VERSION "HNNBNNNYNNNNNNNNNNNNNNNNNNNNNNNNNNNNNNNNNN/4/%%%/4/'%**4NNN///"

NS_ :

BS_:

BU_: BAP_Tester BMS_NV_12V Gateway_Max Klima

BO_ 2463978703 HVLM_GBT_01: 64 Gateway_Max
 SG_ HVLM_GBT_01_BZ : 8|4@1+ (1,0) [0|15] ""  Vector__XXX
 SG_ HVLM_GBT_01_Sendestatus : 12|1@1+ (1.0,0.0) [0.0|1] ""  Vector__XXX
 SG_ HVLM_GBT_Status_Control : 13|1@1+ (1.0,0.0) [0.0|1] ""  Vector__XXX
 SG_ HVLM_GBT_SendeAnf_BCL : 14|1@1+ (1.0,0.0) [0.0|1] ""  Vector__XXX
 SG_ HVLM_GBT_SendeAnf_BCP : 15|1@1+ (1.0,0.0) [0.0|1] ""  Vector__XXX
 SG_ HVLM_GBT_SendeAnf_BCS : 16|1@1+ (1.0,0.0) [0.0|1] ""  Vector__XXX
 SG_ HVLM_GBT_SendeAnf_BEM : 17|1@1+ (1.0,0.0) [0.0|1] ""  Vector__XXX
 SG_ HVLM_GBT_SendeAnf_BHM : 18|1@1+ (1.0,0.0) [0.0|1] ""  Vector__XXX
 SG_ HVLM_GBT_SendeAnf_BRM : 19|1@1+ (1.0,0.0) [0.0|1] ""  Vector__XXX
 SG_ HVLM_GBT_SendeAnf_BRO : 20|1@1+ (1.0,0.0) [0.0|1] ""  Vector__XXX
 SG_ HVLM_GBT_SendeAnf_BSD : 21|1@1+ (1.0,0.0) [0.0|1] ""  Vector__XXX
 SG_ HVLM_GBT_SendeAnf_BSM : 22|1@1+ (1.0,0.0) [0.0|1] ""  Vector__XXX
 SG_ HVLM_GBT_SendeAnf_BST : 23|1@1+ (1.0,0.0) [0.0|1] ""  Vector__XXX
 SG_ HVLM_GBT_HvBatt_MaxLadespannung : 24|14@1+ (0.1,0) [0.0|1500.0] "Unit_Volt"  Vector__XXX
 SG_ HVLM_GBT_BEM_Timeout_CCS : 50|2@1+ (1.0,0.0) [0.0|3] ""  Vector__XXX
 SG_ HVLM_GBT_BEM_Timeout_CML : 52|2@1+ (1.0,0.0) [0.0|3] ""  Vector__XXX
 SG_ HVLM_GBT_BEM_Timeout_CRMnReady : 54|2@1+ (1.0,0.0) [0.0|3] ""  Vector__XXX
 SG_ HVLM_GBT_BEM_Timeout_CRMReady : 56|2@1+ (1.0,0.0) [0.0|3] ""  Vector__XXX
 SG_ HVLM_GBT_BEM_Timeout_CRO : 58|2@1+ (1.0,0.0) [0.0|3] ""  Vector__XXX
 SG_ HVLM_GBT_BEM_Timeout_CSD : 60|2@1+ (1.0,0.0) [0.0|3] ""  Vector__XXX
 SG_ HVLM_GBT_BEM_Timeout_CST : 62|2@1+ (1.0,0.0) [0.0|3] ""  Vector__XXX
 SG_ HVLM_GBT_BCL_Sollspannung : 64|14@1+ (0.1,0) [0.0|1500.0] "Unit_Volt"  Vector__XXX
 SG_ HVLM_GBT_BCL_Ladeverfahren : 78|2@1+ (1.0,0.0) [0.0|3] ""  Vector__XXX
 SG_ HVLM_GBT_BCL_Sollstrom : 80|14@1+ (0.1,-400) [-400.0|1000.0] "Unit_Amper"  Vector__XXX
 SG_ HVLM_GBT_BCP_StartSOC : 94|10@1+ (0.1,0) [0.0|100.0] "Unit_PerCent"  Vector__XXX
 SG_ HVLM_GBT_BCP_Ist_Spannung_HvBatt : 104|14@1+ (0.1,0) [0.0|1500.0] "Unit_Volt"  Vector__XXX
 SG_ HVLM_GBT_BCP_MaxLadestrom_Fzg : 118|14@1+ (0.1,-400) [-400.0|1000.0] "Unit_Amper"  Vector__XXX
 SG_ HVLM_GBT_BCP_MaxZellladespannung : 132|12@1+ (0.01,0) [0.00|24.00] "Unit_Volt"  Vector__XXX
 SG_ HVLM_GBT_BCP_MaxTemperatur : 144|8@1+ (1,-50) [-50|200] "Unit_DegreCelsi"  Vector__XXX
 SG_ HVLM_GBT_BCP_Nennenergiegehalt : 152|14@1+ (0.1,0) [0.0|1000.0] "Unit_KiloWattHour"  Vector__XXX
 SG_ HVLM_GBT_BCS_Ist_Restladezeit : 166|10@1+ (1,0) [0|600] "Unit_Minut"  Vector__XXX
 SG_ HVLM_GBT_BCS_Ist_Ladespannung : 176|14@1+ (0.1,0) [0.0|1500.0] "Unit_Volt"  Vector__XXX
 SG_ HVLM_GBT_BCS_Ist_Ladestrom : 190|14@1+ (0.1,-400) [-400.0|1000.0] "Unit_Amper"  Vector__XXX
 SG_ HVLM_GBT_BCS_IstSOC : 204|7@1+ (1,0) [0|100] "Unit_PerCent"  Vector__XXX
 SG_ HVLM_GBT_BCS_GruppenNr_Uzellmax : 211|5@1+ (1,0) [0|16] "Unit_None"  Vector__XXX
 SG_ HVLM_GBT_BCS_Ist_MaxZellspannung : 216|12@1+ (0.01,0) [0.00|24.00] "Unit_Volt"  Vector__XXX
 SG_ HVLM_GBT_BRM_Nennkapazitaet : 228|12@1+ (0.1,0) [0.0|250.0] "Unit_AmperHour"  Vector__XXX
 SG_ HVLM_GBT_BRM_Batterietyp : 240|8@1+ (1.0,0.0) [0.0|255] ""  Vector__XXX
 SG_ HVLM_GBT_BRM_ProtokollVersion : 248|24@1+ (1,0) [0|16777215] "Unit_None"  Vector__XXX
 SG_ HVLM_GBT_BRM_Nennspannung_HvBatt : 272|14@1+ (0.1,0) [0.0|1500.0] "Unit_Volt"  Vector__XXX
 SG_ HVLM_GBT_BRO_FzgBereitschaft : 288|8@1+ (1.0,0.0) [0.0|255] ""  Vector__XXX
 SG_ HVLM_GBT_BSD_EndSOC : 296|7@1+ (1,0) [0|100] "Unit_PerCent"  Vector__XXX
 SG_ HVLM_GBT_BSM_FzgLadeerlaubnis : 303|1@1+ (1.0,0.0) [0.0|1] ""  Vector__XXX
 SG_ HVLM_GBT_BSD_MaxTemperatur : 304|8@1+ (1,-50) [-50|200] "Unit_DegreCelsi"  Vector__XXX
 SG_ HVLM_GBT_BSD_MinTemperatur : 312|8@1+ (1,-50) [-50|200] "Unit_DegreCelsi"  Vector__XXX
 SG_ HVLM_GBT_BSD_MaxZellspannung : 320|12@1+ (0.01,0) [0.00|24.00] "Unit_Volt"  Vector__XXX
 SG_ HVLM_GBT_BSD_MinZellspannung : 332|12@1+ (0.01,0) [0.00|24.00] "Unit_Volt"  Vector__XXX
 SG_ HVLM_GBT_BSM_Ist_MaxTemperatur : 344|8@1+ (1,-50) [-50|200] "Unit_DegreCelsi"  Vector__XXX
 SG_ HVLM_GBT_BSM_Ist_MinTemperatur : 352|8@1+ (1,-50) [-50|200] "Unit_DegreCelsi"  Vector__XXX
 SG_ HVLM_GBT_BSM_Messpunkt_MaxT : 360|7@1+ (1,1) [1|128] "Unit_None"  Vector__XXX
 SG_ HVLM_GBT_BSM_Messpunkt_MinT : 367|7@1+ (1,1) [1|128] "Unit_None"  Vector__XXX
 SG_ HVLM_GBT_BSM_Status_Iso : 374|2@1+ (1.0,0.0) [0.0|3] ""  Vector__XXX
 SG_ HVLM_GBT_BSM_Nr_MaxZellspannung : 376|8@1+ (1,1) [1|256] "Unit_None"  Vector__XXX
 SG_ HVLM_GBT_BSM_Status_SOC : 384|2@1+ (1.0,0.0) [0.0|3] ""  Vector__XXX
 SG_ HVLM_GBT_BSM_Status_Stecker : 386|2@1+ (1.0,0.0) [0.0|3] ""  Vector__XXX
 SG_ HVLM_GBT_BSM_Status_Strom : 388|2@1+ (1.0,0.0) [0.0|3] ""  Vector__XXX
 SG_ HVLM_GBT_BSM_Status_Temperatur : 390|2@1+ (1.0,0.0) [0.0|3] ""  Vector__XXX
 SG_ HVLM_GBT_BSM_Status_Zellspannung : 392|2@1+ (1.0,0.0) [0.0|3] ""  Vector__XXX
 SG_ HVLM_GBT_BCS_GroupNr_Uzellmax_v2 : 480|4@1+ (1,0) [0|15] "Unit_None"  Vector__XXX
 SG_ HVLM_GBT_BST_Ladeende_Fehler_I : 484|2@1+ (1.0,0.0) [0.0|3] ""  Vector__XXX
 SG_ HVLM_GBT_BST_Ladeende_Fehler_U : 486|2@1+ (1.0,0.0) [0.0|3] ""  Vector__XXX
 SG_ HVLM_GBT_BST_Ladeende_Fehler1 : 488|2@1+ (1.0,0.0) [0.0|3] ""  Vector__XXX
 SG_ HVLM_GBT_BST_Ladeende_Fehler2 : 490|2@1+ (1.0,0.0) [0.0|3] ""  Vector__XXX
 SG_ HVLM_GBT_BST_Ladeende_Fehler3 : 492|2@1+ (1.0,0.0) [0.0|3] ""  Vector__XXX
 SG_ HVLM_GBT_BST_Ladeende_Fehler4 : 494|2@1+ (1.0,0.0) [0.0|3] ""  Vector__XXX
 SG_ HVLM_GBT_BST_Ladeende_Fehler5 : 496|2@1+ (1.0,0.0) [0.0|3] ""  Vector__XXX
 SG_ HVLM_GBT_BST_Ladeende_Fehler6 : 498|2@1+ (1.0,0.0) [0.0|3] ""  Vector__XXX
 SG_ HVLM_GBT_BST_Ladeende_Fehler7 : 500|2@1+ (1.0,0.0) [0.0|3] ""  Vector__XXX
 SG_ HVLM_GBT_BST_Ladeende_Fehler8 : 502|2@1+ (1.0,0.0) [0.0|3] ""  Vector__XXX
 SG_ HVLM_GBT_BST_Ladeende1_Fahrzeug : 504|2@1+ (1.0,0.0) [0.0|3] ""  Vector__XXX
 SG_ HVLM_GBT_BST_Ladeende2_Fahrzeug : 506|2@1+ (1.0,0.0) [0.0|3] ""  Vector__XXX
 SG_ HVLM_GBT_BST_Ladeende3_Fahrzeug : 508|2@1+ (1.0,0.0) [0.0|3] ""  Vector__XXX
 SG_ HVLM_GBT_BST_Ladeende4_Fahrzeug : 510|2@1+ (1.0,0.0) [0.0|3] ""  Vector__XXX

BO_ 2463978877 HVLM_GBT_01_SOK_Signatur_02: 8 Gateway_Max
 SG_ SOK_HVLM_GBT_01_Signatur_02 : 0|64@1+ (1,0) [1|18446744073709551615] "Unit_None"  Vector__XXX

BO_ 2463978707 HVLM_PLC_01: 24 Gateway_Max
 SG_ HVLM_PLC_01_BZ : 8|4@1+ (1,0) [0|15] ""  Vector__XXX
 SG_ HVLM_PlcModemAktivieren : 12|2@1+ (1.0,0.0) [0.0|3] ""  Vector__XXX
 SG_ HVLM_ZahlungsmethodeFzgPlc : 14|2@1+ (1.0,0.0) [0.0|3] ""  Vector__XXX
 SG_ HVLM_maxLadestromFzgPlc : 16|13@1+ (0.1,-400) [-400.0|400.0] "Unit_Amper"  Vector__XXX
 SG_ HVLM_TLS_PnC_Authenfizierung : 29|3@1+ (1.0,0.0) [0.0|7] ""  Vector__XXX
 SG_ HVLM_SollstromFzgPlc_2 : 32|14@1+ (0.1,-400) [-400.0|1000.0] "Unit_Amper"  Vector__XXX
 SG_ HVLM_PlcKommLadedose : 46|2@1+ (1.0,0.0) [0.0|3] ""  Vector__XXX
 SG_ HVLM_ZielladespannungFzgPlc : 48|14@1+ (0.1,0) [0.0|1500.0] "Unit_Volt"  Vector__XXX
 SG_ HVLM_PlcAnforderung : 62|2@1+ (1.0,0.0) [0.0|3] ""  Vector__XXX
 SG_ HVLM_RestladezeitFzgPlc : 64|12@1+ (1,0) [0|2880] "Unit_Minut"  Vector__XXX
 SG_ HVLM_RestladezeitTeilladungPlc : 76|12@1+ (1,0) [0|2880] "Unit_Minut"  Vector__XXX
 SG_ HVLM_LadezustandHvBatFzgPlc : 88|7@1+ (1,0) [0|100] "Unit_PerCent"  Vector__XXX
 SG_ HVLM_LadebereitFzgPlc : 95|1@1+ (1.0,0.0) [0.0|1] ""  Vector__XXX
 SG_ HVLM_maxLadespannungFzgPlc : 96|14@1+ (0.1,0) [0.0|1500.0] "Unit_Volt"  Vector__XXX
 SG_ HVLM_LadeartAnfFzgPlc : 110|3@1+ (1.0,0.0) [0.0|7] ""  Vector__XXX
 SG_ HVLM_MsgTriggerFzgPlc : 113|7@1+ (1.0,0.0) [0.0|127] ""  Vector__XXX
 SG_ HVLM_FehlerFzgPlc : 120|4@1+ (1.0,0.0) [0.0|15] ""  Vector__XXX
 SG_ HVLM_ReadyToChargeState : 124|2@1+ (1.0,0.0) [0.0|3] ""  Vector__XXX
 SG_ HVLM_LadenAbgeschlPlc : 126|2@1+ (1.0,0.0) [0.0|3] ""  Vector__XXX
 SG_ HVLM_LadeSessionPlc : 128|2@1+ (1.0,0.0) [0.0|3] ""  Vector__XXX
 SG_ HVLM_minLadestromFzgPlc : 130|10@1+ (0.1,0) [0.0|63.0] "Unit_Amper"  Vector__XXX
 SG_ HVLM_NormFzgPlc : 140|3@1+ (1.0,0.0) [0.0|7] ""  Vector__XXX
 SG_ HVLM_AnforderungPLTabellen : 143|1@1+ (1.0,0.0) [0.0|1] ""  Vector__XXX
 SG_ HVLM_maxLadestromFzgPlc_2 : 144|14@1+ (0.1,-400) [-400.0|1000.0] "Unit_Amper"  Vector__XXX

BO_ 2463978798 HVLM_PLC_01_SOK_Signatur: 4 Gateway_Max
 SG_ SOK_HVLM_PLC_01_Signatur : 0|32@1+ (1,0) [1|4294967295] "Unit_None"  Vector__XXX

BO_ 2589283690 IPB_03: 16 Vector__XXX
 SG_ LAD_OBD_Lampe_Anf : 23|1@1+ (1.0,0.0) [0.0|1] ""  Gateway_Max
 SG_ IPB_ThermAuslastungsgrad : 24|8@1+ (1,0) [0|100] "Unit_PerCent"  Gateway_Max
 SG_ TNV_Temperatur : 32|8@1+ (1,-40) [-40|213] "Unit_PerCent"  Gateway_Max
 SG_ IPB_Wasser_TEMP_EIN : 40|8@1+ (1,-40) [-40|213] "Unit_DegreCelsi"  Gateway_Max
 SG_ IPB_Wasser_TEMP_AUS : 48|8@1+ (1,-40) [-40|213] "Unit_DegreCelsi"  Gateway_Max
 SG_ HVLE_Temperatur : 56|8@1+ (1,-40) [-40|213] "Unit_DegreCelsi"  Gateway_Max
 SG_ HVLE_ThermAuslastungsgrad : 64|8@1+ (1,0) [0|100] "Unit_PerCent"  Gateway_Max
 SG_ HVLE_eTM_max_Vorlauftemperatur : 72|8@1+ (1,-40) [-40|213] "Unit_DegreCelsi"  Gateway_Max
 SG_ OBDProtocol_Ladegeraet : 88|8@1+ (1.0,0.0) [0.0|255] ""  Gateway_Max

BO_ 2589283695 IPB_03_SOK_Signatur: 8 Vector__XXX
 SG_ SOK_IPB_03_Signatur : 0|64@1+ (1,0) [1|18446744073709551615] "Unit_None"  Gateway_Max

BO_ 1857 ISO_DCDC_Req: 8 Gateway_Max
 SG_ ISO_DCDC_Req_Data : 0|64@1+ (1.0,0.0) [0.0|18446744073709551615] ""  Vector__XXX

BO_ 1963 ISO_DCDC_Resp: 8 Vector__XXX
 SG_ ISO_DCDC_Resp_Data : 0|64@1+ (1.0,0.0) [0.0|18446744073709551615] ""  Gateway_Max

BO_ 1792 ISO_Funktionaler_Req_All: 8 Gateway_Max
 SG_ ISO_ALL_01_Req_Data : 0|64@1+ (1.0,0.0) [0.0|18446744073709551615] ""  BMS_NV_12V,Klima

BO_ 1862 ISO_Klima_Req: 8 Gateway_Max
 SG_ ISO_Klima_Req_Data : 0|64@1+ (1.0,0.0) [0.0|18446744073709551615] ""  Klima

BO_ 1968 ISO_Klima_Resp: 8 Klima
 SG_ ISO_Klima_Resp_Data : 0|64@1+ (1.0,0.0) [0.0|18446744073709551615] ""  Gateway_Max

BO_ 1860 ISO_Ladegeraet_Req: 8 Gateway_Max
 SG_ ISO_Ladegeraet_Req_Data : 0|64@1+ (1.0,0.0) [0.0|18446744073709551615] ""  Vector__XXX

BO_ 1966 ISO_Ladegeraet_Resp: 8 Vector__XXX
 SG_ ISO_Ladegeraet_Resp_Data : 0|64@1+ (1.0,0.0) [0.0|18446744073709551615] ""  Gateway_Max

BO_ 2463978775 ISOND_01: 64 Vector__XXX
 SG_ HVLX_Isond_maxAcEigenstromL1 : 12|10@1+ (0.1,0) [0.0|100.0] "Unit_Amper"  Gateway_Max
 SG_ HVLX_Isond_maxAcEigenstromL2 : 22|10@1+ (0.1,0) [0.0|100.0] "Unit_Amper"  Gateway_Max
 SG_ HVLX_Isond_maxAcEigenstromL3 : 32|10@1+ (0.1,0) [0.0|100.0] "Unit_Amper"  Gateway_Max
 SG_ HVLX_Isond_maxAcAbgabestromL1 : 42|10@1+ (0.1,0) [0.0|100.0] "Unit_Amper"  Gateway_Max
 SG_ HVLX_Isond_maxAcAbgabestromL2 : 52|10@1+ (0.1,0) [0.0|100.0] "Unit_Amper"  Gateway_Max
 SG_ HVLX_Isond_maxAcAbgabestromL3 : 62|10@1+ (0.1,0) [0.0|100.0] "Unit_Amper"  Gateway_Max
 SG_ HVLX_Isond_MaxStromACLsPlc : 72|10@1+ (0.1,0) [0.0|100.0] "Unit_Amper"  Gateway_Max
 SG_ HVLX_Isond_maxStromLadesaeule : 82|14@1+ (0.1,-400) [-400.0|1000.0] "Unit_Amper"  Gateway_Max
 SG_ HVLX_Isond_minStromLadesaeule : 96|14@1+ (0.1,-400) [-400.0|1000.0] "Unit_Amper"  Gateway_Max
 SG_ HVLX_Isond_maxSpannungLadesaeule : 110|14@1+ (0.1,0) [0.0|1500.0] "Unit_Volt"  Gateway_Max
 SG_ HVLX_Isond_minSpannungLadesaeule : 124|14@1+ (0.1,0) [0.0|1500.0] "Unit_Volt"  Gateway_Max
 SG_ HVLX_Isond_IstSpannungLadesaeule : 138|14@1+ (0.1,0) [0.0|1500.0] "Unit_Volt"  Gateway_Max
 SG_ HVLX_Isond_IstStromLadesaeule : 152|14@1+ (0.1,-400) [-400.0|1000.0] "Unit_Amper"  Gateway_Max
 SG_ HVLX_Isond_StromrippelPeakLs : 166|12@1+ (0.1,0) [0.0|300.0] "Unit_Amper"  Gateway_Max
 SG_ HVLX_Isond_IstSpannungACLsPlc : 178|9@1+ (1,0) [0|500] "Unit_Volt"  Gateway_Max
 SG_ HVLX_Isond_maxLeistungLadesaeule : 187|17@1+ (10,-327670) [-327670|972330] "Unit_Watt"  Gateway_Max
 SG_ HVLX_Isond_maxStromErreicht : 204|2@1+ (1.0,0.0) [0.0|3] ""  Gateway_Max
 SG_ HVLX_Isond_maxSpannungErreicht : 206|2@1+ (1.0,0.0) [0.0|3] ""  Gateway_Max
 SG_ HVLX_Isond_maxLeistungErreicht : 208|2@1+ (1.0,0.0) [0.0|3] ""  Gateway_Max
 SG_ HVLX_Isond_NormLsPlc : 210|3@1+ (1.0,0.0) [0.0|7] ""  Gateway_Max
 SG_ HVLX_Isond_TLS_PnC_Status : 213|3@1+ (1.0,0.0) [0.0|7] ""  Gateway_Max
 SG_ HVLX_Isond_ResponseCodeLsPlc : 216|6@1+ (1.0,0.0) [0.0|63] ""  Gateway_Max
 SG_ HVLX_Isond_IsoStatusLadesaeule : 222|2@1+ (1.0,0.0) [0.0|3] ""  Gateway_Max
 SG_ HVLX_Isond_PlcKommFehler : 224|3@1+ (1.0,0.0) [0.0|7] ""  Gateway_Max
 SG_ HVLX_ISOND_LOPStatus : 227|1@1+ (1.0,0.0) [0.0|1] ""  Vector__XXX
 SG_ HVLX_ISOND_FODStatus : 228|1@1+ (1.0,0.0) [0.0|1] ""  Vector__XXX
 SG_ HVLX_Isond_LadeartAC1PCorePlc : 229|1@1+ (1.0,0.0) [0.0|1] ""  Gateway_Max
 SG_ HVLX_Isond_LadeartAC3PCorePlc : 230|1@1+ (1.0,0.0) [0.0|1] ""  Gateway_Max
 SG_ HVLX_Isond_LadeartDCComboCorePlc : 231|1@1+ (1.0,0.0) [0.0|1] ""  Gateway_Max
 SG_ HVLX_Isond_LadeartDCCorePlc : 232|1@1+ (1.0,0.0) [0.0|1] ""  Gateway_Max
 SG_ HVLX_Isond_LadeartDCExtendedPlc : 233|1@1+ (1.0,0.0) [0.0|1] ""  Gateway_Max
 SG_ HVLX_Isond_LadeartDCUniquePlc : 234|1@1+ (1.0,0.0) [0.0|1] ""  Gateway_Max
 SG_ HVLX_Isond_ZahlungsmethodeLs : 235|2@1+ (1.0,0.0) [0.0|3] ""  Gateway_Max
 SG_ HVLX_Isond_StatusRcdACLsPlc : 237|2@1+ (1.0,0.0) [0.0|3] ""  Gateway_Max
 SG_ HVLX_Isond_ZahlererfassungAnfHlc : 239|1@1+ (1.0,0.0) [0.0|1] ""  Gateway_Max
 SG_ HVLX_Isond_PLC_Message_Status : 240|8@1+ (1.0,0.0) [0.0|255] ""  Gateway_Max
 SG_ HVLX_Isond_IstEnergiemengeLsPlc : 248|13@1+ (0.1,-400) [-400.0|400.0] "Unit_KiloWattHour"  Vector__XXX
 SG_ HVLX_Isond_PnCZertifkatErhaltHlc : 262|2@1+ (1.0,0.0) [0.0|3] ""  Gateway_Max
 SG_ HVLX_Isond_LadeplanErhaltenHlc : 264|2@1+ (1.0,0.0) [0.0|3] ""  Gateway_Max
 SG_ HVLX_Isond_SASTupelErhaltenHlc : 266|2@1+ (1.0,0.0) [0.0|3] ""  Gateway_Max
 SG_ HVLX_Isond_StatusLadesaeule : 268|4@1+ (1.0,0.0) [0.0|15] ""  Gateway_Max
 SG_ HVLX_Isond_EigenstromLadenStatus : 272|2@1+ (1.0,0.0) [0.0|3] ""  Gateway_Max
 SG_ HVLX_Isond_EVSEProcessing_Status : 274|3@1+ (1.0,0.0) [0.0|7] ""  Gateway_Max
 SG_ HVLX_Isond_VASBedAnzStatus_LsPlc : 277|1@1+ (1.0,0.0) [0.0|1] ""  Gateway_Max
 SG_ HVLX_Isond_VASErwLFStatus_LsPlc : 278|1@1+ (1.0,0.0) [0.0|1] ""  Gateway_Max
 SG_ HVLX_LSPLC_01_Sendestatus : 279|1@1+ (1.0,0.0) [0.0|1] ""  Gateway_Max
 SG_ HVLX_PlcFehlerstatus : 280|3@1+ (1.0,0.0) [0.0|7] ""  Gateway_Max
 SG_ HVLX_PlcGefundeneLadesaeule : 283|3@1+ (1,0) [0|7] "Unit_None"  Gateway_Max
 SG_ HVLX_PlcLinkStatus : 286|3@1+ (1.0,0.0) [0.0|7] ""  Gateway_Max
 SG_ HVLX_Isond_LsNotification_Plc : 289|3@1+ (1.0,0.0) [0.0|7] ""  Gateway_Max
 SG_ HVLX_ISOND_GALeistungNetz : 292|12@1+ (10,0) [0|40920] "Unit_Watt"  Vector__XXX
 SG_ HVLX_ISOND_GAFrequenz : 304|14@1+ (10,0) [0|163800] "Unit_Hertz"  Vector__XXX
 SG_ HVLX_ISOND_GADcLeistung : 318|12@1+ (10,0) [0|40920] "Unit_Watt"  Vector__XXX
 SG_ HVLX_ISOND_GASpulenstrom : 330|10@1+ (0.1,0) [0.0|102.0] "Unit_Amper"  Vector__XXX
 SG_ HVLX_ISOND_LeistungsanfEV : 340|12@1+ (10,0) [0|40920] "Unit_Watt"  Vector__XXX
 SG_ HVLX_ISOND_EVSEResponseMaxDelay : 352|16@1+ (1,0) [0|65531] "Unit_Secon"  Vector__XXX
 SG_ HVLX_Isond_WPT_VehiclePosStatus : 368|2@1+ (1.0,0.0) [0.0|3] ""  Vector__XXX
 SG_ HVLX_Isond_WPT_DevicePosStatus : 370|2@1+ (1.0,0.0) [0.0|3] ""  Vector__XXX
 SG_ HVLX_Isond_LadeartWpt : 372|1@1+ (1.0,0.0) [0.0|1] ""  Vector__XXX
 SG_ HVLX_ISOND_PncServiceDetailStat : 373|2@1+ (1.0,0.0) [0.0|3] ""  Vector__XXX
 SG_ HVLX_ISOND_PncServiceDiscovStat : 375|2@1+ (1.0,0.0) [0.0|3] ""  Vector__XXX
 SG_ HVLX_ISOND_PncZertifikateTrans : 377|2@1+ (1.0,0.0) [0.0|3] ""  Vector__XXX
 SG_ HVLX_maxEntladeLeistungLS : 379|17@1+ (10,0) [0|1300000] "Unit_Watt"  Vector__XXX
 SG_ HVLX_minEntladeStromLadesaeule : 396|14@1+ (0.1,0) [0.0|1600.0] "Unit_Amper"  Vector__XXX
 SG_ HVLX_maxEntladeStromLadesaeule : 410|14@1+ (0.1,0) [0.0|1600.0] "Unit_Amper"  Vector__XXX
 SG_ HVLX_GeneratorMode : 424|2@1+ (1.0,0.0) [0.0|3] ""  Vector__XXX
 SG_ HVLX_LadeartDCBptPlc : 426|2@1+ (1.0,0.0) [0.0|3] ""  Vector__XXX
 SG_ HVLX_Isond_TlsZertifkatErhaltHlc : 428|2@1+ (1.0,0.0) [0.0|3] ""  Gateway_Max
 SG_ HVLX_Isond_VasResponse : 430|5@1+ (1.0,0.0) [0.0|31] ""  Gateway_Max

BO_ 2549874844 ISOx_BMS_48V_Req: 8 Gateway_Max
 SG_ ISOx_BMS_48V_Req_Data : 0|64@1+ (1.0,0.0) [0.0|18446744073709551615] ""  Vector__XXX

BO_ 2621440156 ISOx_BMS_48V_Req_FD: 64 Gateway_Max
 SG_ ISOx_BMS_48V_Req_FD_Data : 0|512@1+ (1.0,0.0) [0.0|13407807929942597099574024998205846127479365820592393377723561443721764030073546976801874298166903427690031858186486050853753882811946569946433649006084095] ""  Vector__XXX

BO_ 2550005916 ISOx_BMS_48V_Resp: 8 Vector__XXX
 SG_ ISOx_BMS_48V_Resp_Data : 0|64@1+ (1.0,0.0) [0.0|18446744073709551615] ""  Gateway_Max

BO_ 2621571228 ISOx_BMS_48V_Resp_FD: 64 Vector__XXX
 SG_ ISOx_BMS_48V_Resp_FD_Data : 0|512@1+ (1.0,0.0) [0.0|13407807929942597099574024998205846127479365820592393377723561443721764030073546976801874298166903427690031858186486050853753882811946569946433649006084095] ""  Gateway_Max

BO_ 2550399045 ISOx_BMS_NV_Req: 8 Gateway_Max
 SG_ ISOx_BMS_NV_Req_Data : 0|64@1+ (1.0,0.0) [0.0|18446744073709551615] ""  BMS_NV_12V

BO_ 2621702213 ISOx_BMS_NV_Req_FD: 64 Gateway_Max
 SG_ ISOx_BMS_NV_Req_FD_Data : 0|512@1+ (1.0,0.0) [0.0|13407807929942597099574024998205846127479365820592393377723561443721764030073546976801874298166903427690031858186486050853753882811946569946433649006084095] ""  BMS_NV_12V

BO_ 2550530117 ISOx_BMS_NV_Resp: 8 BMS_NV_12V
 SG_ ISOx_BMS_NV_Resp_Data : 0|64@1+ (1.0,0.0) [0.0|18446744073709551615] ""  Gateway_Max

BO_ 2621833285 ISOx_BMS_NV_Resp_FD: 64 BMS_NV_12V
 SG_ ISOx_BMS_NV_Resp_FD_Data : 0|512@1+ (1.0,0.0) [0.0|13407807929942597099574024998205846127479365820592393377723561443721764030073546976801874298166903427690031858186486050853753882811946569946433649006084095] ""  Gateway_Max

BO_ 2549874873 ISOx_DCDC_NV_Req: 8 Gateway_Max
 SG_ ISOx_DCDC_NV_Req_Data : 0|64@1+ (1.0,0.0) [0.0|18446744073709551615] ""  Vector__XXX

BO_ 2621440185 ISOx_DCDC_NV_Req_FD: 64 Gateway_Max
 SG_ ISOx_DCDC_NV_Req_FD_Data : 0|512@1+ (1.0,0.0) [0.0|13407807929942597099574024998205846127479365820592393377723561443721764030073546976801874298166903427690031858186486050853753882811946569946433649006084095] ""  Vector__XXX

BO_ 2550005945 ISOx_DCDC_NV_Resp: 8 Vector__XXX
 SG_ ISOx_DCDC_NV_Resp_Data : 0|64@1+ (1.0,0.0) [0.0|18446744073709551615] ""  Gateway_Max

BO_ 2621571257 ISOx_DCDC_NV_Resp_FD: 64 Vector__XXX
 SG_ ISOx_DCDC_NV_Resp_FD_Data : 0|512@1+ (1.0,0.0) [0.0|13407807929942597099574024998205846127479365820592393377723561443721764030073546976801874298166903427690031858186486050853753882811946569946433649006084095] ""  Gateway_Max

BO_ 2621440065 ISOx_DCDC_Req_FD: 64 Gateway_Max
 SG_ ISOx_DCDC_Req_FD_Data : 0|512@1+ (1.0,0.0) [0.0|13407807929942597099574024998205846127479365820592393377723561443721764030073546976801874298166903427690031858186486050853753882811946569946433649006084095] ""  Vector__XXX

BO_ 2621571137 ISOx_DCDC_Resp_FD: 64 Vector__XXX
 SG_ ISOx_DCDC_Resp_FD_Data : 0|512@1+ (1.0,0.0) [0.0|13407807929942597099574024998205846127479365820592393377723561443721764030073546976801874298166903427690031858186486050853753882811946569946433649006084095] ""  Gateway_Max

BO_ 2621505536 ISOx_Funkt_Req_All_FD: 64 Gateway_Max
 SG_ ISOx_Funkt_Req_All_FD_Data : 0|512@1+ (1.0,0.0) [0.0|13407807929942597099574024998205846127479365820592393377723561443721764030073546976801874298166903427690031858186486050853753882811946569946433649006084095] ""  BMS_NV_12V,Klima

BO_ 2549874811 ISOx_Hybrid_01_Req: 8 Gateway_Max
 SG_ ISOx_Hybrid_01_Req_Data : 0|64@1+ (1.0,0.0) [0.0|18446744073709551615] ""  Vector__XXX

BO_ 2621440123 ISOx_Hybrid_01_Req_FD: 64 Gateway_Max
 SG_ ISOx_Hybrid_01_Req_FD_Data : 0|512@1+ (1.0,0.0) [0.0|13407807929942597099574024998205846127479365820592393377723561443721764030073546976801874298166903427690031858186486050853753882811946569946433649006084095] ""  Vector__XXX

BO_ 2550005883 ISOx_Hybrid_01_Resp: 8 Vector__XXX
 SG_ ISOx_Hybrid_01_Resp_Data : 0|64@1+ (1.0,0.0) [0.0|18446744073709551615] ""  Gateway_Max

BO_ 2621571195 ISOx_Hybrid_01_Resp_FD: 64 Vector__XXX
 SG_ ISOx_Hybrid_01_Resp_FD_Data : 0|512@1+ (1.0,0.0) [0.0|13407807929942597099574024998205846127479365820592393377723561443721764030073546976801874298166903427690031858186486050853753882811946569946433649006084095] ""  Gateway_Max

BO_ 2621440070 ISOx_Klima_Req_FD: 64 Gateway_Max
 SG_ ISOx_Klima_Req_FD_Data : 0|512@1+ (1.0,0.0) [0.0|13407807929942597099574024998205846127479365820592393377723561443721764030073546976801874298166903427690031858186486050853753882811946569946433649006084095] ""  Klima

BO_ 2621571142 ISOx_Klima_Resp_FD: 64 Klima
 SG_ ISOx_Klima_Resp_FD_Data : 0|512@1+ (1.0,0.0) [0.0|13407807929942597099574024998205846127479365820592393377723561443721764030073546976801874298166903427690031858186486050853753882811946569946433649006084095] ""  Gateway_Max

BO_ 2621440068 ISOx_Ladegeraet_Req_FD: 64 Gateway_Max
 SG_ ISOx_Ladegeraet_Req_FD_Data : 0|512@1+ (1.0,0.0) [0.0|13407807929942597099574024998205846127479365820592393377723561443721764030073546976801874298166903427690031858186486050853753882811946569946433649006084095] ""  Vector__XXX

BO_ 2621571140 ISOx_Ladegeraet_Resp_FD: 64 Vector__XXX
 SG_ ISOx_Ladegeraet_Resp_FD_Data : 0|512@1+ (1.0,0.0) [0.0|13407807929942597099574024998205846127479365820592393377723561443721764030073546976801874298166903427690031858186486050853753882811946569946433649006084095] ""  Gateway_Max

BO_ 2550399003 ISOx_SACID_1_Req: 8 Gateway_Max
 SG_ ISOx_SACID_1_Req_Data : 0|64@1+ (1.0,0.0) [0.0|18446744073709551615] ""  Vector__XXX

BO_ 2621702171 ISOx_SACID_1_Req_FD: 64 Gateway_Max
 SG_ ISOx_SACID_1_Req_FD_Data : 0|512@1+ (1.0,0.0) [0.0|13407807929942597099574024998205846127479365820592393377723561443721764030073546976801874298166903427690031858186486050853753882811946569946433649006084095] ""  Vector__XXX

BO_ 2550530075 ISOx_SACID_1_Resp: 8 Vector__XXX
 SG_ ISOx_SACID_1_Resp_Data : 0|64@1+ (1.0,0.0) [0.0|18446744073709551615] ""  Gateway_Max

BO_ 2621833243 ISOx_SACID_1_Resp_FD: 64 Vector__XXX
 SG_ ISOx_SACID_1_Resp_FD_Data : 0|512@1+ (1.0,0.0) [0.0|13407807929942597099574024998205846127479365820592393377723561443721764030073546976801874298166903427690031858186486050853753882811946569946433649006084095] ""  Gateway_Max

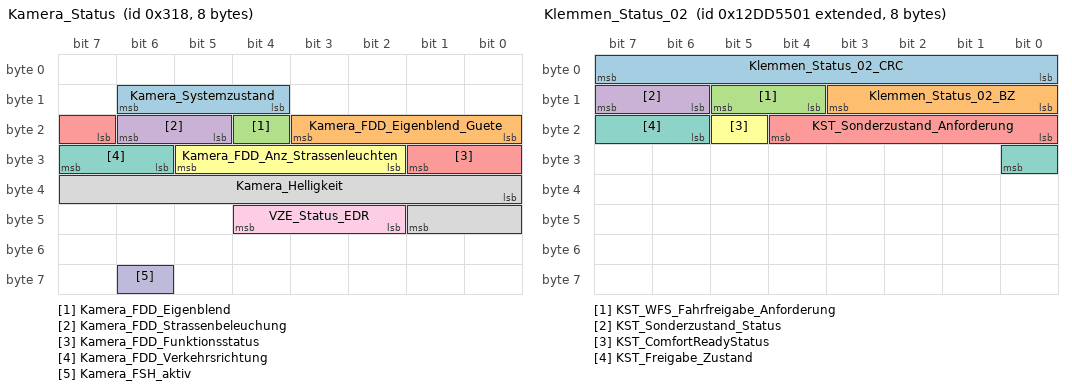
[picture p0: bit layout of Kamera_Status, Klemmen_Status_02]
BO_ 792 Kamera_Status: 8 Gateway_Max
 SG_ Kamera_Systemzustand : 12|3@1+ (1.0,0.0) [0.0|7] ""  Vector__XXX
 SG_ Kamera_FDD_Eigenblend_Guete : 16|4@1+ (10,0) [0|100] "Unit_PerCent"  Vector__XXX
 SG_ Kamera_FDD_Eigenblend : 20|1@1+ (1.0,0.0) [0.0|1] ""  Vector__XXX
 SG_ Kamera_FDD_Strassenbeleuchung : 21|2@1+ (1.0,0.0) [0.0|3] ""  Vector__XXX
 SG_ Kamera_FDD_Funktionsstatus : 23|3@1+ (1.0,0.0) [0.0|7] ""  Vector__XXX
 SG_ Kamera_FDD_Anz_Strassenleuchten : 26|4@1+ (1,0) [0|14] ""  Vector__XXX
 SG_ Kamera_FDD_Verkehrsrichtung : 30|2@1+ (1.0,0.0) [0.0|3] ""  Vector__XXX
 SG_ Kamera_Helligkeit : 32|10@1+ (10,0) [0|10000] "Unit_Lux"  Vector__XXX
 SG_ VZE_Status_EDR : 42|3@1+ (1.0,0.0) [0.0|7] ""  Vector__XXX
 SG_ Kamera_FSH_aktiv : 62|1@1+ (1.0,0.0) [0.0|1] ""  Klima

BO_ 960 Klemmen_Status_01: 4 Gateway_Max
 SG_ Klemmen_Status_01_CRC : 0|8@1+ (1,0) [0|255] ""  Vector__XXX
 SG_ Klemmen_Status_01_BZ : 8|4@1+ (1,0) [0|15] ""  Vector__XXX
 SG_ RSt_Fahrerhinweise : 12|4@1+ (1.0,0.0) [0.0|15] ""  Vector__XXX
 SG_ ZAS_Kl_S : 16|1@1+ (1.0,0.0) [0.0|1] ""  Klima
 SG_ ZAS_Kl_15 : 17|1@1+ (1.0,0.0) [0.0|1] ""  BMS_NV_12V,Klima
 SG_ ZAS_Kl_X : 18|1@1+ (1.0,0.0) [0.0|1] ""  Vector__XXX
 SG_ ZAS_Kl_50_Startanforderung : 19|1@1+ (1.0,0.0) [0.0|1] ""  Vector__XXX
 SG_ BCM_Remotestart_Betrieb : 20|1@1+ (1.0,0.0) [0.0|1] ""  Klima
 SG_ ZAS_Kl_Infotainment : 21|1@1+ (1.0,0.0) [0.0|1] ""  Vector__XXX
 SG_ BCM_Remotestart_KL15_Anf : 22|1@1+ (1.0,0.0) [0.0|1] ""  Vector__XXX
 SG_ BCM_Remotestart_MO_Start : 23|1@1+ (1.0,0.0) [0.0|1] ""  Vector__XXX
 SG_ KST_Warn_P1_ZST_def : 24|1@1+ (1.0,0.0) [0.0|1] ""  Vector__XXX
 SG_ KST_Warn_P2_ZST_def : 25|1@1+ (1.0,0.0) [0.0|1] ""  Vector__XXX
 SG_ KST_Fahrerhinweis_1 : 26|1@1+ (1.0,0.0) [0.0|1] ""  Klima
 SG_ KST_Fahrerhinweis_2 : 27|1@1+ (1.0,0.0) [0.0|1] ""  Klima
 SG_ BCM_Ausparken_Betrieb : 28|1@1+ (1.0,0.0) [0.0|1] ""  Vector__XXX
 SG_ KST_Fahrerhinweis_4 : 29|1@1+ (1.0,0.0) [0.0|1] ""  Vector__XXX
 SG_ KST_Fahrerhinweis_5 : 30|1@1+ (1.0,0.0) [0.0|1] ""  Klima
 SG_ KST_Fahrerhinweis_6 : 31|1@1+ (1.0,0.0) [0.0|1] ""  Klima

BO_ 2463978753 Klemmen_Status_02: 8 Gateway_Max
 SG_ Klemmen_Status_02_CRC : 0|8@1+ (1,0) [0|255] ""  Vector__XXX
 SG_ Klemmen_Status_02_BZ : 8|4@1+ (1,0) [0|15] ""  Vector__XXX
 SG_ KST_WFS_Fahrfreigabe_Anforderung : 12|2@1+ (1.0,0.0) [0.0|3] ""  Vector__XXX
 SG_ KST_Sonderzustand_Status : 14|2@1+ (1.0,0.0) [0.0|3] ""  Klima
 SG_ KST_Sonderzustand_Anforderung : 16|5@1+ (1.0,0.0) [0.0|31] ""  Klima
 SG_ KST_ComfortReadyStatus : 21|1@1+ (1.0,0.0) [0.0|1] ""  Vector__XXX
 SG_ KST_Freigabe_Zustand : 22|3@1+ (1.0,0.0) [0.0|7] ""  Vector__XXX

BO_ 1646 Klima_03: 8 Klima
 SG_ KL_STL_aktiv : 0|1@1+ (1.0,0.0) [0.0|1] ""  Gateway_Max
 SG_ KL_STH_aktiv : 1|1@1+ (1.0,0.0) [0.0|1] ""  Gateway_Max
 SG_ KL_Solarluefter_aktiv : 2|1@1+ (1.0,0.0) [0.0|1] ""  Gateway_Max
 SG_ KL_Umluft_Taste : 3|1@1+ (1.0,0.0) [0.0|1] ""  Gateway_Max
 SG_ KL_Geblaese_Fond_Status : 4|4@1+ (1.0,0.0) [0.0|15] ""  Gateway_Max
 SG_ KL_STH_Ansteuerung : 8|2@1+ (1.0,0.0) [0.0|3] ""  Gateway_Max
 SG_ KL_STH_Betriebsdauer : 10|6@1+ (1,0) [0|60] "Unit_Minut"  Gateway_Max
 SG_ KL_Magnetventil : 16|1@1+ (1.0,0.0) [0.0|1] ""  Gateway_Max
 SG_ KL_WaPu : 17|1@1+ (1.0,0.0) [0.0|1] ""  Gateway_Max
 SG_ KL_Geblaese_Status : 18|4@1+ (1.0,0.0) [0.0|15] ""  Gateway_Max
 SG_ KL_Restwaerme_aktiv : 22|1@1+ (1.0,0.0) [0.0|1] ""  Gateway_Max
 SG_ KL_Kompressorkupplung : 23|1@1+ (1.0,0.0) [0.0|1] ""  Gateway_Max
 SG_ KL_BCmE_Livetip_Freigabe : 24|1@1+ (1.0,0.0) [0.0|1] ""  Gateway_Max
 SG_ KL_SH_Soll_hl : 25|3@1+ (1.0,0.0) [0.0|7] ""  Gateway_Max
 SG_ KL_SH_Soll_hr : 28|3@1+ (1.0,0.0) [0.0|7] ""  Gateway_Max
 SG_ KL_ErwVK_Anf : 31|1@1+ (1.0,0.0) [0.0|1] ""  Gateway_Max
 SG_ KL_Innen_Temp : 32|8@1+ (0.5,-50) [-50.0|76.0] "Unit_DegreCelsi"  Gateway_Max
 SG_ KL_I_Geblaese_Fond : 40|8@1+ (0.25,0) [0.00|63.50] "Unit_Amper"  Gateway_Max
 SG_ KL_Anf_AussenspiegelHzg : 48|1@1+ (1.0,0.0) [0.0|1] ""  Gateway_Max
 SG_ KL_Heizkreisventilstellung : 49|2@1+ (1.0,0.0) [0.0|3] ""  Gateway_Max
 SG_ KL_FSH_Automatikbetrieb : 51|1@1+ (1.0,0.0) [0.0|1] ""  Gateway_Max
 SG_ KL_SIH_LEH_Verteilung_VL : 52|3@1+ (1.0,0.0) [0.0|7] ""  Gateway_Max
 SG_ KL_SIH_LEL_Verteilung_VL : 55|3@1+ (1.0,0.0) [0.0|7] ""  Gateway_Max
 SG_ KL_SIH_LEH_Verteilung_VR : 58|3@1+ (1.0,0.0) [0.0|7] ""  Gateway_Max
 SG_ KL_SIH_LEL_Verteilung_VR : 61|3@1+ (1.0,0.0) [0.0|7] ""  Gateway_Max

BO_ 1649 Klima_06: 8 Klima
 SG_ KL_ZZ_Minute : 0|6@1+ (1,0) [0|59] "Unit_Minut"  Gateway_Max
 SG_ KL_ZZ_Status_Timer : 6|2@1+ (1.0,0.0) [0.0|3] ""  Gateway_Max
 SG_ KL_ZZ_Monat : 8|4@1+ (1,0) [1|12] "Unit_Month"  Gateway_Max
 SG_ KL_ErwVK_Scheibenheizung : 12|1@1+ (1.0,0.0) [0.0|1] ""  Gateway_Max
 SG_ KL_ErwVK_Heckzone2_links : 13|1@1+ (1.0,0.0) [0.0|1] ""  Gateway_Max
 SG_ KL_ErwVK_Heckzone2_rechts : 14|1@1+ (1.0,0.0) [0.0|1] ""  Gateway_Max
 SG_ KL_ZZ_Stunde : 16|5@1+ (1,0) [0|23] "Unit_Hours"  Gateway_Max
 SG_ KL_ZZ_Betriebsmodus : 21|3@1+ (1.0,0.0) [0.0|7] ""  Gateway_Max
 SG_ KL_ZZ_Tag : 24|5@1+ (1,0) [1|31] "Unit_Day"  Gateway_Max
 SG_ KL_Betriebsmodus_FH : 29|3@1+ (1.0,0.0) [0.0|7] ""  Gateway_Max
 SG_ KL_Stopp_Wiederstart_Anz_01 : 32|1@1+ (1.0,0.0) [0.0|1] ""  Gateway_Max
 SG_ KL_Stopp_Wiederstart_Anz_02 : 33|1@1+ (1.0,0.0) [0.0|1] ""  Gateway_Max
 SG_ KL_Stopp_Wiederstart_Anz_03 : 34|1@1+ (1.0,0.0) [0.0|1] ""  Gateway_Max
 SG_ KL_Stopp_Wiederstart_Anz_04 : 35|1@1+ (1.0,0.0) [0.0|1] ""  Gateway_Max
 SG_ KL_Stopp_Wiederstart_Anz_05 : 36|1@1+ (1.0,0.0) [0.0|1] ""  Gateway_Max
 SG_ KL_Stopp_Wiederstart_Anz_06 : 37|1@1+ (1.0,0.0) [0.0|1] ""  Gateway_Max
 SG_ KL_Stopp_Wiederstart_Anz_07 : 38|1@1+ (1.0,0.0) [0.0|1] ""  Gateway_Max
 SG_ KL_Stopp_Wiederstart_Anz_08 : 39|1@1+ (1.0,0.0) [0.0|1] ""  Gateway_Max
 SG_ KL_Stopp_Wiederstart_Anz_09 : 40|1@1+ (1.0,0.0) [0.0|1] ""  Gateway_Max
 SG_ KL_Stopp_Wiederstart_Anz_Std1 : 41|1@1+ (1.0,0.0) [0.0|1] ""  Gateway_Max
 SG_ KL_Stopp_Wiederstart_Anz_Std2 : 42|1@1+ (1.0,0.0) [0.0|1] ""  Gateway_Max
 SG_ KL_STH_Betriebsdauer_lang : 43|7@1+ (1,0) [0|120] "Unit_Minut"  Gateway_Max
 SG_ KL_Meldung_Status : 50|4@1+ (1.0,0.0) [0.0|15] ""  Gateway_Max
 SG_ KL_ErwVK_Status : 54|4@1+ (1.0,0.0) [0.0|15] ""  Gateway_Max
 SG_ KL_Hinweis_Kuehlmodus : 58|2@1+ (1.0,0.0) [0.0|3] ""  Gateway_Max
 SG_ KL_ErwVK_Beifahrerzone : 60|1@1+ (1.0,0.0) [0.0|1] ""  Gateway_Max
 SG_ KL_ErwVK_Fahrerzone : 61|1@1+ (1.0,0.0) [0.0|1] ""  Gateway_Max
 SG_ KL_ErwVK_Heckzone_links : 62|1@1+ (1.0,0.0) [0.0|1] ""  Gateway_Max
 SG_ Kl_ErwVK_Heckzone_rechts : 63|1@1+ (1.0,0.0) [0.0|1] ""  Gateway_Max

BO_ 949 Klima_11: 8 Klima
 SG_ KL_Drehz_Anh : 0|1@1+ (1.0,0.0) [0.0|1] ""  Gateway_Max
 SG_ KL_Vorwarn_Komp_ein : 1|1@1+ (1.0,0.0) [0.0|1] ""  Gateway_Max
 SG_ KL_AC_Schalter : 2|1@1+ (1.0,0.0) [0.0|1] ""  Gateway_Max
 SG_ KL_Komp_Moment_alt : 3|1@1+ (1.0,0.0) [0.0|1] ""  Gateway_Max
 SG_ KL_Vorwarn_Zuheizer_ein : 6|1@1+ (1.0,0.0) [0.0|1] ""  Gateway_Max
 SG_ KL_Zustand : 7|1@1+ (1.0,0.0) [0.0|1] ""  Gateway_Max
 SG_ KL_Kompressorkupplung_linear : 8|8@1+ (20,0) [0|4000] "Unit_MilliAmper"  Gateway_Max
 SG_ KL_Charisma_FahrPr : 16|4@1+ (1.0,0.0) [0.0|15] ""  Gateway_Max
 SG_ KL_Charisma_Status : 20|2@1+ (1.0,0.0) [0.0|3] ""  Gateway_Max
 SG_ KL_nachtr_Stopp_Anf : 22|1@1+ (1.0,0.0) [0.0|1] ""  Gateway_Max
 SG_ KL_T_Charge : 23|1@1+ (1.0,0.0) [0.0|1] ""  Gateway_Max
 SG_ KL_Last_Kompr : 24|8@1+ (0.25,0) [0.00|63.50] "Unit_NewtoMeter"  Gateway_Max
 SG_ KL_Spannungs_Anf : 32|2@1+ (1.0,0.0) [0.0|3] ""  Gateway_Max
 SG_ KL_Thermomanagement : 34|2@1+ (1.0,0.0) [0.0|3] ""  Gateway_Max
 SG_ KL_StartStopp_Info : 36|2@1+ (1.0,0.0) [0.0|3] ""  Gateway_Max
 SG_ KL_Freilauf_Info : 38|2@1+ (1.0,0.0) [0.0|3] ""  Gateway_Max
 SG_ KL_Anf_KL : 40|8@1+ (0.4,0) [0.0|101.6] "Unit_PerCent"  Gateway_Max
 SG_ KL_el_Zuheizer_Stufe : 48|3@1+ (1.0,0.0) [0.0|7] ""  Gateway_Max
 SG_ KL_Ausstattung_Klima : 51|3@1+ (1.0,0.0) [0.0|7] ""  Gateway_Max
 SG_ KL_Variante_Standheizung : 54|2@1+ (1.0,0.0) [0.0|3] ""  Gateway_Max
 SG_ KL_AirCleaner_aktiv : 56|1@1+ (1.0,0.0) [0.0|1] ""  Gateway_Max
 SG_ KL_Anf_KV : 57|7@1+ (1,0) [0|100] "Unit_PerCent"  Gateway_Max

CM_ BO_ 2463978703 "Gesendet vom HVLM";
CM_ BO_ 2463978707 "Gesendet vom HVLM";
CM_ BO_ 2621505536 "VWAG Diagnose funktionaler Request auf CANFD";
CM_ BO_ 960 "MQB";
CM_ BO_ 1646 "ab MQB 7.3";
CM_ BO_ 949 "ab MQB 7.4";

CM_ SG_ 2463978703 HVLM_GBT_01_BZ "4bit Botschaftszähler, wird mit jeder Sendebotschaft inkrementiert";
CM_ SG_ 2463978703 HVLM_GBT_01_Sendestatus "Gibt den Sendestatus der Botschaft HVLM_GBT_01 an (notwendig für IL-Unterstützung)";
CM_ SG_ 2463978703 HVLM_GBT_BCL_Ladeverfahren "Ladeverfahren der HV-Batterie";
CM_ SG_ 2463978703 HVLM_GBT_BCL_Sollspannung "Spannungsbedarf der HV-Batterie";
CM_ SG_ 2463978703 HVLM_GBT_BCL_Sollstrom "Strombedarf der HV-Batterie";
CM_ SG_ 2463978703 HVLM_GBT_BCP_Ist_Spannung_HvBatt "aktuelle Spannung der HV-Batterie vor Laden";
CM_ SG_ 2463978703 HVLM_GBT_BCP_MaxLadestrom_Fzg "Maximaler Ladestrom des Fahrzeugs";
CM_ SG_ 2463978703 HVLM_GBT_BCP_MaxTemperatur "Maximale erlaubte Temperatur der HV-Batterie";
CM_ SG_ 2463978703 HVLM_GBT_BCP_MaxZellladespannung "Maximale Zellspannung der HV-Batterie";
CM_ SG_ 2463978703 HVLM_GBT_BCP_Nennenergiegehalt "Nennenergiegehalt der HV-Batterie";
CM_ SG_ 2463978703 HVLM_GBT_BCP_StartSOC "Der Ladezustand vor Laden";
CM_ SG_ 2463978703 HVLM_GBT_BCS_GroupNr_Uzellmax_v2 "Gruppennumer der Zelle mit maximaler Zellspannung";
CM_ SG_ 2463978703 HVLM_GBT_BCS_GruppenNr_Uzellmax "Gruppennumer der Zelle mit maximaler Zellspannung";
CM_ SG_ 2463978703 HVLM_GBT_BCS_Ist_Ladespannung "aktuelle Ladespannung der HV-Batterie während des Ladevorgangs";
CM_ SG_ 2463978703 HVLM_GBT_BCS_Ist_Ladestrom "aktueller Ladestrom der HV-Batterie während des Ladevorgangs";
CM_ SG_ 2463978703 HVLM_GBT_BCS_Ist_MaxZellspannung "aktuelle maximale Zellspannung während des Ladevorgangs";
CM_ SG_ 2463978703 HVLM_GBT_BCS_Ist_Restladezeit "aktuelle verbleibende Ladezeit";
CM_ SG_ 2463978703 HVLM_GBT_BCS_IstSOC "aktueller Ladezustand während des Ladevorgangs";
CM_ SG_ 2463978703 HVLM_GBT_BEM_Timeout_CCS "Timeout für Botschaft CCS der Ladesäule";
CM_ SG_ 2463978703 HVLM_GBT_BEM_Timeout_CML "Timeout für Botschaft CML der Ladesäule";
CM_ SG_ 2463978703 HVLM_GBT_BEM_Timeout_CRMnReady "Timeout für Botschaft CRM-Ladesäule nicht bereit der Ladesäule";
CM_ SG_ 2463978703 HVLM_GBT_BEM_Timeout_CRMReady "Timeout für Botschaft CRM-Ladesäule bereit der Ladesäule";
CM_ SG_ 2463978703 HVLM_GBT_BEM_Timeout_CRO "Timeout für Botschaft CRO der Ladesäule";
CM_ SG_ 2463978703 HVLM_GBT_BEM_Timeout_CSD "Timeout für Botschaft CSD der Ladesäule";
CM_ SG_ 2463978703 HVLM_GBT_BEM_Timeout_CST "Timeout für Botschaft CST der Ladesäule";
CM_ SG_ 2463978703 HVLM_GBT_BRM_Batterietyp "Batterietyp Fahrzeug";
CM_ SG_ 2463978703 HVLM_GBT_BRM_Nennkapazitaet "Nennkapazität HV- Batterie";
CM_ SG_ 2463978703 HVLM_GBT_BRM_Nennspannung_HvBatt "Nennspannung HV-Batterie";
CM_ SG_ 2463978703 HVLM_GBT_BRM_ProtokollVersion "GB Protokoll Version Fahrzeug";
CM_ SG_ 2463978703 HVLM_GBT_BRO_FzgBereitschaft "Signalisierung ob das Fahrzeug bereit zum Laden ist";
CM_ SG_ 2463978703 HVLM_GBT_BSD_EndSOC "Ladezustand nach Laden der HV-Batterie";
CM_ SG_ 2463978703 HVLM_GBT_BSD_MaxTemperatur "Maximale Temperatur des gesamten Ladens";
CM_ SG_ 2463978703 HVLM_GBT_BSD_MaxZellspannung "Maximale Zellspannung des gesamten Ladens";
CM_ SG_ 2463978703 HVLM_GBT_BSD_MinTemperatur "Minimale Temperatur des gesamten Ladens";
CM_ SG_ 2463978703 HVLM_GBT_BSD_MinZellspannung "Minimale Zellspannung des gesamten Ladens";
CM_ SG_ 2463978703 HVLM_GBT_BSM_FzgLadeerlaubnis "Ladeerlaubnis des Fahrzeugs";
CM_ SG_ 2463978703 HVLM_GBT_BSM_Ist_MaxTemperatur "aktuelle maximale Temperatur der HV-Batterie";
CM_ SG_ 2463978703 HVLM_GBT_BSM_Ist_MinTemperatur "aktuelle minimale Temperatur der HV-Batterie";
CM_ SG_ 2463978703 HVLM_GBT_BSM_Messpunkt_MaxT "Die Nummer des Messpunktes mit maximaler Temperatur";
CM_ SG_ 2463978703 HVLM_GBT_BSM_Messpunkt_MinT "Die Nummer des Messpunktes mit minimaler Temperatur";
CM_ SG_ 2463978703 HVLM_GBT_BSM_Nr_MaxZellspannung "Nummer der Zelle mit maximaler Zellspannung";
CM_ SG_ 2463978703 HVLM_GBT_BSM_Status_Iso "Isolationsstatus während des Ladens";
CM_ SG_ 2463978703 HVLM_GBT_BSM_Status_SOC "Status des Ladezustands während des Ladens";
CM_ SG_ 2463978703 HVLM_GBT_BSM_Status_Stecker "Steckerstatus während des Ladens";
CM_ SG_ 2463978703 HVLM_GBT_BSM_Status_Strom "Status des Stroms während des Ladens";
CM_ SG_ 2463978703 HVLM_GBT_BSM_Status_Temperatur "Status der Temperatur während des Ladens";
CM_ SG_ 2463978703 HVLM_GBT_BSM_Status_Zellspannung "Status der Zellspannung der HV-Batterie während des Ladens";
CM_ SG_ 2463978703 HVLM_GBT_BST_Ladeende1_Fahrzeug "Ladeende des Fahrzeugs wenn der Zielladezustand erreicht ist";
CM_ SG_ 2463978703 HVLM_GBT_BST_Ladeende2_Fahrzeug "Zielspannung der HV-Batterie erreicht";
CM_ SG_ 2463978703 HVLM_GBT_BST_Ladeende3_Fahrzeug "Zielzellspannnung erreicht";
CM_ SG_ 2463978703 HVLM_GBT_BST_Ladeende4_Fahrzeug "Ladeende durch Ladesäule";
CM_ SG_ 2463978703 HVLM_GBT_BST_Ladeende_Fehler1 "Ladeende durch Isolationsfehler des Ladesystems";
CM_ SG_ 2463978703 HVLM_GBT_BST_Ladeende_Fehler2 "Ladeende durch Übersemperatur des 'output connector'";
CM_ SG_ 2463978703 HVLM_GBT_BST_Ladeende_Fehler3 "Ladeende durch Übertemperatur einer Batteriekomponente und des 'output connector'";
CM_ SG_ 2463978703 HVLM_GBT_BST_Ladeende_Fehler4 "Ladeende durch Fehler Ladestecker";
CM_ SG_ 2463978703 HVLM_GBT_BST_Ladeende_Fehler5 "Ladeende durch Übertemperatur einer Batteriegruppe";
CM_ SG_ 2463978703 HVLM_GBT_BST_Ladeende_Fehler6 "Ladeende durch HV-Schütze Fehler";
CM_ SG_ 2463978703 HVLM_GBT_BST_Ladeende_Fehler7 "Ladeende durch Spannungsfehler am Messpunkt 2 (CC2)";
CM_ SG_ 2463978703 HVLM_GBT_BST_Ladeende_Fehler8 "Ladeende durch andere Fehler des Fahrzeugs";
CM_ SG_ 2463978703 HVLM_GBT_BST_Ladeende_Fehler_I "Ladeende durch Fehler von Strom";
CM_ SG_ 2463978703 HVLM_GBT_BST_Ladeende_Fehler_U "Ladeende durch Fehler von Spannung";
CM_ SG_ 2463978703 HVLM_GBT_HvBatt_MaxLadespannung "Maximale Ladespannung der HV-Batterie";
CM_ SG_ 2463978703 HVLM_GBT_SendeAnf_BCL "Anforderung zum Senden der Botschaft BCL";
CM_ SG_ 2463978703 HVLM_GBT_SendeAnf_BCP "Anforderung zum Senden der Botschaft BCP";
CM_ SG_ 2463978703 HVLM_GBT_SendeAnf_BCS "Anforderung zum Senden der Botschaft BCS";
CM_ SG_ 2463978703 HVLM_GBT_SendeAnf_BEM "Anforderung zum Senden der Botschaft BEM";
CM_ SG_ 2463978703 HVLM_GBT_SendeAnf_BHM "Anforderung zum Senden der Botschaft BHM";
CM_ SG_ 2463978703 HVLM_GBT_SendeAnf_BRM "Anforderung zum Senden der Botschaft BRM";
CM_ SG_ 2463978703 HVLM_GBT_SendeAnf_BRO "Anforderung zum Senden der Botschaft BRO";
CM_ SG_ 2463978703 HVLM_GBT_SendeAnf_BSD "Anforderung zum Senden der Botschaft BSD";
CM_ SG_ 2463978703 HVLM_GBT_SendeAnf_BSM "Anforderung zum Senden der Botschaft BSM";
CM_ SG_ 2463978703 HVLM_GBT_SendeAnf_BST "Anforderung zum Senden der Botschaft BST";
CM_ SG_ 2463978703 HVLM_GBT_Status_Control "Anforderung zum Zurücksetzen des Botschaftstatuses auf Init Werte";

CM_ SG_ 2463978877 SOK_HVLM_GBT_01_Signatur_02 "Signatur im Rahmen der durch SOK geschützen Broadcast-Kommunikation

Geschützte Funktion: HV-Laden
Geschützte Botschaft: HVLM_GBT_01
Geschützte Signale:
HVLM_GBT_BCP_MaxLadestrom_Fzg
HVLM_GBT_BCP_MaxZellladespannung
HVLM_GBT_BCL_Sollspannung
HVLM_";

CM_ SG_ 2463978707 HVLM_AnforderungPLTabellen "Das Signal gibt an ob das Fahrzeug Preis-Leistungtabellen nach der ISO15118-2 unterstuetzt und auf der Basis einen Ladeplan berechnen kann";
CM_ SG_ 2463978707 HVLM_FehlerFzgPlc "Interner Status des Fahrzeugs / PEVErrorCode
(DIN70121 RC_2)
0 = Kein Fehler / NO_ERROR
1 = HV-Batterie Temperatur unzulässig / FAILED_RESSTemperatureInhibit
2 = Fehler Waehlhebel nicht in P / FAILED_PEVShiftPosition
3 = Fehler bei Steckerverriegelun";
CM_ SG_ 2463978707 HVLM_LadeartAnfFzgPlc "PLC Anforderung der Energieübertragung";
CM_ SG_ 2463978707 HVLM_LadebereitFzgPlc "PLC- HV-Laden (DIN/ISO) Ladebereitschaft des Fahrzeugs";
CM_ SG_ 2463978707 HVLM_LadenAbgeschlPlc "Gibt den Status des Fahrzeugs an die Ladesäule";
CM_ SG_ 2463978707 HVLM_LadeSessionPlc "Steuerung der PLC-Kommunikationssession nach ISO15118";
CM_ SG_ 2463978707 HVLM_LadezustandHvBatFzgPlc "Anzeige-Ladezustand der HV-Batterie / PEVRESSSOC
(DIN70121 RC_2)";
CM_ SG_ 2463978707 HVLM_maxLadespannungFzgPlc "Maximale Ladespannung (Batterieschutz) / PEVMaximumVoltageLimit
(DIN70121 RC_2)";
CM_ SG_ 2463978707 HVLM_maxLadestromFzgPlc "Maximal möglicher Ladestrom / PEVMaximumCurrentLimit
(DIN70121 RC_2)";
CM_ SG_ 2463978707 HVLM_maxLadestromFzgPlc_2 "Maximal möglicher Ladestrom / PEVMaximumCurrentLimit. V2 mit größerem Wertebereich.";
CM_ SG_ 2463978707 HVLM_minLadestromFzgPlc "minimaler benoetigter Ladestrom um das Fahrzeug kosten-/energieeffizient zu Laden";
CM_ SG_ 2463978707 HVLM_MsgTriggerFzgPlc "Aktueller Status des Fahrzeugs beim DC Laden über PLC (DIN/ ISO)";
CM_ SG_ 2463978707 HVLM_NormFzgPlc "Vorgabe, welcher Kommunikationsstandard in der PLC priorisiert werden soll.";
CM_ SG_ 2463978707 HVLM_PLC_01_BZ "4bit Botschaftszähler, wird mit jeder Sendebotschaft inkrementiert";
CM_ SG_ 2463978707 HVLM_PlcAnforderung "Anforderung zum Aufbau, Pausieren und Abbau der PLC-Kommunikation nach ISO 15118";
CM_ SG_ 2463978707 HVLM_PlcKommLadedose "Auswahl der Ladedose an der die ISO-Kommunikation über PLC angefordert wird";
CM_ SG_ 2463978707 HVLM_PlcModemAktivieren "Anforderung zur Aktivierung des PLC-Modems";
CM_ SG_ 2463978707 HVLM_ReadyToChargeState "Das Fahrzeug signalisiert die Ladebereitschaft";
CM_ SG_ 2463978707 HVLM_RestladezeitFzgPlc "Verbleibende Zeit bis 100% Anzeige SOC erreicht sind / RemainingTimeToFullSoC
(DIN70121 RC_2)";
CM_ SG_ 2463978707 HVLM_RestladezeitTeilladungPlc "Verbleibende Zeit bis der Teil SOC erreicht ist / RemainingTimeToBulkSoC
(DIN70121 RC_2)";
CM_ SG_ 2463978707 HVLM_SollstromFzgPlc_2 "Vom Fzg. angeforderter Ladestrom / ChargeCurrentRequest V2 des Signals HVLM_SollstromFzgPlc mit höherem Wertebereich";
CM_ SG_ 2463978707 HVLM_TLS_PnC_Authenfizierung "Triggersignal, um im UDP/TCP Aufbau eine TLS-Verbindung zu erstellen ist und zum Transfer der erfordlichen PnC-Zertifikate zum OCC.";
CM_ SG_ 2463978707 HVLM_ZahlungsmethodeFzgPlc "Verwendete Zahlungsmethode / SelectedPaymentOption
(DIN70121 RC_2)
0 = Vertrag / Contract
1 = externe Bezahlung/ ExternalPayment";
CM_ SG_ 2463978707 HVLM_ZielladespannungFzgPlc "Vom Fzg. angeforderte Zielladespannung / PEVTargetVoltage
(DIN70121 RC_2)";

CM_ SG_ 2463978798 SOK_HVLM_PLC_01_Signatur "Signatur im Rahmen der durch SOK geschützen Broadcast-Kommunikation

Geschützte Funktion: HV-Laden
Geschützte Signale: HVLM_SollstromFzgPlc2
Geschützte Botschaft: HVLM_PLC_01";

CM_ SG_ 2589283690 HVLE_eTM_max_Vorlauftemperatur "Vorlauftemperatur gemäß der Ladegerätkühlung";
CM_ SG_ 2589283690 HVLE_Temperatur "Isttemperatur SAC";
CM_ SG_ 2589283690 HVLE_ThermAuslastungsgrad "Thermischer Auslastungsgrad des Ladegeräts für die Kühlanforderung";
CM_ SG_ 2589283690 IPB_ThermAuslastungsgrad "Thermischer Auslastungsgrad der IPB";
CM_ SG_ 2589283690 IPB_Wasser_TEMP_AUS "Wassertemperatur Auslass IPB";
CM_ SG_ 2589283690 IPB_Wasser_TEMP_EIN "Wassertemperatur Einlass IPB";
CM_ SG_ 2589283690 LAD_OBD_Lampe_Anf "Anforderung MIL (MalfunctionIndicationLamp) von Ladegerät (Motorsteuergerät reicht diese Info an Kombi weiter).";
CM_ SG_ 2589283690 OBDProtocol_Ladegeraet "Bestätigung des aktuell umgesetzten Scan Tool Protokolls";
CM_ SG_ 2589283690 TNV_Temperatur "Momentanwert: Temperatur des Traktionsnetzverteilers";

CM_ SG_ 2589283695 SOK_IPB_03_Signatur "Signatur im Rahmen der durch SOK geschützen Broadcast-Kommunikation

Geschützte Funktion: OBD-Malfunction Indicator Light (MIL)
Geschützte PDU: IPB_03";

CM_ SG_ 1857 ISO_DCDC_Req_Data "OffBoard Tester Diagnose Request DCDC";

CM_ SG_ 1963 ISO_DCDC_Resp_Data "OffBoard Tester Diagnose Response DCDC";

CM_ SG_ 1792 ISO_ALL_01_Req_Data "Funktionaler Request ALL";

CM_ SG_ 1862 ISO_Klima_Req_Data "Diagnose Request Klima Vorne";

CM_ SG_ 1968 ISO_Klima_Resp_Data "Diagnose Response Klima Vorne";

CM_ SG_ 1860 ISO_Ladegeraet_Req_Data "OffBoard Tester Diagnose Request Ladegeraet";

CM_ SG_ 1966 ISO_Ladegeraet_Resp_Data "OffBoard Tester Diagnose Response Ladegeraet";

CM_ SG_ 2463978775 HVLX_GeneratorMode "Gibt an ob die Ladestation netzgeführt oder netzbildend arbeitet. Wird verwendet um zu kommunizieren ob die Ladestation mit dem EVU-Netz verbunden ist (GridFollowing) oder nicht (GridForming)";
CM_ SG_ 2463978775 HVLX_Isond_EigenstromLadenStatus "Status ob ein Eigenstrom im Rahmen des VAS Dienst 'ChargingExtension' zur Verfuegung steht.";
CM_ SG_ 2463978775 HVLX_Isond_EVSEProcessing_Status "Dieses Signal gibt den aktuellen Status der Ladesaeule";
CM_ SG_ 2463978775 HVLX_ISOND_EVSEResponseMaxDelay "Zeitdauer vom Senden der Nachricht (relative Zeit) bis zur  erwarteten Durchführung der Aktion";
CM_ SG_ 2463978775 HVLX_ISOND_FODStatus "Status der Fremdkoerpererkennung";
CM_ SG_ 2463978775 HVLX_ISOND_GADcLeistung "Aktuelle Ausgangsleistung der GA beim induktiven Laden";
CM_ SG_ 2463978775 HVLX_ISOND_GAFrequenz "Bevorzugte Frequenz fuer die Energieuebertragung";
CM_ SG_ 2463978775 HVLX_ISOND_GALeistungNetz "Leistungsaufnahme aus dem Netz";
CM_ SG_ 2463978775 HVLX_ISOND_GASpulenstrom "Strom durch GA Spule";
CM_ SG_ 2463978775 HVLX_Isond_IsoStatusLadesaeule "Ergebnisanzeige der Isolationsmessung / EVSEIsolationStatus (EVSEStatus)
(DIN70121 RC_2)";
CM_ SG_ 2463978775 HVLX_Isond_IstEnergiemengeLsPlc "Abgerechnete Ladeenergie von der Ladesaeule in kWh";
CM_ SG_ 2463978775 HVLX_Isond_IstSpannungACLsPlc "Angabe der nominellen Spannung pro Phase von der Ladesaeule gemessen zwischen Phase und Neutral.";
CM_ SG_ 2463978775 HVLX_Isond_IstSpannungLadesaeule "Istspannung der Ladestation / EVSEPresentVoltage
(DIN70121 RC_2)";
CM_ SG_ 2463978775 HVLX_Isond_IstStromLadesaeule "Iststrom der Ladestation / EVSEPresentCurrent
(DIN70121 RC_2)";
CM_ SG_ 2463978775 HVLX_Isond_LadeartAC1PCorePlc "Gibt an, ob die PLC-Ladesaeule das einphasige AC-Laden nach IEC 62196 unterstuetzt";
CM_ SG_ 2463978775 HVLX_Isond_LadeartAC3PCorePlc "Gibt an, ob die PLC-Ladesaeule das einphasige AC-Laden nach IEC 62196 unterstuetzt";
CM_ SG_ 2463978775 HVLX_Isond_LadeartDCComboCorePlc "Gibt an, ob die PLC-Ladesaeule das DC-Laden nach IEC2196-3 ueber die Core Pins (Steckerausfuehrung EE oder FF) unterstuetzt";
CM_ SG_ 2463978775 HVLX_Isond_LadeartDCCorePlc "Gibt an, ob die PLC-Ladesaeule das DC-Laden nach IEC 62196 ueber die Core-Pins unterstuetzt";
CM_ SG_ 2463978775 HVLX_Isond_LadeartDCExtendedPlc "Gibt an, ob die PLC-Ladesaeule das DC-Laden nach IEC2196-3 ueber die externen Pins (Steckerausfuehrung EE oder FF) unterstuetzt";
CM_ SG_ 2463978775 HVLX_Isond_LadeartDCUniquePlc "Gibt an, ob die PLC-Ladesaeule das DC-Laden ueber einen spezifischen Ladestecker unterstuetzt";
CM_ SG_ 2463978775 HVLX_Isond_LadeartWpt "Gibt an, ob die es sich bei dem verbundenen WLAN um ein WLAN Netz eines WPT-Systems handelt";
CM_ SG_ 2463978775 HVLX_Isond_LadeplanErhaltenHlc "Information, ob die Ladetabelle im fluechtigen Speicher vorliegen und zum Transfer zur EVSE nach ISO15118 bereit sind";
CM_ SG_ 2463978775 HVLX_ISOND_LeistungsanfEV "Benoetigte Parameter zum Austausch";
CM_ SG_ 2463978775 HVLX_ISOND_LOPStatus "Status der Lebendobjekterkennung";
CM_ SG_ 2463978775 HVLX_Isond_LsNotification_Plc "Rueckmeldestatus der Ladesaeule (HLC nach ISO15118-2) zur Aufforderung einer Interaktion seitens des Fahrzeuges";
CM_ SG_ 2463978775 HVLX_Isond_maxAcAbgabestromL1 "Maximal moeglicher Ausgangsstrom der Ladestation L1";
CM_ SG_ 2463978775 HVLX_Isond_maxAcAbgabestromL2 "Maximal moeglicher Ausgangsstrom der Ladestation L2";
CM_ SG_ 2463978775 HVLX_Isond_maxAcAbgabestromL3 "Maximal moeglicher Ausgangsstrom der Ladestation L3";
CM_ SG_ 2463978775 HVLX_Isond_maxAcEigenstromL1 "Verfuegbarer Eigenstrom L1";
CM_ SG_ 2463978775 HVLX_Isond_maxAcEigenstromL2 "Verfuegbarer Eigenstrom L2";
CM_ SG_ 2463978775 HVLX_Isond_maxAcEigenstromL3 "Verfuegbarer Eigenstrom L3";
CM_ SG_ 2463978775 HVLX_Isond_maxLeistungErreicht "Status Leistungslimit/ EVSEPowerLimitAchieved
(DIN70121 RC_2)";
CM_ SG_ 2463978775 HVLX_Isond_maxLeistungLadesaeule "Maximal moegliche Ausgangsleitung der Ladestation / EVSEMaximumPowerLimit
(DIN70121 RC_2)";
CM_ SG_ 2463978775 HVLX_Isond_maxSpannungErreicht "Status Spannungslimit/ EVSEVoltageLimitAchieved
(DIN70121 RC_2)";
CM_ SG_ 2463978775 HVLX_Isond_maxSpannungLadesaeule "Maximal moegliche Ausgangsspannung der Ladestation / EVSEMaximumVoltageLimit
(DIN70121 RC_2)";
CM_ SG_ 2463978775 HVLX_Isond_MaxStromACLsPlc "Maximaler Strom welches von der Ladesaeule pro Phase unterstuetzt wird";
CM_ SG_ 2463978775 HVLX_Isond_maxStromErreicht "Status Stromlimit/ EVSECurrentLimitAchieved
(DIN70121 RC_2)";
CM_ SG_ 2463978775 HVLX_Isond_maxStromLadesaeule "Maximal moeglicher Ausgangsstrom der Ladestation / EVSEMaximumCurrentLimit
(DIN70121 RC_2)";
CM_ SG_ 2463978775 HVLX_Isond_minSpannungLadesaeule "Minimal moegliche Ausgangsspannung der Ladestation innerhalb der Toleranz / EVSEMinimumVoltageLimit
(DIN70121 RC_2)";
CM_ SG_ 2463978775 HVLX_Isond_minStromLadesaeule "Minimal moeglicher Ausgangsstrom der Ladestation innerhalb der Toleranz / EVSEMinimumCurrentLimit
(DIN70121 RC_2)";
CM_ SG_ 2463978775 HVLX_Isond_NormLsPlc "Gibt an, welcher Protokollstandard (DIN70121/ ISO15118) die Ladesaeule im Application-Layer verwendet";
CM_ SG_ 2463978775 HVLX_Isond_PLC_Message_Status "Dieses Signal meldet den PLC Triggerstatus der Ladesaeule zurueck";
CM_ SG_ 2463978775 HVLX_Isond_PlcKommFehler "Fehler bei der Kommunikaion mit der Ladesaeule (Status vom Stack, nicht Teil der Norm)
(DIN70121 RC_2)";
CM_ SG_ 2463978775 HVLX_ISOND_PncServiceDetailStat "Rückmeldenstatus aus dem 'ServiceDetailRes.ServiceParameterList' aus dem Service 'Certificate' (ID2), ob eine Installation und/oder Updatefunktion zur Verfügung steht.";
CM_ SG_ 2463978775 HVLX_ISOND_PncServiceDiscovStat "Status des Service 'Certificate' mit der ID2 und der ServiceCategory 'ContractCertificate' welches aus der 'ServiceDiscoveryRes.ServiceList' hervorgeht. Wenn der Service zur Verfügung steht ist der Signalwert auf 'vorhanden'";
CM_ SG_ 2463978775 HVLX_ISOND_PncZertifikateTrans "Rückmeldung des Transfers der Daten zwischen ISO15118-Stack und PnC-Service bei der Installation von Vertragsdaten über die Ladesäule";
CM_ SG_ 2463978775 HVLX_Isond_PnCZertifkatErhaltHlc "Information, ob alle erforderliche Zertifikate im fluechtigen Speicher vorliegen und bereit fuer die PnC-Funktion sind";
CM_ SG_ 2463978775 HVLX_Isond_ResponseCodeLsPlc "Gibt den Rueckmeldestatus der Ladesaeule an";
CM_ SG_ 2463978775 HVLX_Isond_SASTupelErhaltenHlc "Information, ob eine oder mehrere Preis-/Leistungstabellen im fluechtigen Speicher vorliegen und zum Transfer bereit sind";
CM_ SG_ 2463978775 HVLX_Isond_StatusLadesaeule "Interner Status der Ladestation / DC_EVSEStatusCode (EVSEStatus)
Interner Status der Ladestation /
(DIN70121 RC_2)";
CM_ SG_ 2463978775 HVLX_Isond_StatusRcdACLsPlc "Status der Fehlerstrom-Schutzeinrichtung (RCD) von der Ladeinfrastruktur";
CM_ SG_ 2463978775 HVLX_Isond_StromrippelPeakLs "Groesse des Stromrippels (Welligkeit) der Ladestation (Spitze-Spitze)/ EVSEPeakCurrentRipple
(DIN70121 RC_2)";
CM_ SG_ 2463978775 HVLX_Isond_TLS_PnC_Status "Information vom PLC-Stack, ob eine verschluesselte Kommunikation nach ISO15118 zwischen EVCC und SECC aufgebaut wurde";
CM_ SG_ 2463978775 HVLX_Isond_TlsZertifkatErhaltHlc "Information, ob alle erforderlichen Zertifikate im fluechtigen Speicher vorliegen und bereit fuer den TLS-Aufbau sind";
CM_ SG_ 2463978775 HVLX_Isond_VASBedAnzStatus_LsPlc "Status ob die Ladesaeule den Value Added Service 'ControlAndDisplayExtension' Anbietet";
CM_ SG_ 2463978775 HVLX_Isond_VASErwLFStatus_LsPlc "Status ob die Ladesaeule ueber die Value Added Service den Dienst 'ChargingExtensions' Anbietet";
CM_ SG_ 2463978775 HVLX_Isond_VasResponse "Response from VAS to HLC request.";
CM_ SG_ 2463978775 HVLX_Isond_WPT_DevicePosStatus "Rückmeldung des WPT Systems zum Status der Positionierung der Fahrzeugplatte (DevicePositioning)";
CM_ SG_ 2463978775 HVLX_Isond_WPT_VehiclePosStatus "Rückmeldung des WPT Systems zum Status der Positionierung des Fahrzeugs";
CM_ SG_ 2463978775 HVLX_Isond_ZahlererfassungAnfHlc "Information ob die Ladesaeule nach ISO15118 eine Zaehlererfassung zur Abrechnung anfordert (nur fuer PnC)";
CM_ SG_ 2463978775 HVLX_Isond_ZahlungsmethodeLs "Verwendete Zahlungsmethode / SelectedPaymentOption
(DIN70121 RC_2)";
CM_ SG_ 2463978775 HVLX_LadeartDCBptPlc "Gibt an ob die Ladestation das bidirektionale Laden (BidirectionalPowerTransfer) unterstützt / EnergyTransferServiceList";
CM_ SG_ 2463978775 HVLX_LSPLC_01_Sendestatus "Gibt den Sendestatus der Boschaft OCC_LSPLC_01 an (notwendig fuer IL-Unterstuetzung)";
CM_ SG_ 2463978775 HVLX_maxEntladeLeistungLS "Maximal mögliche Entladeleistung der Ladestation / EVSEMaximumDischargePower";
CM_ SG_ 2463978775 HVLX_maxEntladeStromLadesaeule "Maximal möglicher Entladestrom der Ladestation / EVSEMaximumDischargeCurrent";
CM_ SG_ 2463978775 HVLX_minEntladeStromLadesaeule "Minimal möglicher Entladestrom der Ladestation innerhalb der Toleranz / EVSEMinimumDischargeCurrent";
CM_ SG_ 2463978775 HVLX_PlcFehlerstatus "Fehlerstatus der PLC Kommunikation";
CM_ SG_ 2463978775 HVLX_PlcGefundeneLadesaeule "Anzahl der gefundenen Ladesaeulen mit PLC-Funktion, die im PLC-Modul gespeichert sind";
CM_ SG_ 2463978775 HVLX_PlcLinkStatus "Verbindungsstatus der PLC Kommunikation";

CM_ SG_ 2549874844 ISOx_BMS_48V_Req_Data "OffBoard Tester Diagnose Request BMS_48V";

CM_ SG_ 2621440156 ISOx_BMS_48V_Req_FD_Data "OffBoard Tester Diagnose Response BMS_48V";

CM_ SG_ 2550005916 ISOx_BMS_48V_Resp_Data "OffBoard Tester Diagnose Response BMS_48V";

CM_ SG_ 2621571228 ISOx_BMS_48V_Resp_FD_Data "OffBoard Tester Diagnose Response BMS_48V";

CM_ SG_ 2550399045 ISOx_BMS_NV_Req_Data "OffBoard Tester Diagnose Request BMS_NV";

CM_ SG_ 2621702213 ISOx_BMS_NV_Req_FD_Data "OffBoard Tester Diagnose Response BMS_NV";

CM_ SG_ 2550530117 ISOx_BMS_NV_Resp_Data "OffBoard Tester Diagnose Response BMS_NV";

CM_ SG_ 2621833285 ISOx_BMS_NV_Resp_FD_Data "OffBoard Tester Diagnose Response BMS_NV";

CM_ SG_ 2549874873 ISOx_DCDC_NV_Req_Data "OffBoard Tester Diagnose Request DCDC_NV";

CM_ SG_ 2621440185 ISOx_DCDC_NV_Req_FD_Data "OffBoard Tester Diagnose Response DCDC_NV";

CM_ SG_ 2550005945 ISOx_DCDC_NV_Resp_Data "OffBoard Tester Diagnose Response DCDC_NV";

CM_ SG_ 2621571257 ISOx_DCDC_NV_Resp_FD_Data "OffBoard Tester Diagnose Response DCDC_NV";

CM_ SG_ 2621440065 ISOx_DCDC_Req_FD_Data "OffBoard Tester Diagnose Response DCDC";

CM_ SG_ 2621571137 ISOx_DCDC_Resp_FD_Data "Diagnose Response DCDC";

CM_ SG_ 2621505536 ISOx_Funkt_Req_All_FD_Data "OffBoard Tester funktionaler Diagnose Request ALL CANFD";

CM_ SG_ 2549874811 ISOx_Hybrid_01_Req_Data "OffBoard Tester Diagnose Request Hybrid_01";

CM_ SG_ 2621440123 ISOx_Hybrid_01_Req_FD_Data "Diagnose Request Hybrid_01";

CM_ SG_ 2550005883 ISOx_Hybrid_01_Resp_Data "OffBoard Tester Diagnose Response Hybrid_01";

CM_ SG_ 2621571195 ISOx_Hybrid_01_Resp_FD_Data "Diagnose Response";

CM_ SG_ 2621440070 ISOx_Klima_Req_FD_Data "Diagnose Request";

CM_ SG_ 2621571142 ISOx_Klima_Resp_FD_Data "Diagnose Response";

CM_ SG_ 2621440068 ISOx_Ladegeraet_Req_FD_Data "OffBoard Tester Diagnose Response Ladegeraet";

CM_ SG_ 2621571140 ISOx_Ladegeraet_Resp_FD_Data "OffBoard Tester Diagnose Response Ladegeraet";

CM_ SG_ 2550399003 ISOx_SACID_1_Req_Data "OffBoard Tester Diagnose Request SACID_1";

CM_ SG_ 2621702171 ISOx_SACID_1_Req_FD_Data "OffBoard Tester Diagnose Response SACID_1";

CM_ SG_ 2550530075 ISOx_SACID_1_Resp_Data "OffBoard Tester Diagnose Response SACID_1";

CM_ SG_ 2621833243 ISOx_SACID_1_Resp_FD_Data "OffBoard Tester Diagnose Response SACID_1";

CM_ SG_ 792 Kamera_FDD_Anz_Strassenleuchten "Anzahl der erkannten Straßenleuchten";
CM_ SG_ 792 Kamera_FDD_Eigenblend "Dieses Signal gibt an, ob von der Kamera eine Eigenblendung, z.B. Nebel, erkannt wird.";
CM_ SG_ 792 Kamera_FDD_Eigenblend_Guete "Diese Signal gibt an, welches Maß einer Eigenblendung vorliegt.";
CM_ SG_ 792 Kamera_FDD_Funktionsstatus "Status der Fahrzeugdetektion bei Dunkelheit";
CM_ SG_ 792 Kamera_FDD_Strassenbeleuchung "Status Straßenbeleuchungsdetektion";
CM_ SG_ 792 Kamera_FDD_Verkehrsrichtung "Gibt bei Nacht die auf Grund der entgegenkommenden Fahrzeuge erkannte Verkehrsrichtung an";
CM_ SG_ 792 Kamera_FSH_aktiv "Bei aktivierter (lokaler) Frontscheibenheizung wird die Scheibentemperaturmessung des Klimafeuchtesensors beeinflusst. Über das Signal wird dem Klima-SG mitgeteilt, dass die lokale Scheibenheizung aktiviert ist, um entsprechende Korrekturwerte bei der Sch";
CM_ SG_ 792 Kamera_Helligkeit "Helligkeitsinformation der gemessenen Aussenhelligkeit der multifunktionalen Kamera
Bei mehr als 10.000 Lux geht das Signal in die Sättigung.";
CM_ SG_ 792 Kamera_Systemzustand "Systemzustand der Kamera";
CM_ SG_ 792 VZE_Status_EDR "Das Signal zeigt den Status der VZE für den EventDataRecorder an.";

CM_ SG_ 960 BCM_Ausparken_Betrieb "Anforderung zur erneuten Lampenaufprüfung und Anzeige von Warnhinweisen nach einem pilotierten Ausparkvorgang (Trigger: fallende Flanke)";
CM_ SG_ 960 BCM_Remotestart_Betrieb "Zeigt den Status des RemoteStarts an, d.h. KL15_RSt ist aktiviert und der Motorlauf ist im RSt-Betrieb aktiv.";
CM_ SG_ 960 BCM_Remotestart_KL15_Anf "Zeigt den Status der Aktivierung der KL15_RST durch das BCM an.";
CM_ SG_ 960 BCM_Remotestart_MO_Start "Nachdem das BCM die Remotestart MSG Freigabe sicher erkannt hat, fordert das BCM wiederum über dieses Signal vom MSG einen Motorstart durchzuführen.";
CM_ SG_ 960 Klemmen_Status_01_BZ "4bit Botschaftszaehler; wird in jeder Sendebotschaft inkrementiert";
CM_ SG_ 960 Klemmen_Status_01_CRC "Für MLB:
'Berechnung siehe Lastenheft 'Kommunikationsabsicherung für FlexRay und CAN''

Ab MQB und MLBevo:
'Berechnung siehe Lastenheft 'End-to-End Kommunikationsabsicherung''

Endwerte siehe Begleitdokument 'S-PDU Kennungsfolgen'";
CM_ SG_ 960 KST_Fahrerhinweis_1 "Signalisierung Fahrerhinweis 1 der Klemmensteuerung an das Kombi";
CM_ SG_ 960 KST_Fahrerhinweis_2 "Signalisierung Fahrerhinweis 2 der Klemmensteuerung an das Kombi";
CM_ SG_ 960 KST_Fahrerhinweis_4 "Signalisierung Fahrerhinweis 4 der Klemmensteuerung an das Kombi";
CM_ SG_ 960 KST_Fahrerhinweis_5 "Anzeigesignal für RemoteStart";
CM_ SG_ 960 KST_Fahrerhinweis_6 "Signal aktiviert die Kombi-Anzeigeinstrumente (Drehzahl, Tankinhalt, Kühlmitteltemperatur) während aktiviertem RemoteStart-Betrieb";
CM_ SG_ 960 KST_Warn_P1_ZST_def "Kombi Prio Warnung Klemmensteuerung 
Zündschloß defekt, Service aufsuchen!";
CM_ SG_ 960 KST_Warn_P2_ZST_def "Kombi Prio Warnung Klemmensteuerung
Zündschloß defekt!
";
CM_ SG_ 960 RSt_Fahrerhinweise "Über das Signal fordert das BCM Fahrerhinweise im Kombi für die Funktion RemoteStart an.";
CM_ SG_ 960 ZAS_Kl_15 "Klemme 15: Zuendung (SW-Kl.15)
";
CM_ SG_ 960 ZAS_Kl_50_Startanforderung "Klemme 50: Startwunsch Fahrer
";
CM_ SG_ 960 ZAS_Kl_Infotainment "Separate Klemmeninformation für das Infotainment. Signal entspricht im wesentlichen einer Klemme S Information, kann aber über einen Vor - bzw. Nachlauf zu Klemme S verfügen. 
Ein konkreter Anwendungsfall für einen Nachlauf ist die Abschaltung der Klemme";
CM_ SG_ 960 ZAS_Kl_S "Klemme S: S-Kontakt (Schluessel steckt)
";
CM_ SG_ 960 ZAS_Kl_X "Klemme 75
";

CM_ SG_ 2463978753 Klemmen_Status_02_BZ "4bit Botschaftszähler, wird mit jeder Sendebotschaft inkrementiert";
CM_ SG_ 2463978753 Klemmen_Status_02_CRC "Für MLB:
Berechnung siehe Lastenheft 'Kommunikationsabsicherung für FlexRay und CAN'
Ab MQB und MLBevo:
Berechnung siehe Lastenheft 'End-to-End Kommunikationsabsicherung'

Endwerte siehe Begleitdokument 'S-PDU Kennungsfolgen'";
CM_ SG_ 2463978753 KST_ComfortReadyStatus "Zustand des ComfortReadyStatus über den Komfortfunktionen aktiviert werden können.";
CM_ SG_ 2463978753 KST_Freigabe_Zustand "Gibt den Sperr- bzw. Freigabezustand der Klemmensteuerung während SW-Update (z. B. Infotainment) an";
CM_ SG_ 2463978753 KST_Sonderzustand_Anforderung "Hiermit wird die aktive bzw. aktuell angeforderte (s. KST_Sonderzustand_Status) Sonderfunktion identifiziert";
CM_ SG_ 2463978753 KST_Sonderzustand_Status "Hiermit wird signalisiert, dass eine Sonderfunktion aktiv ist und die Klemme 15 durch diese angefordert wurde bzw. ein Übergang von Sonderfunktionen stattfindet";
CM_ SG_ 2463978753 KST_WFS_Fahrfreigabe_Anforderung "Hiermit wird den Wegfahrsperren-Teilnehmern signalisiert welche Art der Fahrfreigabe von der anfordernden Sonderfunktion benötigt wird";

CM_ SG_ 1646 KL_Anf_AussenspiegelHzg "Anforderung Außenspiegelheizung seitens Klimafunktion (z.B. bei Erweiterter VoKo)";
CM_ SG_ 1646 KL_BCmE_Livetip_Freigabe "Status der Klimaanlage. 
Zeigt an, ob der Livetip 'Fenster schließen wegen Ineffizienz Klimaanlage' sinvollerweise angezeigt werden soll";
CM_ SG_ 1646 KL_ErwVK_Anf "Erweiterte Voko angefordertert / aktiv";
CM_ SG_ 1646 KL_FSH_Automatikbetrieb "Ermöglicht eine Unterscheidung von Anforderung FSH durch Kundenwunsch und Anforderung FSH durch Regelung des Klimasteuergeräts.
Das Signal liegt als Pegel an.";
CM_ SG_ 1646 KL_Geblaese_Fond_Status "Status Geblaese









";
CM_ SG_ 1646 KL_Geblaese_Status "Status Geblaese









";
CM_ SG_ 1646 KL_Heizkreisventilstellung "Bei MQB PHEV: Stellung Heizkreisventil Motor";
CM_ SG_ 1646 KL_I_Geblaese_Fond "Stromaufnahme Gebläse Heck";
CM_ SG_ 1646 KL_Innen_Temp "Innentemperatur

";
CM_ SG_ 1646 KL_Kompressorkupplung "Signal zur Aktivierung/Deaktivierung der Kompressorkupplung";
CM_ SG_ 1646 KL_Magnetventil "Anforderung des Bypassventils.";
CM_ SG_ 1646 KL_Restwaerme_aktiv "Signal zur Aktivierung/Deaktivierung der Wasserpumpe bei Restwärme; 
reduzierte IRÜ Empfindlichkeit";
CM_ SG_ 1646 KL_SH_Soll_hl "Einstellung Sitzheizung hinten links (0...6)";
CM_ SG_ 1646 KL_SH_Soll_hr "Einstellung Sitzheizung hinten rechts (0...6)";
CM_ SG_ 1646 KL_SIH_LEH_Verteilung_VL "Vom Kunden eingestellte Aufteilung der Heizleistung auf Sitzfläche und Lehnefläche für Sitz vorne links";
CM_ SG_ 1646 KL_SIH_LEH_Verteilung_VR "Vom Kunden eingestellte Aufteilung der Heizleistung auf Sitzfläche und Lehnefläche für Sitz vorne rechts";
CM_ SG_ 1646 KL_SIH_LEL_Verteilung_VL "Vom Kunden eingestellte Aufteilung der Lüftungsleistung auf Sitzfläche und Lehnenfläche für Sitz vorne links";
CM_ SG_ 1646 KL_SIH_LEL_Verteilung_VR "Vom Kunden eingestellte Aufteilung der Lüftungsleistung auf Sitzfläche und Lehnenfläche für Sitz vorne rechts";
CM_ SG_ 1646 KL_Solarluefter_aktiv "Betriebsstatus Solarluefter
";
CM_ SG_ 1646 KL_STH_aktiv "Betriebsstatus Standheizung
";
CM_ SG_ 1646 KL_STH_Ansteuerung "Ansteuerung STH

";
CM_ SG_ 1646 KL_STH_Betriebsdauer "Betriebsdauer STH";
CM_ SG_ 1646 KL_STL_aktiv "Betriebsstatus Standlueftung
";
CM_ SG_ 1646 KL_Umluft_Taste "Betaetigung Umlufttaste
";
CM_ SG_ 1646 KL_WaPu "Ansteuerung der Standheizungswasserpumpe";

CM_ SG_ 1649 KL_Betriebsmodus_FH "Synchronisation des Betriebsmodus zwischen Front und Fond";
CM_ SG_ 1649 KL_ErwVK_Beifahrerzone "Erweiterte Voko Beifahrerseite";
CM_ SG_ 1649 KL_ErwVK_Fahrerzone "Erweiterte Voko Fahrerseite";
CM_ SG_ 1649 KL_ErwVK_Heckzone2_links "Anforderung der Heckzone dritte Sitzreihe links";
CM_ SG_ 1649 KL_ErwVK_Heckzone2_rechts "Anforderung der Heckzone dritte Sitzreihe rechts";
CM_ SG_ 1649 KL_ErwVK_Heckzone_links "Erweiterte Voko Heckzone links";
CM_ SG_ 1649 Kl_ErwVK_Heckzone_rechts "Erweiterte Voko Heckzone rechts.";
CM_ SG_ 1649 KL_ErwVK_Scheibenheizung "Erweiterte Voko Scheibenheizung";
CM_ SG_ 1649 KL_ErwVK_Status "Erweiterte Voko angefordert für
   Fahrerzone_aktiv
   Alle Zonen_aktiv
   Beifahrerzone_aktiv
   Heckzone_aktiv
   Scheibenheizung_aktiv";
CM_ SG_ 1649 KL_Hinweis_Kuehlmodus "Signal generiert einen Kundenhinweis, ob eine normale Klimatisierung umgesetzt werden kann, oder ein Sondermodus aktiv ist";
CM_ SG_ 1649 KL_Meldung_Status "Klima gibt den Status der Fahrermeldungen aus.";
CM_ SG_ 1649 KL_STH_Betriebsdauer_lang "Betriebsdauer STH im Falle eines möglichen 120min Betriebes.";
CM_ SG_ 1649 KL_Stopp_Wiederstart_Anz_01 "Dieses Signal gibt die detaillierte Begründung für eine Stoppverbot-/Wiederstartanfrage der Klima-SG an.";
CM_ SG_ 1649 KL_Stopp_Wiederstart_Anz_02 "Dieses Signal gibt die detaillierte Begründung für eine Stoppverbot-/Wiederstartanfrage der Klima-SG an.";
CM_ SG_ 1649 KL_Stopp_Wiederstart_Anz_03 "Dieses Signal gibt die detaillierte Begründung für eine Stoppverbot-/Wiederstartanfrage der Klima-SG an.";
CM_ SG_ 1649 KL_Stopp_Wiederstart_Anz_04 "Dieses Signal gibt die detaillierte Begründung für eine Stoppverbot-/Wiederstartanfrage der Klima-SG an.";
CM_ SG_ 1649 KL_Stopp_Wiederstart_Anz_05 "Dieses Signal gibt die detaillierte Begründung für eine Stoppverbot-/Wiederstartanfrage der Klima-SG an.";
CM_ SG_ 1649 KL_Stopp_Wiederstart_Anz_06 "Dieses Signal gibt die detaillierte Begründung für eine Stoppverbot-/Wiederstartanfrage der Klima-SG an.";
CM_ SG_ 1649 KL_Stopp_Wiederstart_Anz_07 "Dieses Signal gibt die detaillierte Begründung für eine Stoppverbot-/Wiederstartanfrage der Klima-SG an.";
CM_ SG_ 1649 KL_Stopp_Wiederstart_Anz_08 "Dieses Signal gibt die detaillierte Begründung für eine Stoppverbot-/Wiederstartanfrage der Klima-SG an.";
CM_ SG_ 1649 KL_Stopp_Wiederstart_Anz_09 "Dieses Signal gibt die detaillierte Begründung für eine Stoppverbot-/Wiederstartanfrage der Klima-SG an.";
CM_ SG_ 1649 KL_Stopp_Wiederstart_Anz_Std1 "Dieses Signal gibt die detaillierte Begründung für eine Stoppverbot-/Wiederstartanfrage der Klima-SG an.";
CM_ SG_ 1649 KL_Stopp_Wiederstart_Anz_Std2 "Dieses Signal gibt die detaillierte Begründung für eine Stoppverbot-/Wiederstartanfrage der Klima-SG an.";
CM_ SG_ 1649 KL_ZZ_Betriebsmodus "Betriebsdauerberechnung anhand Aussentemperaturauswertung mit Faktor 'ZZ_Betriebsmodus'";
CM_ SG_ 1649 KL_ZZ_Minute "Zielzeittimeranzeige im Display der Funkfernbedienung (Minute); Initwert ist der zuletzt gültige Wert";
CM_ SG_ 1649 KL_ZZ_Monat "Zielzeittimeranzeige im Display der Funkfernbedienung (Datum, Monat); Initwert ist der zuletzt gültige Wert";
CM_ SG_ 1649 KL_ZZ_Status_Timer "Timerstatusanzeige im Display der Funkfernbedienung (Timer aktiv/n.aktiv)";
CM_ SG_ 1649 KL_ZZ_Stunde "Zielzeittimeranzeige im Display der Funkfernbedienung (Stunde); Initwert ist der zuletzt gültige Wert";
CM_ SG_ 1649 KL_ZZ_Tag "Zielzeittimeranzeige im Display der Funkfernbedienung (Datum, Tag); Initwert ist der zuletzt gültige Wert";

CM_ SG_ 949 KL_AC_Schalter "AC Schalter
";
CM_ SG_ 949 KL_AirCleaner_aktiv "Status des Zustands der AirCare Funktion (Umluft) im Fahrzeug";
CM_ SG_ 949 KL_Anf_KL "Anforderung Kühlerlüfter der Klimaanlage in Prozent

";
CM_ SG_ 949 KL_Anf_KV "Anforderung des Kühlerrollos in %";
CM_ SG_ 949 KL_Ausstattung_Klima "Austtattungsart der Klimabedienung";
CM_ SG_ 949 KL_Charisma_FahrPr "MLBevo: Aktuelles Fahrprogramm des Charisma-Teilnehmers (siehe Systemlastenheft Drive Select)
MQB: Istwert der Kennlinie (siehe Systemlastenheft MQB FPA)";
CM_ SG_ 949 KL_Charisma_Status "Charisma Systemstatus des Charisma-Teilnehmers

Wert 0x3 ist nur für Fahrzeuge ab MQB relevant";
CM_ SG_ 949 KL_Drehz_Anh "Drehzahlanhebung vom Motor angefordert

";
CM_ SG_ 949 KL_el_Zuheizer_Stufe "Vorgabe für Motorsteuergeraet PTC-Stufe; im MLB-B8 und MQB nur Stufe 0...3

";
CM_ SG_ 949 KL_Freilauf_Info "Freilauf Informationssignal von Klima zum Freilaufkoordinator. Klima kann über dieses Signal den Freilauf freigeben, verhindern bzw. explizit anfordern.";
CM_ SG_ 949 KL_Kompressorkupplung_linear "Sollwert zur Ansteuerung der Kompressorkupplung";
CM_ SG_ 949 KL_Last_Kompr "Aktuelles Verlustmoment der Klimaanlage bezogen auf die Kurbelwelle. Wird der Klimakompressor nicht angesteuert, ist das Schleppmoment bezogen auf die Kurbelwelle zu senden.";
CM_ SG_ 949 KL_nachtr_Stopp_Anf "Dieses Signal dient dem Motor als Trigger, dass ein nachträglicher Motorstopp eingeleitet werden kann, wenn es die Bedingungen des StSt Koordinators dies zulassen. ";
CM_ SG_ 949 KL_Spannungs_Anf "Forderung des Klima-SG's zur Spannungsanhebung.";
CM_ SG_ 949 KL_StartStopp_Info "Stopp-Freigabe und Start-Anforderung an den Start-Stopp-Koordinator";
CM_ SG_ 949 KL_T_Charge "Signal für Tastenbetätigung Charge-Taste (SOC Increasing)";
CM_ SG_ 949 KL_Thermomanagement "Stufen des Thermomanagements;
Bei Klemme 15 AUS und erkannten Timeout zum Klimabedienteil (z.B. Klimabedienteil während des Motorsteuergeräte-Kommunikations-Nachlaufs bereits im NM-Zustand ¿Bus Sleep¿)
erfolgt keine Ansteuerung der Wasserpumpe durch die";
CM_ SG_ 949 KL_Variante_Standheizung "Identifikation der Variante der Standheizungen zur Berechnung der energetischen Zielzeit";
CM_ SG_ 949 KL_Vorwarn_Komp_ein "Vorwarnung Kompressor ein; 140ms vorher; Information für Motor zum Aufbau Momentenreserve";
CM_ SG_ 949 KL_Vorwarn_Zuheizer_ein "Vorwarnung Zuheizerbetrieb
";
CM_ SG_ 949 KL_Zustand "Beschreibt den Zustand des Klima-/Heizungsbedienteils. (OFF-Mode Bedienteil)

PAG (MLB): Beschreibt den Zustand des Kompressors";
BA_DEF_REL_ BU_SG_REL_  "GenSigTimeoutTime" INT 0 65535;
BA_DEF_ BO_  "DiagRequest" ENUM "No", "Yes";
BA_DEF_ BO_  "DiagResponse" ENUM "No", "Yes";
BA_DEF_ BO_  "DiagState" ENUM "No", "Yes";
BA_DEF_ BO_  "GenMsgChkConstant" HEX 0 4095;
BA_DEF_ BO_  "GenMsgCycleTime" INT 0 65535;
BA_DEF_ BO_  "GenMsgCycleTimeFast" INT 0 65535;
BA_DEF_ BO_  "GenMsgDelayTime" INT 0 100000;
BA_DEF_ BO_  "GenMsgILSupport" ENUM "No", "Yes";
BA_DEF_ BO_  "GenMsgNrOfRepetition" INT 0 100;
BA_DEF_ BO_  "GenMsgPDUConstants" STRING;
BA_DEF_ BO_  "GenMsgSendType" ENUM "Cyclic", "not_used", "not_used", "not_used", "not_used", "not_used", "not_used", "IfActive", "NoMsgSendType";
BA_DEF_ BO_  "GenMsgStartDelayTime" INT 0 100000;
BA_DEF_ BO_  "NmMessage" ENUM "No", "Yes";
BA_DEF_ BO_  "NmhMessage" ENUM "No", "Yes";
BA_DEF_ BO_  "MsgType" ENUM "Application", "NM ", "NMH", "TP2.0", "ISO-TP ", "BAP", "EID", "KS", "XCP_PRE_CONFIGURED", "XCP_RUNTIME_CONFIGURED";
BA_DEF_ BO_  "VAGTP20_API" HEX 0 255;
BA_DEF_ BO_  "VAGTP20_DynConnection" ENUM "No", "Yes";
BA_DEF_ BO_  "VAGTP20_DynSetup" ENUM "No", "Yes";
BA_DEF_ BO_  "VAGTP20_StatConnection" ENUM "No", "Yes";
BA_DEF_ BO_  "CANFD_BRS" ENUM "0", "1";
BA_DEF_ BO_  "VFrameFormat" ENUM "StandardCAN", "ExtendedCAN", "reserved", "reserved", "reserved", "reserved", "reserved", "reserved", "reserved", "reserved", "reserved", "reserved", "reserved", "reserved", "StandardCAN_FD", "ExtendedCAN_FD";
BA_DEF_ SG_  "GenSigActiveRepetitions" INT -2147483648 2147483647;
BA_DEF_ SG_  "GenSigInactiveValue" INT -2147483648 2147483647;
BA_DEF_ SG_  "GenSigSendType" ENUM "Cyclic", "OnWrite", "OnWriteWithRepetition", "OnChange", "OnChangeWithRepetition", "IfActive", "IfActiveWithRepetition", "NoSigSendType", "OnChangeAndIfActive", "OnChangeAndIfActiveWithRepetition";
BA_DEF_ SG_  "GenSigStartValue" INT -2147483648 2147483647;
BA_DEF_ SG_  "NWM-WakeupAllowed" ENUM "No", "Yes";
BA_DEF_ SG_  "GenSigFuncType" ENUM "NoFunction", "MsgCounter", "CRC-8", "XOR", "XOR-2", "DatedBit", "SW-Kl15", "CHK", "Constant", "Protocol", "CRC-8-SAE_J1850", "CRC-32", "DataLength", "DataID", "MsgCounter16", "SOK-Signatur", "Cluster";
BA_DEF_ SG_  "GenSigSwitchedByIgnition" ENUM "No", "Yes";
BA_DEF_ SG_  "Fehlerwert" HEX 0 2147483647;
BA_DEF_ SG_  "GenSigMissingSourceValue" HEX 0 2147483647;
BA_DEF_DEF_REL_  "GenSigTimeoutTime" 0;
BA_DEF_DEF_  "DiagRequest" "No";
BA_DEF_DEF_  "DiagResponse" "No";
BA_DEF_DEF_  "DiagState" "No";
BA_DEF_DEF_  "GenMsgChkConstant" 0;
BA_DEF_DEF_  "GenMsgCycleTime" 0;
BA_DEF_DEF_  "GenMsgCycleTimeFast" 0;
BA_DEF_DEF_  "GenMsgDelayTime" 0;
BA_DEF_DEF_  "GenMsgILSupport" "No";
BA_DEF_DEF_  "GenMsgNrOfRepetition" 0;
BA_DEF_DEF_  "GenMsgPDUConstants" "";
BA_DEF_DEF_  "GenMsgSendType" "NoMsgSendType";
BA_DEF_DEF_  "GenMsgStartDelayTime" 0;
BA_DEF_DEF_  "NmMessage" "No";
BA_DEF_DEF_  "NmhMessage" "No";
BA_DEF_DEF_  "MsgType" "Application";
BA_DEF_DEF_  "VAGTP20_API" 0;
BA_DEF_DEF_  "VAGTP20_DynConnection" "No";
BA_DEF_DEF_  "VAGTP20_DynSetup" "No";
BA_DEF_DEF_  "VAGTP20_StatConnection" "No";
BA_DEF_DEF_  "CANFD_BRS" "1";
BA_DEF_DEF_  "VFrameFormat" "StandardCAN";
BA_DEF_DEF_  "GenSigActiveRepetitions" 0;
BA_DEF_DEF_  "GenSigInactiveValue" 0;
BA_DEF_DEF_  "GenSigSendType" "NoSigSendType";
BA_DEF_DEF_  "GenSigStartValue" 0;
BA_DEF_DEF_  "NWM-WakeupAllowed" "No";
BA_DEF_DEF_  "GenSigFuncType" "NoFunction";
BA_DEF_DEF_  "GenSigSwitchedByIgnition" "Yes";
BA_DEF_DEF_  "Fehlerwert" 0;
BA_DEF_DEF_  "GenSigMissingSourceValue" 0;
BA_ "GenMsgCycleTime" BO_ 2463978703 1000;
BA_ "GenMsgCycleTimeFast" BO_ 2463978703 50;
BA_ "GenMsgDelayTime" BO_ 2463978703 10;
BA_ "GenMsgILSupport" BO_ 2463978703 1;
BA_ "GenMsgNrOfRepetition" BO_ 2463978703 5;
BA_ "GenMsgSendType" BO_ 2463978703 0;
BA_ "VFrameFormat" BO_ 2463978703 15;
BA_ "GenMsgCycleTime" BO_ 2463978877 1000;
BA_ "GenMsgCycleTimeFast" BO_ 2463978877 50;
BA_ "GenMsgDelayTime" BO_ 2463978877 10;
BA_ "GenMsgNrOfRepetition" BO_ 2463978877 5;
BA_ "GenMsgSendType" BO_ 2463978877 0;
BA_ "VFrameFormat" BO_ 2463978877 15;
BA_ "GenMsgCycleTime" BO_ 2463978707 1000;
BA_ "GenMsgCycleTimeFast" BO_ 2463978707 30;
BA_ "GenMsgDelayTime" BO_ 2463978707 10;
BA_ "GenMsgILSupport" BO_ 2463978707 1;
BA_ "GenMsgNrOfRepetition" BO_ 2463978707 5;
BA_ "GenMsgSendType" BO_ 2463978707 0;
BA_ "VFrameFormat" BO_ 2463978707 15;
BA_ "GenMsgCycleTime" BO_ 2463978798 1000;
BA_ "GenMsgCycleTimeFast" BO_ 2463978798 30;
BA_ "GenMsgDelayTime" BO_ 2463978798 10;
BA_ "GenMsgNrOfRepetition" BO_ 2463978798 5;
BA_ "GenMsgSendType" BO_ 2463978798 0;
BA_ "VFrameFormat" BO_ 2463978798 15;
BA_ "GenMsgCycleTime" BO_ 2589283690 500;
BA_ "GenMsgILSupport" BO_ 2589283690 1;
BA_ "GenMsgSendType" BO_ 2589283690 0;
BA_ "VFrameFormat" BO_ 2589283690 15;
BA_ "GenMsgCycleTime" BO_ 2589283695 500;
BA_ "GenMsgSendType" BO_ 2589283695 0;
BA_ "VFrameFormat" BO_ 2589283695 15;
BA_ "DiagRequest" BO_ 1857 1;
BA_ "MsgType" BO_ 1857 4;
BA_ "VFrameFormat" BO_ 1857 14;
BA_ "DiagResponse" BO_ 1963 1;
BA_ "MsgType" BO_ 1963 4;
BA_ "VFrameFormat" BO_ 1963 14;
BA_ "DiagState" BO_ 1792 1;
BA_ "MsgType" BO_ 1792 4;
BA_ "VFrameFormat" BO_ 1792 14;
BA_ "DiagRequest" BO_ 1862 1;
BA_ "MsgType" BO_ 1862 4;
BA_ "VFrameFormat" BO_ 1862 14;
BA_ "DiagResponse" BO_ 1968 1;
BA_ "MsgType" BO_ 1968 4;
BA_ "VFrameFormat" BO_ 1968 14;
BA_ "DiagRequest" BO_ 1860 1;
BA_ "MsgType" BO_ 1860 4;
BA_ "VFrameFormat" BO_ 1860 14;
BA_ "DiagResponse" BO_ 1966 1;
BA_ "MsgType" BO_ 1966 4;
BA_ "VFrameFormat" BO_ 1966 14;
BA_ "GenMsgCycleTimeFast" BO_ 2463978775 50;
BA_ "GenMsgDelayTime" BO_ 2463978775 10;
BA_ "GenMsgILSupport" BO_ 2463978775 1;
BA_ "GenMsgNrOfRepetition" BO_ 2463978775 5;
BA_ "GenMsgSendType" BO_ 2463978775 7;
BA_ "VFrameFormat" BO_ 2463978775 15;
BA_ "DiagRequest" BO_ 2549874844 1;
BA_ "MsgType" BO_ 2549874844 4;
BA_ "VFrameFormat" BO_ 2549874844 15;
BA_ "DiagRequest" BO_ 2621440156 1;
BA_ "MsgType" BO_ 2621440156 4;
BA_ "VFrameFormat" BO_ 2621440156 15;
BA_ "DiagResponse" BO_ 2550005916 1;
BA_ "MsgType" BO_ 2550005916 4;
BA_ "VFrameFormat" BO_ 2550005916 15;
BA_ "DiagResponse" BO_ 2621571228 1;
BA_ "MsgType" BO_ 2621571228 4;
BA_ "VFrameFormat" BO_ 2621571228 15;
BA_ "DiagRequest" BO_ 2550399045 1;
BA_ "MsgType" BO_ 2550399045 4;
BA_ "VFrameFormat" BO_ 2550399045 15;
BA_ "DiagRequest" BO_ 2621702213 1;
BA_ "MsgType" BO_ 2621702213 4;
BA_ "VFrameFormat" BO_ 2621702213 15;
BA_ "DiagResponse" BO_ 2550530117 1;
BA_ "MsgType" BO_ 2550530117 4;
BA_ "VFrameFormat" BO_ 2550530117 15;
BA_ "DiagResponse" BO_ 2621833285 1;
BA_ "MsgType" BO_ 2621833285 4;
BA_ "VFrameFormat" BO_ 2621833285 15;
BA_ "DiagRequest" BO_ 2549874873 1;
BA_ "MsgType" BO_ 2549874873 4;
BA_ "VFrameFormat" BO_ 2549874873 15;
BA_ "DiagRequest" BO_ 2621440185 1;
BA_ "MsgType" BO_ 2621440185 4;
BA_ "VFrameFormat" BO_ 2621440185 15;
BA_ "DiagResponse" BO_ 2550005945 1;
BA_ "MsgType" BO_ 2550005945 4;
BA_ "VFrameFormat" BO_ 2550005945 15;
BA_ "DiagResponse" BO_ 2621571257 1;
BA_ "MsgType" BO_ 2621571257 4;
BA_ "VFrameFormat" BO_ 2621571257 15;
BA_ "DiagRequest" BO_ 2621440065 1;
BA_ "MsgType" BO_ 2621440065 4;
BA_ "VFrameFormat" BO_ 2621440065 15;
BA_ "DiagResponse" BO_ 2621571137 1;
BA_ "MsgType" BO_ 2621571137 4;
BA_ "VFrameFormat" BO_ 2621571137 15;
BA_ "DiagState" BO_ 2621505536 1;
BA_ "MsgType" BO_ 2621505536 4;
BA_ "VFrameFormat" BO_ 2621505536 15;
BA_ "DiagRequest" BO_ 2549874811 1;
BA_ "MsgType" BO_ 2549874811 4;
BA_ "VFrameFormat" BO_ 2549874811 15;
BA_ "DiagRequest" BO_ 2621440123 1;
BA_ "MsgType" BO_ 2621440123 4;
BA_ "VFrameFormat" BO_ 2621440123 15;
BA_ "DiagResponse" BO_ 2550005883 1;
BA_ "MsgType" BO_ 2550005883 4;
BA_ "VFrameFormat" BO_ 2550005883 15;
BA_ "DiagResponse" BO_ 2621571195 1;
BA_ "MsgType" BO_ 2621571195 4;
BA_ "VFrameFormat" BO_ 2621571195 15;
BA_ "DiagRequest" BO_ 2621440070 1;
BA_ "MsgType" BO_ 2621440070 4;
BA_ "VFrameFormat" BO_ 2621440070 15;
BA_ "DiagResponse" BO_ 2621571142 1;
BA_ "MsgType" BO_ 2621571142 4;
BA_ "VFrameFormat" BO_ 2621571142 15;
BA_ "DiagRequest" BO_ 2621440068 1;
BA_ "MsgType" BO_ 2621440068 4;
BA_ "VFrameFormat" BO_ 2621440068 15;
BA_ "DiagResponse" BO_ 2621571140 1;
BA_ "MsgType" BO_ 2621571140 4;
BA_ "VFrameFormat" BO_ 2621571140 15;
BA_ "DiagRequest" BO_ 2550399003 1;
BA_ "MsgType" BO_ 2550399003 4;
BA_ "VFrameFormat" BO_ 2550399003 15;
BA_ "DiagRequest" BO_ 2621702171 1;
BA_ "MsgType" BO_ 2621702171 4;
BA_ "VFrameFormat" BO_ 2621702171 15;
BA_ "DiagResponse" BO_ 2550530075 1;
BA_ "MsgType" BO_ 2550530075 4;
BA_ "VFrameFormat" BO_ 2550530075 15;
BA_ "DiagResponse" BO_ 2621833243 1;
BA_ "MsgType" BO_ 2621833243 4;
BA_ "VFrameFormat" BO_ 2621833243 15;
BA_ "GenMsgCycleTime" BO_ 792 80;
BA_ "GenMsgILSupport" BO_ 792 1;
BA_ "GenMsgSendType" BO_ 792 0;
BA_ "VFrameFormat" BO_ 792 14;
BA_ "GenMsgChkConstant" BO_ 960 195;
BA_ "GenMsgCycleTime" BO_ 960 100;
BA_ "GenMsgDelayTime" BO_ 960 10;
BA_ "GenMsgILSupport" BO_ 960 1;
BA_ "GenMsgPDUConstants" BO_ 960 "0xc3,0xc3,0xc3,0xc3,0xc3,0xc3,0xc3,0xc3,0xc3,0xc3,0xc3,0xc3,0xc3,0xc3,0xc3,0xc3";
BA_ "GenMsgSendType" BO_ 960 0;
BA_ "VFrameFormat" BO_ 960 14;
BA_ "GenMsgCycleTime" BO_ 2463978753 1000;
BA_ "GenMsgCycleTimeFast" BO_ 2463978753 100;
BA_ "GenMsgDelayTime" BO_ 2463978753 10;
BA_ "GenMsgILSupport" BO_ 2463978753 1;
BA_ "GenMsgNrOfRepetition" BO_ 2463978753 5;
BA_ "GenMsgPDUConstants" BO_ 2463978753 "0x80,0xf1,0xa5,0xaf,0x94,0x59,0xe8,0x8c,0x03,0xd4,0xf5,0x5e,0xec,0x73,0x81,0x50";
BA_ "GenMsgSendType" BO_ 2463978753 0;
BA_ "VFrameFormat" BO_ 2463978753 15;
BA_ "GenMsgCycleTime" BO_ 1646 2000;
BA_ "GenMsgDelayTime" BO_ 1646 200;
BA_ "GenMsgILSupport" BO_ 1646 1;
BA_ "GenMsgSendType" BO_ 1646 0;
BA_ "VFrameFormat" BO_ 1646 14;
BA_ "GenMsgCycleTime" BO_ 1649 2000;
BA_ "GenMsgDelayTime" BO_ 1649 200;
BA_ "GenMsgILSupport" BO_ 1649 1;
BA_ "GenMsgSendType" BO_ 1649 0;
BA_ "VFrameFormat" BO_ 1649 14;
BA_ "GenMsgCycleTime" BO_ 949 100;
BA_ "GenMsgILSupport" BO_ 949 1;
BA_ "GenMsgSendType" BO_ 949 0;
BA_ "VFrameFormat" BO_ 949 14;
BA_ "GenSigSendType" SG_ 2463978703 HVLM_GBT_01_BZ 0;
BA_ "GenSigFuncType" SG_ 2463978703 HVLM_GBT_01_BZ 1;
BA_ "GenSigSwitchedByIgnition" SG_ 2463978703 HVLM_GBT_01_BZ 0;
BA_ "GenSigSendType" SG_ 2463978703 HVLM_GBT_01_Sendestatus 6;
BA_ "GenSigSwitchedByIgnition" SG_ 2463978703 HVLM_GBT_01_Sendestatus 0;
BA_ "GenSigSendType" SG_ 2463978703 HVLM_GBT_BCL_Ladeverfahren 0;
BA_ "GenSigSwitchedByIgnition" SG_ 2463978703 HVLM_GBT_BCL_Ladeverfahren 0;
BA_ "Fehlerwert" SG_ 2463978703 HVLM_GBT_BCL_Ladeverfahren 3;
BA_ "GenSigSendType" SG_ 2463978703 HVLM_GBT_BCL_Sollspannung 0;
BA_ "GenSigStartValue" SG_ 2463978703 HVLM_GBT_BCL_Sollspannung 16382;
BA_ "GenSigSwitchedByIgnition" SG_ 2463978703 HVLM_GBT_BCL_Sollspannung 0;
BA_ "Fehlerwert" SG_ 2463978703 HVLM_GBT_BCL_Sollspannung 16383;
BA_ "GenSigSendType" SG_ 2463978703 HVLM_GBT_BCL_Sollstrom 0;
BA_ "GenSigStartValue" SG_ 2463978703 HVLM_GBT_BCL_Sollstrom 16382;
BA_ "GenSigSwitchedByIgnition" SG_ 2463978703 HVLM_GBT_BCL_Sollstrom 0;
BA_ "Fehlerwert" SG_ 2463978703 HVLM_GBT_BCL_Sollstrom 16383;
BA_ "GenSigSendType" SG_ 2463978703 HVLM_GBT_BCP_Ist_Spannung_HvBatt 0;
BA_ "GenSigStartValue" SG_ 2463978703 HVLM_GBT_BCP_Ist_Spannung_HvBatt 16382;
BA_ "GenSigSwitchedByIgnition" SG_ 2463978703 HVLM_GBT_BCP_Ist_Spannung_HvBatt 0;
BA_ "Fehlerwert" SG_ 2463978703 HVLM_GBT_BCP_Ist_Spannung_HvBatt 16383;
BA_ "GenSigSendType" SG_ 2463978703 HVLM_GBT_BCP_MaxLadestrom_Fzg 0;
BA_ "GenSigStartValue" SG_ 2463978703 HVLM_GBT_BCP_MaxLadestrom_Fzg 16382;
BA_ "GenSigSwitchedByIgnition" SG_ 2463978703 HVLM_GBT_BCP_MaxLadestrom_Fzg 0;
BA_ "Fehlerwert" SG_ 2463978703 HVLM_GBT_BCP_MaxLadestrom_Fzg 16383;
BA_ "GenSigSendType" SG_ 2463978703 HVLM_GBT_BCP_MaxTemperatur 0;
BA_ "GenSigStartValue" SG_ 2463978703 HVLM_GBT_BCP_MaxTemperatur 254;
BA_ "GenSigSwitchedByIgnition" SG_ 2463978703 HVLM_GBT_BCP_MaxTemperatur 0;
BA_ "Fehlerwert" SG_ 2463978703 HVLM_GBT_BCP_MaxTemperatur 255;
BA_ "GenSigSendType" SG_ 2463978703 HVLM_GBT_BCP_MaxZellladespannung 0;
BA_ "GenSigStartValue" SG_ 2463978703 HVLM_GBT_BCP_MaxZellladespannung 4094;
BA_ "GenSigSwitchedByIgnition" SG_ 2463978703 HVLM_GBT_BCP_MaxZellladespannung 0;
BA_ "Fehlerwert" SG_ 2463978703 HVLM_GBT_BCP_MaxZellladespannung 4095;
BA_ "GenSigSendType" SG_ 2463978703 HVLM_GBT_BCP_Nennenergiegehalt 0;
BA_ "GenSigStartValue" SG_ 2463978703 HVLM_GBT_BCP_Nennenergiegehalt 16382;
BA_ "GenSigSwitchedByIgnition" SG_ 2463978703 HVLM_GBT_BCP_Nennenergiegehalt 0;
BA_ "Fehlerwert" SG_ 2463978703 HVLM_GBT_BCP_Nennenergiegehalt 16383;
BA_ "GenSigSendType" SG_ 2463978703 HVLM_GBT_BCP_StartSOC 0;
BA_ "GenSigStartValue" SG_ 2463978703 HVLM_GBT_BCP_StartSOC 1022;
BA_ "GenSigSwitchedByIgnition" SG_ 2463978703 HVLM_GBT_BCP_StartSOC 0;
BA_ "Fehlerwert" SG_ 2463978703 HVLM_GBT_BCP_StartSOC 1023;
BA_ "GenSigSendType" SG_ 2463978703 HVLM_GBT_BCS_GroupNr_Uzellmax_v2 0;
BA_ "GenSigSwitchedByIgnition" SG_ 2463978703 HVLM_GBT_BCS_GroupNr_Uzellmax_v2 0;
BA_ "GenSigSendType" SG_ 2463978703 HVLM_GBT_BCS_GruppenNr_Uzellmax 0;
BA_ "GenSigStartValue" SG_ 2463978703 HVLM_GBT_BCS_GruppenNr_Uzellmax 30;
BA_ "GenSigSwitchedByIgnition" SG_ 2463978703 HVLM_GBT_BCS_GruppenNr_Uzellmax 0;
BA_ "Fehlerwert" SG_ 2463978703 HVLM_GBT_BCS_GruppenNr_Uzellmax 31;
BA_ "GenSigSendType" SG_ 2463978703 HVLM_GBT_BCS_Ist_Ladespannung 0;
BA_ "GenSigStartValue" SG_ 2463978703 HVLM_GBT_BCS_Ist_Ladespannung 16382;
BA_ "GenSigSwitchedByIgnition" SG_ 2463978703 HVLM_GBT_BCS_Ist_Ladespannung 0;
BA_ "Fehlerwert" SG_ 2463978703 HVLM_GBT_BCS_Ist_Ladespannung 16383;
BA_ "GenSigSendType" SG_ 2463978703 HVLM_GBT_BCS_Ist_Ladestrom 0;
BA_ "GenSigStartValue" SG_ 2463978703 HVLM_GBT_BCS_Ist_Ladestrom 16382;
BA_ "GenSigSwitchedByIgnition" SG_ 2463978703 HVLM_GBT_BCS_Ist_Ladestrom 0;
BA_ "Fehlerwert" SG_ 2463978703 HVLM_GBT_BCS_Ist_Ladestrom 16383;
BA_ "GenSigSendType" SG_ 2463978703 HVLM_GBT_BCS_Ist_MaxZellspannung 0;
BA_ "GenSigStartValue" SG_ 2463978703 HVLM_GBT_BCS_Ist_MaxZellspannung 4094;
BA_ "GenSigSwitchedByIgnition" SG_ 2463978703 HVLM_GBT_BCS_Ist_MaxZellspannung 0;
BA_ "Fehlerwert" SG_ 2463978703 HVLM_GBT_BCS_Ist_MaxZellspannung 4095;
BA_ "GenSigSendType" SG_ 2463978703 HVLM_GBT_BCS_Ist_Restladezeit 0;
BA_ "GenSigStartValue" SG_ 2463978703 HVLM_GBT_BCS_Ist_Restladezeit 1022;
BA_ "GenSigSwitchedByIgnition" SG_ 2463978703 HVLM_GBT_BCS_Ist_Restladezeit 0;
BA_ "Fehlerwert" SG_ 2463978703 HVLM_GBT_BCS_Ist_Restladezeit 1023;
BA_ "GenSigSendType" SG_ 2463978703 HVLM_GBT_BCS_IstSOC 0;
BA_ "GenSigStartValue" SG_ 2463978703 HVLM_GBT_BCS_IstSOC 126;
BA_ "GenSigSwitchedByIgnition" SG_ 2463978703 HVLM_GBT_BCS_IstSOC 0;
BA_ "Fehlerwert" SG_ 2463978703 HVLM_GBT_BCS_IstSOC 127;
BA_ "GenSigSendType" SG_ 2463978703 HVLM_GBT_BEM_Timeout_CCS 0;
BA_ "GenSigSwitchedByIgnition" SG_ 2463978703 HVLM_GBT_BEM_Timeout_CCS 0;
BA_ "GenSigSendType" SG_ 2463978703 HVLM_GBT_BEM_Timeout_CML 0;
BA_ "GenSigSwitchedByIgnition" SG_ 2463978703 HVLM_GBT_BEM_Timeout_CML 0;
BA_ "GenSigSendType" SG_ 2463978703 HVLM_GBT_BEM_Timeout_CRMnReady 0;
BA_ "GenSigSwitchedByIgnition" SG_ 2463978703 HVLM_GBT_BEM_Timeout_CRMnReady 0;
BA_ "GenSigSendType" SG_ 2463978703 HVLM_GBT_BEM_Timeout_CRMReady 0;
BA_ "GenSigSwitchedByIgnition" SG_ 2463978703 HVLM_GBT_BEM_Timeout_CRMReady 0;
BA_ "GenSigSendType" SG_ 2463978703 HVLM_GBT_BEM_Timeout_CRO 0;
BA_ "GenSigSwitchedByIgnition" SG_ 2463978703 HVLM_GBT_BEM_Timeout_CRO 0;
BA_ "GenSigSendType" SG_ 2463978703 HVLM_GBT_BEM_Timeout_CSD 0;
BA_ "GenSigSwitchedByIgnition" SG_ 2463978703 HVLM_GBT_BEM_Timeout_CSD 0;
BA_ "GenSigSendType" SG_ 2463978703 HVLM_GBT_BEM_Timeout_CST 0;
BA_ "GenSigSwitchedByIgnition" SG_ 2463978703 HVLM_GBT_BEM_Timeout_CST 0;
BA_ "GenSigSendType" SG_ 2463978703 HVLM_GBT_BRM_Batterietyp 0;
BA_ "GenSigSwitchedByIgnition" SG_ 2463978703 HVLM_GBT_BRM_Batterietyp 0;
BA_ "GenSigSendType" SG_ 2463978703 HVLM_GBT_BRM_Nennkapazitaet 0;
BA_ "GenSigStartValue" SG_ 2463978703 HVLM_GBT_BRM_Nennkapazitaet 4094;
BA_ "GenSigSwitchedByIgnition" SG_ 2463978703 HVLM_GBT_BRM_Nennkapazitaet 0;
BA_ "Fehlerwert" SG_ 2463978703 HVLM_GBT_BRM_Nennkapazitaet 4095;
BA_ "GenSigSendType" SG_ 2463978703 HVLM_GBT_BRM_Nennspannung_HvBatt 0;
BA_ "GenSigStartValue" SG_ 2463978703 HVLM_GBT_BRM_Nennspannung_HvBatt 16382;
BA_ "GenSigSwitchedByIgnition" SG_ 2463978703 HVLM_GBT_BRM_Nennspannung_HvBatt 0;
BA_ "Fehlerwert" SG_ 2463978703 HVLM_GBT_BRM_Nennspannung_HvBatt 16383;
BA_ "GenSigSendType" SG_ 2463978703 HVLM_GBT_BRM_ProtokollVersion 0;
BA_ "GenSigSwitchedByIgnition" SG_ 2463978703 HVLM_GBT_BRM_ProtokollVersion 0;
BA_ "GenSigSendType" SG_ 2463978703 HVLM_GBT_BRO_FzgBereitschaft 0;
BA_ "GenSigSwitchedByIgnition" SG_ 2463978703 HVLM_GBT_BRO_FzgBereitschaft 0;
BA_ "Fehlerwert" SG_ 2463978703 HVLM_GBT_BRO_FzgBereitschaft 255;
BA_ "GenSigSendType" SG_ 2463978703 HVLM_GBT_BSD_EndSOC 0;
BA_ "GenSigStartValue" SG_ 2463978703 HVLM_GBT_BSD_EndSOC 126;
BA_ "GenSigSwitchedByIgnition" SG_ 2463978703 HVLM_GBT_BSD_EndSOC 0;
BA_ "Fehlerwert" SG_ 2463978703 HVLM_GBT_BSD_EndSOC 127;
BA_ "GenSigSendType" SG_ 2463978703 HVLM_GBT_BSD_MaxTemperatur 0;
BA_ "GenSigStartValue" SG_ 2463978703 HVLM_GBT_BSD_MaxTemperatur 254;
BA_ "GenSigSwitchedByIgnition" SG_ 2463978703 HVLM_GBT_BSD_MaxTemperatur 0;
BA_ "Fehlerwert" SG_ 2463978703 HVLM_GBT_BSD_MaxTemperatur 255;
BA_ "GenSigSendType" SG_ 2463978703 HVLM_GBT_BSD_MaxZellspannung 0;
BA_ "GenSigStartValue" SG_ 2463978703 HVLM_GBT_BSD_MaxZellspannung 4094;
BA_ "GenSigSwitchedByIgnition" SG_ 2463978703 HVLM_GBT_BSD_MaxZellspannung 0;
BA_ "Fehlerwert" SG_ 2463978703 HVLM_GBT_BSD_MaxZellspannung 4095;
BA_ "GenSigSendType" SG_ 2463978703 HVLM_GBT_BSD_MinTemperatur 0;
BA_ "GenSigStartValue" SG_ 2463978703 HVLM_GBT_BSD_MinTemperatur 254;
BA_ "GenSigSwitchedByIgnition" SG_ 2463978703 HVLM_GBT_BSD_MinTemperatur 0;
BA_ "Fehlerwert" SG_ 2463978703 HVLM_GBT_BSD_MinTemperatur 255;
BA_ "GenSigSendType" SG_ 2463978703 HVLM_GBT_BSD_MinZellspannung 0;
BA_ "GenSigStartValue" SG_ 2463978703 HVLM_GBT_BSD_MinZellspannung 4094;
BA_ "GenSigSwitchedByIgnition" SG_ 2463978703 HVLM_GBT_BSD_MinZellspannung 0;
BA_ "Fehlerwert" SG_ 2463978703 HVLM_GBT_BSD_MinZellspannung 4095;
BA_ "GenSigSendType" SG_ 2463978703 HVLM_GBT_BSM_FzgLadeerlaubnis 0;
BA_ "GenSigSwitchedByIgnition" SG_ 2463978703 HVLM_GBT_BSM_FzgLadeerlaubnis 0;
BA_ "GenSigSendType" SG_ 2463978703 HVLM_GBT_BSM_Ist_MaxTemperatur 0;
BA_ "GenSigStartValue" SG_ 2463978703 HVLM_GBT_BSM_Ist_MaxTemperatur 254;
BA_ "GenSigSwitchedByIgnition" SG_ 2463978703 HVLM_GBT_BSM_Ist_MaxTemperatur 0;
BA_ "Fehlerwert" SG_ 2463978703 HVLM_GBT_BSM_Ist_MaxTemperatur 255;
BA_ "GenSigSendType" SG_ 2463978703 HVLM_GBT_BSM_Ist_MinTemperatur 0;
BA_ "GenSigStartValue" SG_ 2463978703 HVLM_GBT_BSM_Ist_MinTemperatur 254;
BA_ "GenSigSwitchedByIgnition" SG_ 2463978703 HVLM_GBT_BSM_Ist_MinTemperatur 0;
BA_ "Fehlerwert" SG_ 2463978703 HVLM_GBT_BSM_Ist_MinTemperatur 255;
BA_ "GenSigSendType" SG_ 2463978703 HVLM_GBT_BSM_Messpunkt_MaxT 0;
BA_ "GenSigSwitchedByIgnition" SG_ 2463978703 HVLM_GBT_BSM_Messpunkt_MaxT 0;
BA_ "GenSigSendType" SG_ 2463978703 HVLM_GBT_BSM_Messpunkt_MinT 0;
BA_ "GenSigSwitchedByIgnition" SG_ 2463978703 HVLM_GBT_BSM_Messpunkt_MinT 0;
BA_ "GenSigSendType" SG_ 2463978703 HVLM_GBT_BSM_Nr_MaxZellspannung 0;
BA_ "GenSigSwitchedByIgnition" SG_ 2463978703 HVLM_GBT_BSM_Nr_MaxZellspannung 0;
BA_ "GenSigSendType" SG_ 2463978703 HVLM_GBT_BSM_Status_Iso 0;
BA_ "GenSigSwitchedByIgnition" SG_ 2463978703 HVLM_GBT_BSM_Status_Iso 0;
BA_ "GenSigSendType" SG_ 2463978703 HVLM_GBT_BSM_Status_SOC 0;
BA_ "GenSigSwitchedByIgnition" SG_ 2463978703 HVLM_GBT_BSM_Status_SOC 0;
BA_ "GenSigSendType" SG_ 2463978703 HVLM_GBT_BSM_Status_Stecker 0;
BA_ "GenSigSwitchedByIgnition" SG_ 2463978703 HVLM_GBT_BSM_Status_Stecker 0;
BA_ "GenSigSendType" SG_ 2463978703 HVLM_GBT_BSM_Status_Strom 0;
BA_ "GenSigSwitchedByIgnition" SG_ 2463978703 HVLM_GBT_BSM_Status_Strom 0;
BA_ "GenSigSendType" SG_ 2463978703 HVLM_GBT_BSM_Status_Temperatur 0;
BA_ "GenSigSwitchedByIgnition" SG_ 2463978703 HVLM_GBT_BSM_Status_Temperatur 0;
BA_ "GenSigSendType" SG_ 2463978703 HVLM_GBT_BSM_Status_Zellspannung 0;
BA_ "GenSigSwitchedByIgnition" SG_ 2463978703 HVLM_GBT_BSM_Status_Zellspannung 0;
BA_ "GenSigSendType" SG_ 2463978703 HVLM_GBT_BST_Ladeende1_Fahrzeug 3;
BA_ "GenSigSwitchedByIgnition" SG_ 2463978703 HVLM_GBT_BST_Ladeende1_Fahrzeug 0;
BA_ "GenSigSendType" SG_ 2463978703 HVLM_GBT_BST_Ladeende2_Fahrzeug 3;
BA_ "GenSigSwitchedByIgnition" SG_ 2463978703 HVLM_GBT_BST_Ladeende2_Fahrzeug 0;
BA_ "GenSigSendType" SG_ 2463978703 HVLM_GBT_BST_Ladeende3_Fahrzeug 3;
BA_ "GenSigSwitchedByIgnition" SG_ 2463978703 HVLM_GBT_BST_Ladeende3_Fahrzeug 0;
BA_ "GenSigSendType" SG_ 2463978703 HVLM_GBT_BST_Ladeende4_Fahrzeug 3;
BA_ "GenSigSwitchedByIgnition" SG_ 2463978703 HVLM_GBT_BST_Ladeende4_Fahrzeug 0;
BA_ "GenSigSendType" SG_ 2463978703 HVLM_GBT_BST_Ladeende_Fehler1 3;
BA_ "GenSigSwitchedByIgnition" SG_ 2463978703 HVLM_GBT_BST_Ladeende_Fehler1 0;
BA_ "GenSigSendType" SG_ 2463978703 HVLM_GBT_BST_Ladeende_Fehler2 3;
BA_ "GenSigSwitchedByIgnition" SG_ 2463978703 HVLM_GBT_BST_Ladeende_Fehler2 0;
BA_ "GenSigSendType" SG_ 2463978703 HVLM_GBT_BST_Ladeende_Fehler3 3;
BA_ "GenSigSwitchedByIgnition" SG_ 2463978703 HVLM_GBT_BST_Ladeende_Fehler3 0;
BA_ "GenSigSendType" SG_ 2463978703 HVLM_GBT_BST_Ladeende_Fehler4 3;
BA_ "GenSigSwitchedByIgnition" SG_ 2463978703 HVLM_GBT_BST_Ladeende_Fehler4 0;
BA_ "GenSigSendType" SG_ 2463978703 HVLM_GBT_BST_Ladeende_Fehler5 3;
BA_ "GenSigSwitchedByIgnition" SG_ 2463978703 HVLM_GBT_BST_Ladeende_Fehler5 0;
BA_ "GenSigSendType" SG_ 2463978703 HVLM_GBT_BST_Ladeende_Fehler6 3;
BA_ "GenSigSwitchedByIgnition" SG_ 2463978703 HVLM_GBT_BST_Ladeende_Fehler6 0;
BA_ "GenSigSendType" SG_ 2463978703 HVLM_GBT_BST_Ladeende_Fehler7 3;
BA_ "GenSigSwitchedByIgnition" SG_ 2463978703 HVLM_GBT_BST_Ladeende_Fehler7 0;
BA_ "GenSigSendType" SG_ 2463978703 HVLM_GBT_BST_Ladeende_Fehler8 3;
BA_ "GenSigSwitchedByIgnition" SG_ 2463978703 HVLM_GBT_BST_Ladeende_Fehler8 0;
BA_ "GenSigSendType" SG_ 2463978703 HVLM_GBT_BST_Ladeende_Fehler_I 3;
BA_ "GenSigSwitchedByIgnition" SG_ 2463978703 HVLM_GBT_BST_Ladeende_Fehler_I 0;
BA_ "GenSigSendType" SG_ 2463978703 HVLM_GBT_BST_Ladeende_Fehler_U 3;
BA_ "GenSigSwitchedByIgnition" SG_ 2463978703 HVLM_GBT_BST_Ladeende_Fehler_U 0;
BA_ "GenSigSendType" SG_ 2463978703 HVLM_GBT_HvBatt_MaxLadespannung 0;
BA_ "GenSigStartValue" SG_ 2463978703 HVLM_GBT_HvBatt_MaxLadespannung 16382;
BA_ "GenSigSwitchedByIgnition" SG_ 2463978703 HVLM_GBT_HvBatt_MaxLadespannung 0;
BA_ "Fehlerwert" SG_ 2463978703 HVLM_GBT_HvBatt_MaxLadespannung 16383;
BA_ "GenSigSendType" SG_ 2463978703 HVLM_GBT_SendeAnf_BCL 3;
BA_ "GenSigSwitchedByIgnition" SG_ 2463978703 HVLM_GBT_SendeAnf_BCL 0;
BA_ "GenSigSendType" SG_ 2463978703 HVLM_GBT_SendeAnf_BCP 0;
BA_ "GenSigSwitchedByIgnition" SG_ 2463978703 HVLM_GBT_SendeAnf_BCP 0;
BA_ "GenSigSendType" SG_ 2463978703 HVLM_GBT_SendeAnf_BCS 0;
BA_ "GenSigSwitchedByIgnition" SG_ 2463978703 HVLM_GBT_SendeAnf_BCS 0;
BA_ "GenSigSendType" SG_ 2463978703 HVLM_GBT_SendeAnf_BEM 0;
BA_ "GenSigSwitchedByIgnition" SG_ 2463978703 HVLM_GBT_SendeAnf_BEM 0;
BA_ "GenSigSendType" SG_ 2463978703 HVLM_GBT_SendeAnf_BHM 0;
BA_ "GenSigSwitchedByIgnition" SG_ 2463978703 HVLM_GBT_SendeAnf_BHM 0;
BA_ "GenSigSendType" SG_ 2463978703 HVLM_GBT_SendeAnf_BRM 0;
BA_ "GenSigSwitchedByIgnition" SG_ 2463978703 HVLM_GBT_SendeAnf_BRM 0;
BA_ "GenSigSendType" SG_ 2463978703 HVLM_GBT_SendeAnf_BRO 0;
BA_ "GenSigSwitchedByIgnition" SG_ 2463978703 HVLM_GBT_SendeAnf_BRO 0;
BA_ "GenSigSendType" SG_ 2463978703 HVLM_GBT_SendeAnf_BSD 0;
BA_ "GenSigSwitchedByIgnition" SG_ 2463978703 HVLM_GBT_SendeAnf_BSD 0;
BA_ "GenSigSendType" SG_ 2463978703 HVLM_GBT_SendeAnf_BSM 0;
BA_ "GenSigSwitchedByIgnition" SG_ 2463978703 HVLM_GBT_SendeAnf_BSM 0;
BA_ "GenSigSendType" SG_ 2463978703 HVLM_GBT_SendeAnf_BST 3;
BA_ "GenSigSwitchedByIgnition" SG_ 2463978703 HVLM_GBT_SendeAnf_BST 0;
BA_ "GenSigSendType" SG_ 2463978703 HVLM_GBT_Status_Control 0;
BA_ "GenSigSwitchedByIgnition" SG_ 2463978703 HVLM_GBT_Status_Control 0;
BA_ "GenSigSendType" SG_ 2463978877 SOK_HVLM_GBT_01_Signatur_02 0;
BA_ "GenSigFuncType" SG_ 2463978877 SOK_HVLM_GBT_01_Signatur_02 15;
BA_ "GenSigSwitchedByIgnition" SG_ 2463978877 SOK_HVLM_GBT_01_Signatur_02 0;
BA_ "GenSigSendType" SG_ 2463978707 HVLM_AnforderungPLTabellen 0;
BA_ "GenSigSwitchedByIgnition" SG_ 2463978707 HVLM_AnforderungPLTabellen 0;
BA_ "GenSigSendType" SG_ 2463978707 HVLM_FehlerFzgPlc 0;
BA_ "GenSigStartValue" SG_ 2463978707 HVLM_FehlerFzgPlc 14;
BA_ "GenSigSwitchedByIgnition" SG_ 2463978707 HVLM_FehlerFzgPlc 0;
BA_ "Fehlerwert" SG_ 2463978707 HVLM_FehlerFzgPlc 15;
BA_ "GenSigSendType" SG_ 2463978707 HVLM_LadeartAnfFzgPlc 0;
BA_ "GenSigStartValue" SG_ 2463978707 HVLM_LadeartAnfFzgPlc 15;
BA_ "GenSigSwitchedByIgnition" SG_ 2463978707 HVLM_LadeartAnfFzgPlc 0;
BA_ "GenSigSendType" SG_ 2463978707 HVLM_LadebereitFzgPlc 0;
BA_ "GenSigSwitchedByIgnition" SG_ 2463978707 HVLM_LadebereitFzgPlc 0;
BA_ "GenSigSendType" SG_ 2463978707 HVLM_LadenAbgeschlPlc 0;
BA_ "GenSigSwitchedByIgnition" SG_ 2463978707 HVLM_LadenAbgeschlPlc 0;
BA_ "GenSigSendType" SG_ 2463978707 HVLM_LadeSessionPlc 0;
BA_ "GenSigSwitchedByIgnition" SG_ 2463978707 HVLM_LadeSessionPlc 0;
BA_ "GenSigSendType" SG_ 2463978707 HVLM_LadezustandHvBatFzgPlc 0;
BA_ "GenSigStartValue" SG_ 2463978707 HVLM_LadezustandHvBatFzgPlc 126;
BA_ "GenSigSwitchedByIgnition" SG_ 2463978707 HVLM_LadezustandHvBatFzgPlc 0;
BA_ "Fehlerwert" SG_ 2463978707 HVLM_LadezustandHvBatFzgPlc 127;
BA_ "GenSigSendType" SG_ 2463978707 HVLM_maxLadespannungFzgPlc 0;
BA_ "GenSigStartValue" SG_ 2463978707 HVLM_maxLadespannungFzgPlc 16382;
BA_ "GenSigSwitchedByIgnition" SG_ 2463978707 HVLM_maxLadespannungFzgPlc 0;
BA_ "Fehlerwert" SG_ 2463978707 HVLM_maxLadespannungFzgPlc 16383;
BA_ "GenSigSendType" SG_ 2463978707 HVLM_maxLadestromFzgPlc 0;
BA_ "GenSigStartValue" SG_ 2463978707 HVLM_maxLadestromFzgPlc 8190;
BA_ "GenSigSwitchedByIgnition" SG_ 2463978707 HVLM_maxLadestromFzgPlc 0;
BA_ "Fehlerwert" SG_ 2463978707 HVLM_maxLadestromFzgPlc 8191;
BA_ "GenSigSendType" SG_ 2463978707 HVLM_maxLadestromFzgPlc_2 0;
BA_ "GenSigStartValue" SG_ 2463978707 HVLM_maxLadestromFzgPlc_2 16382;
BA_ "GenSigSwitchedByIgnition" SG_ 2463978707 HVLM_maxLadestromFzgPlc_2 0;
BA_ "Fehlerwert" SG_ 2463978707 HVLM_maxLadestromFzgPlc_2 16383;
BA_ "GenSigSendType" SG_ 2463978707 HVLM_minLadestromFzgPlc 3;
BA_ "GenSigStartValue" SG_ 2463978707 HVLM_minLadestromFzgPlc 1022;
BA_ "GenSigSwitchedByIgnition" SG_ 2463978707 HVLM_minLadestromFzgPlc 0;
BA_ "Fehlerwert" SG_ 2463978707 HVLM_minLadestromFzgPlc 1023;
BA_ "GenSigSendType" SG_ 2463978707 HVLM_MsgTriggerFzgPlc 0;
BA_ "GenSigSwitchedByIgnition" SG_ 2463978707 HVLM_MsgTriggerFzgPlc 0;
BA_ "GenSigSendType" SG_ 2463978707 HVLM_NormFzgPlc 3;
BA_ "GenSigSwitchedByIgnition" SG_ 2463978707 HVLM_NormFzgPlc 0;
BA_ "GenSigSendType" SG_ 2463978707 HVLM_PLC_01_BZ 0;
BA_ "GenSigFuncType" SG_ 2463978707 HVLM_PLC_01_BZ 1;
BA_ "GenSigSwitchedByIgnition" SG_ 2463978707 HVLM_PLC_01_BZ 0;
BA_ "GenSigSendType" SG_ 2463978707 HVLM_PlcAnforderung 4;
BA_ "GenSigStartValue" SG_ 2463978707 HVLM_PlcAnforderung 3;
BA_ "GenSigSwitchedByIgnition" SG_ 2463978707 HVLM_PlcAnforderung 0;
BA_ "GenSigSendType" SG_ 2463978707 HVLM_PlcKommLadedose 4;
BA_ "GenSigSwitchedByIgnition" SG_ 2463978707 HVLM_PlcKommLadedose 0;
BA_ "GenSigSendType" SG_ 2463978707 HVLM_PlcModemAktivieren 6;
BA_ "GenSigSwitchedByIgnition" SG_ 2463978707 HVLM_PlcModemAktivieren 0;
BA_ "GenSigSendType" SG_ 2463978707 HVLM_ReadyToChargeState 0;
BA_ "GenSigSwitchedByIgnition" SG_ 2463978707 HVLM_ReadyToChargeState 0;
BA_ "GenSigSendType" SG_ 2463978707 HVLM_RestladezeitFzgPlc 0;
BA_ "GenSigSwitchedByIgnition" SG_ 2463978707 HVLM_RestladezeitFzgPlc 0;
BA_ "GenSigSendType" SG_ 2463978707 HVLM_RestladezeitTeilladungPlc 0;
BA_ "GenSigSwitchedByIgnition" SG_ 2463978707 HVLM_RestladezeitTeilladungPlc 0;
BA_ "GenSigSendType" SG_ 2463978707 HVLM_SollstromFzgPlc_2 0;
BA_ "GenSigStartValue" SG_ 2463978707 HVLM_SollstromFzgPlc_2 16382;
BA_ "GenSigSwitchedByIgnition" SG_ 2463978707 HVLM_SollstromFzgPlc_2 0;
BA_ "Fehlerwert" SG_ 2463978707 HVLM_SollstromFzgPlc_2 16383;
BA_ "GenSigSendType" SG_ 2463978707 HVLM_TLS_PnC_Authenfizierung 0;
BA_ "GenSigSwitchedByIgnition" SG_ 2463978707 HVLM_TLS_PnC_Authenfizierung 0;
BA_ "GenSigSendType" SG_ 2463978707 HVLM_ZahlungsmethodeFzgPlc 0;
BA_ "GenSigStartValue" SG_ 2463978707 HVLM_ZahlungsmethodeFzgPlc 1;
BA_ "GenSigSwitchedByIgnition" SG_ 2463978707 HVLM_ZahlungsmethodeFzgPlc 0;
BA_ "GenSigSendType" SG_ 2463978707 HVLM_ZielladespannungFzgPlc 0;
BA_ "GenSigStartValue" SG_ 2463978707 HVLM_ZielladespannungFzgPlc 16382;
BA_ "GenSigSwitchedByIgnition" SG_ 2463978707 HVLM_ZielladespannungFzgPlc 0;
BA_ "Fehlerwert" SG_ 2463978707 HVLM_ZielladespannungFzgPlc 16383;
BA_ "GenSigSendType" SG_ 2463978798 SOK_HVLM_PLC_01_Signatur 0;
BA_ "GenSigFuncType" SG_ 2463978798 SOK_HVLM_PLC_01_Signatur 15;
BA_ "GenSigSwitchedByIgnition" SG_ 2463978798 SOK_HVLM_PLC_01_Signatur 0;
BA_ "GenSigSendType" SG_ 2589283690 HVLE_eTM_max_Vorlauftemperatur 0;
BA_ "GenSigStartValue" SG_ 2589283690 HVLE_eTM_max_Vorlauftemperatur 254;
BA_ "GenSigSwitchedByIgnition" SG_ 2589283690 HVLE_eTM_max_Vorlauftemperatur 0;
BA_ "Fehlerwert" SG_ 2589283690 HVLE_eTM_max_Vorlauftemperatur 255;
BA_ "GenSigSendType" SG_ 2589283690 HVLE_Temperatur 0;
BA_ "GenSigStartValue" SG_ 2589283690 HVLE_Temperatur 254;
BA_ "Fehlerwert" SG_ 2589283690 HVLE_Temperatur 255;
BA_ "GenSigSendType" SG_ 2589283690 HVLE_ThermAuslastungsgrad 0;
BA_ "GenSigStartValue" SG_ 2589283690 HVLE_ThermAuslastungsgrad 254;
BA_ "GenSigSwitchedByIgnition" SG_ 2589283690 HVLE_ThermAuslastungsgrad 0;
BA_ "Fehlerwert" SG_ 2589283690 HVLE_ThermAuslastungsgrad 255;
BA_ "GenSigSendType" SG_ 2589283690 IPB_ThermAuslastungsgrad 0;
BA_ "GenSigSwitchedByIgnition" SG_ 2589283690 IPB_ThermAuslastungsgrad 0;
BA_ "Fehlerwert" SG_ 2589283690 IPB_ThermAuslastungsgrad 255;
BA_ "GenSigSendType" SG_ 2589283690 IPB_Wasser_TEMP_AUS 0;
BA_ "GenSigSwitchedByIgnition" SG_ 2589283690 IPB_Wasser_TEMP_AUS 0;
BA_ "Fehlerwert" SG_ 2589283690 IPB_Wasser_TEMP_AUS 255;
BA_ "GenSigSendType" SG_ 2589283690 IPB_Wasser_TEMP_EIN 0;
BA_ "GenSigSwitchedByIgnition" SG_ 2589283690 IPB_Wasser_TEMP_EIN 0;
BA_ "Fehlerwert" SG_ 2589283690 IPB_Wasser_TEMP_EIN 255;
BA_ "GenSigSendType" SG_ 2589283690 LAD_OBD_Lampe_Anf 0;
BA_ "GenSigSwitchedByIgnition" SG_ 2589283690 LAD_OBD_Lampe_Anf 0;
BA_ "GenSigSendType" SG_ 2589283690 OBDProtocol_Ladegeraet 0;
BA_ "GenSigStartValue" SG_ 2589283690 OBDProtocol_Ladegeraet 254;
BA_ "GenSigSwitchedByIgnition" SG_ 2589283690 OBDProtocol_Ladegeraet 0;
BA_ "Fehlerwert" SG_ 2589283690 OBDProtocol_Ladegeraet 255;
BA_ "GenSigSendType" SG_ 2589283690 TNV_Temperatur 0;
BA_ "GenSigSwitchedByIgnition" SG_ 2589283690 TNV_Temperatur 0;
BA_ "Fehlerwert" SG_ 2589283690 TNV_Temperatur 255;
BA_ "GenSigSendType" SG_ 2589283695 SOK_IPB_03_Signatur 0;
BA_ "GenSigFuncType" SG_ 2589283695 SOK_IPB_03_Signatur 15;
BA_ "GenSigSwitchedByIgnition" SG_ 2589283695 SOK_IPB_03_Signatur 0;
BA_ "GenSigSendType" SG_ 1857 ISO_DCDC_Req_Data 3;
BA_ "GenSigFuncType" SG_ 1857 ISO_DCDC_Req_Data 9;
BA_ "GenSigSwitchedByIgnition" SG_ 1857 ISO_DCDC_Req_Data 0;
BA_ "GenSigSendType" SG_ 1963 ISO_DCDC_Resp_Data 3;
BA_ "GenSigFuncType" SG_ 1963 ISO_DCDC_Resp_Data 9;
BA_ "GenSigSwitchedByIgnition" SG_ 1963 ISO_DCDC_Resp_Data 0;
BA_ "GenSigSendType" SG_ 1792 ISO_ALL_01_Req_Data 3;
BA_ "GenSigFuncType" SG_ 1792 ISO_ALL_01_Req_Data 9;
BA_ "GenSigSwitchedByIgnition" SG_ 1792 ISO_ALL_01_Req_Data 0;
BA_ "GenSigSendType" SG_ 1862 ISO_Klima_Req_Data 3;
BA_ "GenSigFuncType" SG_ 1862 ISO_Klima_Req_Data 9;
BA_ "GenSigSwitchedByIgnition" SG_ 1862 ISO_Klima_Req_Data 0;
BA_ "GenSigSendType" SG_ 1968 ISO_Klima_Resp_Data 3;
BA_ "GenSigFuncType" SG_ 1968 ISO_Klima_Resp_Data 9;
BA_ "GenSigSwitchedByIgnition" SG_ 1968 ISO_Klima_Resp_Data 0;
BA_ "GenSigSendType" SG_ 1860 ISO_Ladegeraet_Req_Data 3;
BA_ "GenSigFuncType" SG_ 1860 ISO_Ladegeraet_Req_Data 9;
BA_ "GenSigSwitchedByIgnition" SG_ 1860 ISO_Ladegeraet_Req_Data 0;
BA_ "GenSigSendType" SG_ 1966 ISO_Ladegeraet_Resp_Data 3;
BA_ "GenSigFuncType" SG_ 1966 ISO_Ladegeraet_Resp_Data 9;
BA_ "GenSigSwitchedByIgnition" SG_ 1966 ISO_Ladegeraet_Resp_Data 0;
BA_ "GenSigActiveRepetitions" SG_ 2463978775 HVLX_GeneratorMode 5;
BA_ "GenSigSendType" SG_ 2463978775 HVLX_GeneratorMode 4;
BA_ "GenSigSendType" SG_ 2463978775 HVLX_Isond_EigenstromLadenStatus 4;
BA_ "GenSigSwitchedByIgnition" SG_ 2463978775 HVLX_Isond_EigenstromLadenStatus 0;
BA_ "GenSigSendType" SG_ 2463978775 HVLX_Isond_EVSEProcessing_Status 4;
BA_ "GenSigSwitchedByIgnition" SG_ 2463978775 HVLX_Isond_EVSEProcessing_Status 0;
BA_ "GenSigSendType" SG_ 2463978775 HVLX_ISOND_EVSEResponseMaxDelay 4;
BA_ "GenSigStartValue" SG_ 2463978775 HVLX_ISOND_EVSEResponseMaxDelay 65534;
BA_ "Fehlerwert" SG_ 2463978775 HVLX_ISOND_EVSEResponseMaxDelay 65535;
BA_ "GenSigSendType" SG_ 2463978775 HVLX_ISOND_FODStatus 4;
BA_ "GenSigActiveRepetitions" SG_ 2463978775 HVLX_ISOND_GADcLeistung 5;
BA_ "GenSigInactiveValue" SG_ 2463978775 HVLX_ISOND_GADcLeistung 4094;
BA_ "GenSigSendType" SG_ 2463978775 HVLX_ISOND_GADcLeistung 6;
BA_ "Fehlerwert" SG_ 2463978775 HVLX_ISOND_GADcLeistung 4095;
BA_ "GenSigActiveRepetitions" SG_ 2463978775 HVLX_ISOND_GAFrequenz 5;
BA_ "GenSigInactiveValue" SG_ 2463978775 HVLX_ISOND_GAFrequenz 16382;
BA_ "GenSigSendType" SG_ 2463978775 HVLX_ISOND_GAFrequenz 6;
BA_ "Fehlerwert" SG_ 2463978775 HVLX_ISOND_GAFrequenz 16383;
BA_ "GenSigActiveRepetitions" SG_ 2463978775 HVLX_ISOND_GALeistungNetz 5;
BA_ "GenSigInactiveValue" SG_ 2463978775 HVLX_ISOND_GALeistungNetz 4094;
BA_ "GenSigSendType" SG_ 2463978775 HVLX_ISOND_GALeistungNetz 6;
BA_ "Fehlerwert" SG_ 2463978775 HVLX_ISOND_GALeistungNetz 4095;
BA_ "GenSigActiveRepetitions" SG_ 2463978775 HVLX_ISOND_GASpulenstrom 5;
BA_ "GenSigInactiveValue" SG_ 2463978775 HVLX_ISOND_GASpulenstrom 1022;
BA_ "GenSigSendType" SG_ 2463978775 HVLX_ISOND_GASpulenstrom 6;
BA_ "Fehlerwert" SG_ 2463978775 HVLX_ISOND_GASpulenstrom 1023;
BA_ "GenSigSendType" SG_ 2463978775 HVLX_Isond_IsoStatusLadesaeule 4;
BA_ "GenSigSwitchedByIgnition" SG_ 2463978775 HVLX_Isond_IsoStatusLadesaeule 0;
BA_ "GenSigSendType" SG_ 2463978775 HVLX_Isond_IstEnergiemengeLsPlc 4;
BA_ "Fehlerwert" SG_ 2463978775 HVLX_Isond_IstEnergiemengeLsPlc 8191;
BA_ "GenSigInactiveValue" SG_ 2463978775 HVLX_Isond_IstSpannungACLsPlc 510;
BA_ "GenSigSendType" SG_ 2463978775 HVLX_Isond_IstSpannungACLsPlc 5;
BA_ "GenSigStartValue" SG_ 2463978775 HVLX_Isond_IstSpannungACLsPlc 510;
BA_ "GenSigSwitchedByIgnition" SG_ 2463978775 HVLX_Isond_IstSpannungACLsPlc 0;
BA_ "Fehlerwert" SG_ 2463978775 HVLX_Isond_IstSpannungACLsPlc 511;
BA_ "GenSigInactiveValue" SG_ 2463978775 HVLX_Isond_IstSpannungLadesaeule 16382;
BA_ "GenSigSendType" SG_ 2463978775 HVLX_Isond_IstSpannungLadesaeule 5;
BA_ "GenSigStartValue" SG_ 2463978775 HVLX_Isond_IstSpannungLadesaeule 16382;
BA_ "GenSigSwitchedByIgnition" SG_ 2463978775 HVLX_Isond_IstSpannungLadesaeule 0;
BA_ "Fehlerwert" SG_ 2463978775 HVLX_Isond_IstSpannungLadesaeule 16383;
BA_ "GenSigInactiveValue" SG_ 2463978775 HVLX_Isond_IstStromLadesaeule 16382;
BA_ "GenSigSendType" SG_ 2463978775 HVLX_Isond_IstStromLadesaeule 5;
BA_ "GenSigStartValue" SG_ 2463978775 HVLX_Isond_IstStromLadesaeule 16382;
BA_ "GenSigSwitchedByIgnition" SG_ 2463978775 HVLX_Isond_IstStromLadesaeule 0;
BA_ "Fehlerwert" SG_ 2463978775 HVLX_Isond_IstStromLadesaeule 16383;
BA_ "GenSigSendType" SG_ 2463978775 HVLX_Isond_LadeartAC1PCorePlc 4;
BA_ "GenSigSwitchedByIgnition" SG_ 2463978775 HVLX_Isond_LadeartAC1PCorePlc 0;
BA_ "GenSigSendType" SG_ 2463978775 HVLX_Isond_LadeartAC3PCorePlc 4;
BA_ "GenSigSwitchedByIgnition" SG_ 2463978775 HVLX_Isond_LadeartAC3PCorePlc 0;
BA_ "GenSigSendType" SG_ 2463978775 HVLX_Isond_LadeartDCComboCorePlc 4;
BA_ "GenSigSwitchedByIgnition" SG_ 2463978775 HVLX_Isond_LadeartDCComboCorePlc 0;
BA_ "GenSigSendType" SG_ 2463978775 HVLX_Isond_LadeartDCCorePlc 4;
BA_ "GenSigSwitchedByIgnition" SG_ 2463978775 HVLX_Isond_LadeartDCCorePlc 0;
BA_ "GenSigSendType" SG_ 2463978775 HVLX_Isond_LadeartDCExtendedPlc 4;
BA_ "GenSigSwitchedByIgnition" SG_ 2463978775 HVLX_Isond_LadeartDCExtendedPlc 0;
BA_ "GenSigSendType" SG_ 2463978775 HVLX_Isond_LadeartDCUniquePlc 4;
BA_ "GenSigSwitchedByIgnition" SG_ 2463978775 HVLX_Isond_LadeartDCUniquePlc 0;
BA_ "GenSigActiveRepetitions" SG_ 2463978775 HVLX_Isond_LadeartWpt 5;
BA_ "GenSigSendType" SG_ 2463978775 HVLX_Isond_LadeartWpt 4;
BA_ "GenSigSendType" SG_ 2463978775 HVLX_Isond_LadeplanErhaltenHlc 4;
BA_ "GenSigSwitchedByIgnition" SG_ 2463978775 HVLX_Isond_LadeplanErhaltenHlc 0;
BA_ "Fehlerwert" SG_ 2463978775 HVLX_Isond_LadeplanErhaltenHlc 3;
BA_ "GenSigActiveRepetitions" SG_ 2463978775 HVLX_ISOND_LeistungsanfEV 5;
BA_ "GenSigInactiveValue" SG_ 2463978775 HVLX_ISOND_LeistungsanfEV 4094;
BA_ "GenSigSendType" SG_ 2463978775 HVLX_ISOND_LeistungsanfEV 6;
BA_ "Fehlerwert" SG_ 2463978775 HVLX_ISOND_LeistungsanfEV 4095;
BA_ "GenSigSendType" SG_ 2463978775 HVLX_ISOND_LOPStatus 4;
BA_ "GenSigSendType" SG_ 2463978775 HVLX_Isond_LsNotification_Plc 4;
BA_ "GenSigSwitchedByIgnition" SG_ 2463978775 HVLX_Isond_LsNotification_Plc 0;
BA_ "GenSigInactiveValue" SG_ 2463978775 HVLX_Isond_maxAcAbgabestromL1 1022;
BA_ "GenSigSendType" SG_ 2463978775 HVLX_Isond_maxAcAbgabestromL1 5;
BA_ "GenSigStartValue" SG_ 2463978775 HVLX_Isond_maxAcAbgabestromL1 1022;
BA_ "GenSigSwitchedByIgnition" SG_ 2463978775 HVLX_Isond_maxAcAbgabestromL1 0;
BA_ "Fehlerwert" SG_ 2463978775 HVLX_Isond_maxAcAbgabestromL1 1023;
BA_ "GenSigInactiveValue" SG_ 2463978775 HVLX_Isond_maxAcAbgabestromL2 1022;
BA_ "GenSigSendType" SG_ 2463978775 HVLX_Isond_maxAcAbgabestromL2 5;
BA_ "GenSigStartValue" SG_ 2463978775 HVLX_Isond_maxAcAbgabestromL2 1022;
BA_ "GenSigSwitchedByIgnition" SG_ 2463978775 HVLX_Isond_maxAcAbgabestromL2 0;
BA_ "Fehlerwert" SG_ 2463978775 HVLX_Isond_maxAcAbgabestromL2 1023;
BA_ "GenSigInactiveValue" SG_ 2463978775 HVLX_Isond_maxAcAbgabestromL3 1022;
BA_ "GenSigSendType" SG_ 2463978775 HVLX_Isond_maxAcAbgabestromL3 5;
BA_ "GenSigStartValue" SG_ 2463978775 HVLX_Isond_maxAcAbgabestromL3 1022;
BA_ "GenSigSwitchedByIgnition" SG_ 2463978775 HVLX_Isond_maxAcAbgabestromL3 0;
BA_ "Fehlerwert" SG_ 2463978775 HVLX_Isond_maxAcAbgabestromL3 1023;
BA_ "GenSigInactiveValue" SG_ 2463978775 HVLX_Isond_maxAcEigenstromL1 1022;
BA_ "GenSigSendType" SG_ 2463978775 HVLX_Isond_maxAcEigenstromL1 5;
BA_ "GenSigStartValue" SG_ 2463978775 HVLX_Isond_maxAcEigenstromL1 1022;
BA_ "GenSigSwitchedByIgnition" SG_ 2463978775 HVLX_Isond_maxAcEigenstromL1 0;
BA_ "Fehlerwert" SG_ 2463978775 HVLX_Isond_maxAcEigenstromL1 1023;
BA_ "GenSigInactiveValue" SG_ 2463978775 HVLX_Isond_maxAcEigenstromL2 1022;
BA_ "GenSigSendType" SG_ 2463978775 HVLX_Isond_maxAcEigenstromL2 5;
BA_ "GenSigStartValue" SG_ 2463978775 HVLX_Isond_maxAcEigenstromL2 1022;
BA_ "GenSigSwitchedByIgnition" SG_ 2463978775 HVLX_Isond_maxAcEigenstromL2 0;
BA_ "Fehlerwert" SG_ 2463978775 HVLX_Isond_maxAcEigenstromL2 1023;
BA_ "GenSigInactiveValue" SG_ 2463978775 HVLX_Isond_maxAcEigenstromL3 1022;
BA_ "GenSigSendType" SG_ 2463978775 HVLX_Isond_maxAcEigenstromL3 5;
BA_ "GenSigStartValue" SG_ 2463978775 HVLX_Isond_maxAcEigenstromL3 1022;
BA_ "GenSigSwitchedByIgnition" SG_ 2463978775 HVLX_Isond_maxAcEigenstromL3 0;
BA_ "Fehlerwert" SG_ 2463978775 HVLX_Isond_maxAcEigenstromL3 1023;
BA_ "GenSigSendType" SG_ 2463978775 HVLX_Isond_maxLeistungErreicht 4;
BA_ "GenSigStartValue" SG_ 2463978775 HVLX_Isond_maxLeistungErreicht 3;
BA_ "GenSigSwitchedByIgnition" SG_ 2463978775 HVLX_Isond_maxLeistungErreicht 0;
BA_ "GenSigInactiveValue" SG_ 2463978775 HVLX_Isond_maxLeistungLadesaeule 131070;
BA_ "GenSigSendType" SG_ 2463978775 HVLX_Isond_maxLeistungLadesaeule 5;
BA_ "GenSigStartValue" SG_ 2463978775 HVLX_Isond_maxLeistungLadesaeule 131070;
BA_ "GenSigSwitchedByIgnition" SG_ 2463978775 HVLX_Isond_maxLeistungLadesaeule 0;
BA_ "Fehlerwert" SG_ 2463978775 HVLX_Isond_maxLeistungLadesaeule 131071;
BA_ "GenSigSendType" SG_ 2463978775 HVLX_Isond_maxSpannungErreicht 4;
BA_ "GenSigStartValue" SG_ 2463978775 HVLX_Isond_maxSpannungErreicht 3;
BA_ "GenSigSwitchedByIgnition" SG_ 2463978775 HVLX_Isond_maxSpannungErreicht 0;
BA_ "GenSigInactiveValue" SG_ 2463978775 HVLX_Isond_maxSpannungLadesaeule 16382;
BA_ "GenSigSendType" SG_ 2463978775 HVLX_Isond_maxSpannungLadesaeule 5;
BA_ "GenSigStartValue" SG_ 2463978775 HVLX_Isond_maxSpannungLadesaeule 16382;
BA_ "GenSigSwitchedByIgnition" SG_ 2463978775 HVLX_Isond_maxSpannungLadesaeule 0;
BA_ "Fehlerwert" SG_ 2463978775 HVLX_Isond_maxSpannungLadesaeule 16383;
BA_ "GenSigInactiveValue" SG_ 2463978775 HVLX_Isond_MaxStromACLsPlc 1022;
BA_ "GenSigSendType" SG_ 2463978775 HVLX_Isond_MaxStromACLsPlc 5;
BA_ "GenSigStartValue" SG_ 2463978775 HVLX_Isond_MaxStromACLsPlc 1022;
BA_ "GenSigSwitchedByIgnition" SG_ 2463978775 HVLX_Isond_MaxStromACLsPlc 0;
BA_ "Fehlerwert" SG_ 2463978775 HVLX_Isond_MaxStromACLsPlc 1023;
BA_ "GenSigSendType" SG_ 2463978775 HVLX_Isond_maxStromErreicht 4;
BA_ "GenSigStartValue" SG_ 2463978775 HVLX_Isond_maxStromErreicht 3;
BA_ "GenSigSwitchedByIgnition" SG_ 2463978775 HVLX_Isond_maxStromErreicht 0;
BA_ "GenSigInactiveValue" SG_ 2463978775 HVLX_Isond_maxStromLadesaeule 16382;
BA_ "GenSigSendType" SG_ 2463978775 HVLX_Isond_maxStromLadesaeule 5;
BA_ "GenSigStartValue" SG_ 2463978775 HVLX_Isond_maxStromLadesaeule 16382;
BA_ "GenSigSwitchedByIgnition" SG_ 2463978775 HVLX_Isond_maxStromLadesaeule 0;
BA_ "Fehlerwert" SG_ 2463978775 HVLX_Isond_maxStromLadesaeule 16383;
BA_ "GenSigInactiveValue" SG_ 2463978775 HVLX_Isond_minSpannungLadesaeule 16382;
BA_ "GenSigSendType" SG_ 2463978775 HVLX_Isond_minSpannungLadesaeule 5;
BA_ "GenSigStartValue" SG_ 2463978775 HVLX_Isond_minSpannungLadesaeule 16382;
BA_ "GenSigSwitchedByIgnition" SG_ 2463978775 HVLX_Isond_minSpannungLadesaeule 0;
BA_ "Fehlerwert" SG_ 2463978775 HVLX_Isond_minSpannungLadesaeule 16383;
BA_ "GenSigInactiveValue" SG_ 2463978775 HVLX_Isond_minStromLadesaeule 16382;
BA_ "GenSigSendType" SG_ 2463978775 HVLX_Isond_minStromLadesaeule 5;
BA_ "GenSigStartValue" SG_ 2463978775 HVLX_Isond_minStromLadesaeule 16382;
BA_ "GenSigSwitchedByIgnition" SG_ 2463978775 HVLX_Isond_minStromLadesaeule 0;
BA_ "Fehlerwert" SG_ 2463978775 HVLX_Isond_minStromLadesaeule 16383;
BA_ "GenSigSendType" SG_ 2463978775 HVLX_Isond_NormLsPlc 4;
BA_ "GenSigSwitchedByIgnition" SG_ 2463978775 HVLX_Isond_NormLsPlc 0;
BA_ "Fehlerwert" SG_ 2463978775 HVLX_Isond_NormLsPlc 7;
BA_ "GenSigSendType" SG_ 2463978775 HVLX_Isond_PLC_Message_Status 4;
BA_ "GenSigSwitchedByIgnition" SG_ 2463978775 HVLX_Isond_PLC_Message_Status 0;
BA_ "GenSigSendType" SG_ 2463978775 HVLX_Isond_PlcKommFehler 4;
BA_ "GenSigStartValue" SG_ 2463978775 HVLX_Isond_PlcKommFehler 7;
BA_ "GenSigSwitchedByIgnition" SG_ 2463978775 HVLX_Isond_PlcKommFehler 0;
BA_ "GenSigSendType" SG_ 2463978775 HVLX_ISOND_PncServiceDetailStat 3;
BA_ "GenSigSendType" SG_ 2463978775 HVLX_ISOND_PncServiceDiscovStat 3;
BA_ "Fehlerwert" SG_ 2463978775 HVLX_ISOND_PncServiceDiscovStat 3;
BA_ "GenSigSendType" SG_ 2463978775 HVLX_ISOND_PncZertifikateTrans 3;
BA_ "Fehlerwert" SG_ 2463978775 HVLX_ISOND_PncZertifikateTrans 3;
BA_ "GenSigSendType" SG_ 2463978775 HVLX_Isond_PnCZertifkatErhaltHlc 4;
BA_ "GenSigSwitchedByIgnition" SG_ 2463978775 HVLX_Isond_PnCZertifkatErhaltHlc 0;
BA_ "Fehlerwert" SG_ 2463978775 HVLX_Isond_PnCZertifkatErhaltHlc 3;
BA_ "GenSigSendType" SG_ 2463978775 HVLX_Isond_ResponseCodeLsPlc 4;
BA_ "GenSigStartValue" SG_ 2463978775 HVLX_Isond_ResponseCodeLsPlc 62;
BA_ "GenSigSwitchedByIgnition" SG_ 2463978775 HVLX_Isond_ResponseCodeLsPlc 0;
BA_ "Fehlerwert" SG_ 2463978775 HVLX_Isond_ResponseCodeLsPlc 63;
BA_ "GenSigSendType" SG_ 2463978775 HVLX_Isond_SASTupelErhaltenHlc 4;
BA_ "GenSigSwitchedByIgnition" SG_ 2463978775 HVLX_Isond_SASTupelErhaltenHlc 0;
BA_ "Fehlerwert" SG_ 2463978775 HVLX_Isond_SASTupelErhaltenHlc 3;
BA_ "GenSigSendType" SG_ 2463978775 HVLX_Isond_StatusLadesaeule 4;
BA_ "GenSigStartValue" SG_ 2463978775 HVLX_Isond_StatusLadesaeule 14;
BA_ "GenSigSwitchedByIgnition" SG_ 2463978775 HVLX_Isond_StatusLadesaeule 0;
BA_ "Fehlerwert" SG_ 2463978775 HVLX_Isond_StatusLadesaeule 15;
BA_ "GenSigSendType" SG_ 2463978775 HVLX_Isond_StatusRcdACLsPlc 4;
BA_ "GenSigSwitchedByIgnition" SG_ 2463978775 HVLX_Isond_StatusRcdACLsPlc 0;
BA_ "GenSigInactiveValue" SG_ 2463978775 HVLX_Isond_StromrippelPeakLs 4094;
BA_ "GenSigSendType" SG_ 2463978775 HVLX_Isond_StromrippelPeakLs 5;
BA_ "GenSigStartValue" SG_ 2463978775 HVLX_Isond_StromrippelPeakLs 4094;
BA_ "GenSigSwitchedByIgnition" SG_ 2463978775 HVLX_Isond_StromrippelPeakLs 0;
BA_ "Fehlerwert" SG_ 2463978775 HVLX_Isond_StromrippelPeakLs 4095;
BA_ "GenSigSendType" SG_ 2463978775 HVLX_Isond_TLS_PnC_Status 4;
BA_ "GenSigSwitchedByIgnition" SG_ 2463978775 HVLX_Isond_TLS_PnC_Status 0;
BA_ "GenSigActiveRepetitions" SG_ 2463978775 HVLX_Isond_TlsZertifkatErhaltHlc 5;
BA_ "GenSigSendType" SG_ 2463978775 HVLX_Isond_TlsZertifkatErhaltHlc 4;
BA_ "GenSigSwitchedByIgnition" SG_ 2463978775 HVLX_Isond_TlsZertifkatErhaltHlc 0;
BA_ "Fehlerwert" SG_ 2463978775 HVLX_Isond_TlsZertifkatErhaltHlc 3;
BA_ "GenSigSendType" SG_ 2463978775 HVLX_Isond_VASBedAnzStatus_LsPlc 4;
BA_ "GenSigSwitchedByIgnition" SG_ 2463978775 HVLX_Isond_VASBedAnzStatus_LsPlc 0;
BA_ "GenSigSendType" SG_ 2463978775 HVLX_Isond_VASErwLFStatus_LsPlc 4;
BA_ "GenSigSwitchedByIgnition" SG_ 2463978775 HVLX_Isond_VASErwLFStatus_LsPlc 0;
BA_ "GenSigActiveRepetitions" SG_ 2463978775 HVLX_Isond_VasResponse 5;
BA_ "GenSigSendType" SG_ 2463978775 HVLX_Isond_VasResponse 4;
BA_ "GenSigSwitchedByIgnition" SG_ 2463978775 HVLX_Isond_VasResponse 0;
BA_ "GenSigSendType" SG_ 2463978775 HVLX_Isond_WPT_DevicePosStatus 4;
BA_ "GenSigSendType" SG_ 2463978775 HVLX_Isond_WPT_VehiclePosStatus 4;
BA_ "GenSigSendType" SG_ 2463978775 HVLX_Isond_ZahlererfassungAnfHlc 4;
BA_ "GenSigSwitchedByIgnition" SG_ 2463978775 HVLX_Isond_ZahlererfassungAnfHlc 0;
BA_ "GenSigSendType" SG_ 2463978775 HVLX_Isond_ZahlungsmethodeLs 4;
BA_ "GenSigStartValue" SG_ 2463978775 HVLX_Isond_ZahlungsmethodeLs 3;
BA_ "GenSigSwitchedByIgnition" SG_ 2463978775 HVLX_Isond_ZahlungsmethodeLs 0;
BA_ "GenSigActiveRepetitions" SG_ 2463978775 HVLX_LadeartDCBptPlc 5;
BA_ "GenSigSendType" SG_ 2463978775 HVLX_LadeartDCBptPlc 4;
BA_ "GenSigActiveRepetitions" SG_ 2463978775 HVLX_LSPLC_01_Sendestatus 5;
BA_ "GenSigSendType" SG_ 2463978775 HVLX_LSPLC_01_Sendestatus 6;
BA_ "GenSigSwitchedByIgnition" SG_ 2463978775 HVLX_LSPLC_01_Sendestatus 0;
BA_ "GenSigSendType" SG_ 2463978775 HVLX_maxEntladeLeistungLS 4;
BA_ "GenSigStartValue" SG_ 2463978775 HVLX_maxEntladeLeistungLS 131070;
BA_ "GenSigSendType" SG_ 2463978775 HVLX_maxEntladeStromLadesaeule 4;
BA_ "GenSigStartValue" SG_ 2463978775 HVLX_maxEntladeStromLadesaeule 16382;
BA_ "Fehlerwert" SG_ 2463978775 HVLX_maxEntladeStromLadesaeule 16383;
BA_ "GenSigSendType" SG_ 2463978775 HVLX_minEntladeStromLadesaeule 4;
BA_ "GenSigStartValue" SG_ 2463978775 HVLX_minEntladeStromLadesaeule 16382;
BA_ "Fehlerwert" SG_ 2463978775 HVLX_minEntladeStromLadesaeule 16383;
BA_ "GenSigSendType" SG_ 2463978775 HVLX_PlcFehlerstatus 4;
BA_ "GenSigStartValue" SG_ 2463978775 HVLX_PlcFehlerstatus 7;
BA_ "GenSigSwitchedByIgnition" SG_ 2463978775 HVLX_PlcFehlerstatus 0;
BA_ "GenSigSendType" SG_ 2463978775 HVLX_PlcGefundeneLadesaeule 4;
BA_ "GenSigSwitchedByIgnition" SG_ 2463978775 HVLX_PlcGefundeneLadesaeule 0;
BA_ "GenSigSendType" SG_ 2463978775 HVLX_PlcLinkStatus 4;
BA_ "GenSigStartValue" SG_ 2463978775 HVLX_PlcLinkStatus 6;
BA_ "GenSigSwitchedByIgnition" SG_ 2463978775 HVLX_PlcLinkStatus 0;
BA_ "Fehlerwert" SG_ 2463978775 HVLX_PlcLinkStatus 7;
BA_ "GenSigSendType" SG_ 2549874844 ISOx_BMS_48V_Req_Data 3;
BA_ "GenSigFuncType" SG_ 2549874844 ISOx_BMS_48V_Req_Data 9;
BA_ "GenSigSwitchedByIgnition" SG_ 2549874844 ISOx_BMS_48V_Req_Data 0;
BA_ "GenSigSendType" SG_ 2621440156 ISOx_BMS_48V_Req_FD_Data 3;
BA_ "GenSigFuncType" SG_ 2621440156 ISOx_BMS_48V_Req_FD_Data 9;
BA_ "GenSigSwitchedByIgnition" SG_ 2621440156 ISOx_BMS_48V_Req_FD_Data 0;
BA_ "GenSigSendType" SG_ 2550005916 ISOx_BMS_48V_Resp_Data 3;
BA_ "GenSigFuncType" SG_ 2550005916 ISOx_BMS_48V_Resp_Data 9;
BA_ "GenSigSwitchedByIgnition" SG_ 2550005916 ISOx_BMS_48V_Resp_Data 0;
BA_ "GenSigSendType" SG_ 2621571228 ISOx_BMS_48V_Resp_FD_Data 3;
BA_ "GenSigFuncType" SG_ 2621571228 ISOx_BMS_48V_Resp_FD_Data 9;
BA_ "GenSigSwitchedByIgnition" SG_ 2621571228 ISOx_BMS_48V_Resp_FD_Data 0;
BA_ "GenSigSendType" SG_ 2550399045 ISOx_BMS_NV_Req_Data 3;
BA_ "GenSigFuncType" SG_ 2550399045 ISOx_BMS_NV_Req_Data 9;
BA_ "GenSigSwitchedByIgnition" SG_ 2550399045 ISOx_BMS_NV_Req_Data 0;
BA_ "GenSigSendType" SG_ 2621702213 ISOx_BMS_NV_Req_FD_Data 3;
BA_ "GenSigFuncType" SG_ 2621702213 ISOx_BMS_NV_Req_FD_Data 9;
BA_ "GenSigSwitchedByIgnition" SG_ 2621702213 ISOx_BMS_NV_Req_FD_Data 0;
BA_ "GenSigSendType" SG_ 2550530117 ISOx_BMS_NV_Resp_Data 3;
BA_ "GenSigFuncType" SG_ 2550530117 ISOx_BMS_NV_Resp_Data 9;
BA_ "GenSigSwitchedByIgnition" SG_ 2550530117 ISOx_BMS_NV_Resp_Data 0;
BA_ "GenSigSendType" SG_ 2621833285 ISOx_BMS_NV_Resp_FD_Data 3;
BA_ "GenSigFuncType" SG_ 2621833285 ISOx_BMS_NV_Resp_FD_Data 9;
BA_ "GenSigSwitchedByIgnition" SG_ 2621833285 ISOx_BMS_NV_Resp_FD_Data 0;
BA_ "GenSigSendType" SG_ 2549874873 ISOx_DCDC_NV_Req_Data 3;
BA_ "GenSigFuncType" SG_ 2549874873 ISOx_DCDC_NV_Req_Data 9;
BA_ "GenSigSwitchedByIgnition" SG_ 2549874873 ISOx_DCDC_NV_Req_Data 0;
BA_ "GenSigSendType" SG_ 2621440185 ISOx_DCDC_NV_Req_FD_Data 3;
BA_ "GenSigFuncType" SG_ 2621440185 ISOx_DCDC_NV_Req_FD_Data 9;
BA_ "GenSigSwitchedByIgnition" SG_ 2621440185 ISOx_DCDC_NV_Req_FD_Data 0;
BA_ "GenSigSendType" SG_ 2550005945 ISOx_DCDC_NV_Resp_Data 3;
BA_ "GenSigFuncType" SG_ 2550005945 ISOx_DCDC_NV_Resp_Data 9;
BA_ "GenSigSwitchedByIgnition" SG_ 2550005945 ISOx_DCDC_NV_Resp_Data 0;
BA_ "GenSigSendType" SG_ 2621571257 ISOx_DCDC_NV_Resp_FD_Data 3;
BA_ "GenSigFuncType" SG_ 2621571257 ISOx_DCDC_NV_Resp_FD_Data 9;
BA_ "GenSigSwitchedByIgnition" SG_ 2621571257 ISOx_DCDC_NV_Resp_FD_Data 0;
BA_ "GenSigSendType" SG_ 2621440065 ISOx_DCDC_Req_FD_Data 3;
BA_ "GenSigFuncType" SG_ 2621440065 ISOx_DCDC_Req_FD_Data 9;
BA_ "GenSigSwitchedByIgnition" SG_ 2621440065 ISOx_DCDC_Req_FD_Data 0;
BA_ "GenSigSendType" SG_ 2621571137 ISOx_DCDC_Resp_FD_Data 3;
BA_ "GenSigFuncType" SG_ 2621571137 ISOx_DCDC_Resp_FD_Data 9;
BA_ "GenSigSwitchedByIgnition" SG_ 2621571137 ISOx_DCDC_Resp_FD_Data 0;
BA_ "GenSigSendType" SG_ 2621505536 ISOx_Funkt_Req_All_FD_Data 3;
BA_ "GenSigFuncType" SG_ 2621505536 ISOx_Funkt_Req_All_FD_Data 9;
BA_ "GenSigSwitchedByIgnition" SG_ 2621505536 ISOx_Funkt_Req_All_FD_Data 0;
BA_ "GenSigSendType" SG_ 2549874811 ISOx_Hybrid_01_Req_Data 3;
BA_ "GenSigFuncType" SG_ 2549874811 ISOx_Hybrid_01_Req_Data 9;
BA_ "GenSigSwitchedByIgnition" SG_ 2549874811 ISOx_Hybrid_01_Req_Data 0;
BA_ "GenSigSendType" SG_ 2621440123 ISOx_Hybrid_01_Req_FD_Data 3;
BA_ "GenSigFuncType" SG_ 2621440123 ISOx_Hybrid_01_Req_FD_Data 9;
BA_ "GenSigSwitchedByIgnition" SG_ 2621440123 ISOx_Hybrid_01_Req_FD_Data 0;
BA_ "GenSigSendType" SG_ 2550005883 ISOx_Hybrid_01_Resp_Data 3;
BA_ "GenSigFuncType" SG_ 2550005883 ISOx_Hybrid_01_Resp_Data 9;
BA_ "GenSigSwitchedByIgnition" SG_ 2550005883 ISOx_Hybrid_01_Resp_Data 0;
BA_ "GenSigSendType" SG_ 2621571195 ISOx_Hybrid_01_Resp_FD_Data 3;
BA_ "GenSigFuncType" SG_ 2621571195 ISOx_Hybrid_01_Resp_FD_Data 9;
BA_ "GenSigSwitchedByIgnition" SG_ 2621571195 ISOx_Hybrid_01_Resp_FD_Data 0;
BA_ "GenSigSendType" SG_ 2621440070 ISOx_Klima_Req_FD_Data 3;
BA_ "GenSigFuncType" SG_ 2621440070 ISOx_Klima_Req_FD_Data 9;
BA_ "GenSigSwitchedByIgnition" SG_ 2621440070 ISOx_Klima_Req_FD_Data 0;
BA_ "GenSigSendType" SG_ 2621571142 ISOx_Klima_Resp_FD_Data 3;
BA_ "GenSigFuncType" SG_ 2621571142 ISOx_Klima_Resp_FD_Data 9;
BA_ "GenSigSwitchedByIgnition" SG_ 2621571142 ISOx_Klima_Resp_FD_Data 0;
BA_ "GenSigSendType" SG_ 2621440068 ISOx_Ladegeraet_Req_FD_Data 3;
BA_ "GenSigFuncType" SG_ 2621440068 ISOx_Ladegeraet_Req_FD_Data 9;
BA_ "GenSigSwitchedByIgnition" SG_ 2621440068 ISOx_Ladegeraet_Req_FD_Data 0;
BA_ "GenSigSendType" SG_ 2621571140 ISOx_Ladegeraet_Resp_FD_Data 3;
BA_ "GenSigFuncType" SG_ 2621571140 ISOx_Ladegeraet_Resp_FD_Data 9;
BA_ "GenSigSwitchedByIgnition" SG_ 2621571140 ISOx_Ladegeraet_Resp_FD_Data 0;
BA_ "GenSigSendType" SG_ 2550399003 ISOx_SACID_1_Req_Data 3;
BA_ "GenSigFuncType" SG_ 2550399003 ISOx_SACID_1_Req_Data 9;
BA_ "GenSigSwitchedByIgnition" SG_ 2550399003 ISOx_SACID_1_Req_Data 0;
BA_ "GenSigSendType" SG_ 2621702171 ISOx_SACID_1_Req_FD_Data 3;
BA_ "GenSigFuncType" SG_ 2621702171 ISOx_SACID_1_Req_FD_Data 9;
BA_ "GenSigSwitchedByIgnition" SG_ 2621702171 ISOx_SACID_1_Req_FD_Data 0;
BA_ "GenSigSendType" SG_ 2550530075 ISOx_SACID_1_Resp_Data 3;
BA_ "GenSigFuncType" SG_ 2550530075 ISOx_SACID_1_Resp_Data 9;
BA_ "GenSigSwitchedByIgnition" SG_ 2550530075 ISOx_SACID_1_Resp_Data 0;
BA_ "GenSigSendType" SG_ 2621833243 ISOx_SACID_1_Resp_FD_Data 3;
BA_ "GenSigFuncType" SG_ 2621833243 ISOx_SACID_1_Resp_FD_Data 9;
BA_ "GenSigSwitchedByIgnition" SG_ 2621833243 ISOx_SACID_1_Resp_FD_Data 0;
BA_ "GenSigSendType" SG_ 792 Kamera_FDD_Anz_Strassenleuchten 0;
BA_ "GenSigStartValue" SG_ 792 Kamera_FDD_Anz_Strassenleuchten 15;
BA_ "GenSigSendType" SG_ 792 Kamera_FDD_Eigenblend 0;
BA_ "GenSigSendType" SG_ 792 Kamera_FDD_Eigenblend_Guete 0;
BA_ "GenSigStartValue" SG_ 792 Kamera_FDD_Eigenblend_Guete 14;
BA_ "Fehlerwert" SG_ 792 Kamera_FDD_Eigenblend_Guete 15;
BA_ "GenSigSendType" SG_ 792 Kamera_FDD_Funktionsstatus 0;
BA_ "GenSigStartValue" SG_ 792 Kamera_FDD_Funktionsstatus 6;
BA_ "GenSigSendType" SG_ 792 Kamera_FDD_Strassenbeleuchung 0;
BA_ "GenSigSendType" SG_ 792 Kamera_FDD_Verkehrsrichtung 0;
BA_ "GenSigStartValue" SG_ 792 Kamera_FDD_Verkehrsrichtung 2;
BA_ "GenSigSendType" SG_ 792 Kamera_FSH_aktiv 0;
BA_ "GenSigSendType" SG_ 792 Kamera_Helligkeit 0;
BA_ "GenSigStartValue" SG_ 792 Kamera_Helligkeit 1022;
BA_ "Fehlerwert" SG_ 792 Kamera_Helligkeit 1023;
BA_ "GenSigSendType" SG_ 792 Kamera_Systemzustand 0;
BA_ "GenSigStartValue" SG_ 792 Kamera_Systemzustand 1;
BA_ "GenSigSendType" SG_ 792 VZE_Status_EDR 0;
BA_ "GenSigSendType" SG_ 960 BCM_Ausparken_Betrieb 3;
BA_ "GenSigSwitchedByIgnition" SG_ 960 BCM_Ausparken_Betrieb 0;
BA_ "GenSigSendType" SG_ 960 BCM_Remotestart_Betrieb 3;
BA_ "GenSigSwitchedByIgnition" SG_ 960 BCM_Remotestart_Betrieb 0;
BA_ "GenSigSendType" SG_ 960 BCM_Remotestart_KL15_Anf 3;
BA_ "GenSigSwitchedByIgnition" SG_ 960 BCM_Remotestart_KL15_Anf 0;
BA_ "GenSigSendType" SG_ 960 BCM_Remotestart_MO_Start 3;
BA_ "GenSigSwitchedByIgnition" SG_ 960 BCM_Remotestart_MO_Start 0;
BA_ "GenSigSendType" SG_ 960 Klemmen_Status_01_BZ 0;
BA_ "GenSigFuncType" SG_ 960 Klemmen_Status_01_BZ 1;
BA_ "GenSigSwitchedByIgnition" SG_ 960 Klemmen_Status_01_BZ 0;
BA_ "GenSigSendType" SG_ 960 Klemmen_Status_01_CRC 0;
BA_ "GenSigFuncType" SG_ 960 Klemmen_Status_01_CRC 2;
BA_ "GenSigSwitchedByIgnition" SG_ 960 Klemmen_Status_01_CRC 0;
BA_ "GenSigSendType" SG_ 960 KST_Fahrerhinweis_1 3;
BA_ "GenSigSwitchedByIgnition" SG_ 960 KST_Fahrerhinweis_1 0;
BA_ "GenSigSendType" SG_ 960 KST_Fahrerhinweis_2 3;
BA_ "GenSigSwitchedByIgnition" SG_ 960 KST_Fahrerhinweis_2 0;
BA_ "GenSigSendType" SG_ 960 KST_Fahrerhinweis_4 3;
BA_ "GenSigSwitchedByIgnition" SG_ 960 KST_Fahrerhinweis_4 0;
BA_ "GenSigSendType" SG_ 960 KST_Fahrerhinweis_5 3;
BA_ "GenSigSwitchedByIgnition" SG_ 960 KST_Fahrerhinweis_5 0;
BA_ "GenSigSendType" SG_ 960 KST_Fahrerhinweis_6 3;
BA_ "GenSigSwitchedByIgnition" SG_ 960 KST_Fahrerhinweis_6 0;
BA_ "GenSigSendType" SG_ 960 KST_Warn_P1_ZST_def 3;
BA_ "GenSigSwitchedByIgnition" SG_ 960 KST_Warn_P1_ZST_def 0;
BA_ "GenSigSendType" SG_ 960 KST_Warn_P2_ZST_def 3;
BA_ "GenSigSwitchedByIgnition" SG_ 960 KST_Warn_P2_ZST_def 0;
BA_ "GenSigSendType" SG_ 960 RSt_Fahrerhinweise 3;
BA_ "GenSigSwitchedByIgnition" SG_ 960 RSt_Fahrerhinweise 0;
BA_ "GenSigSendType" SG_ 960 ZAS_Kl_15 3;
BA_ "NWM-WakeupAllowed" SG_ 960 ZAS_Kl_15 1;
BA_ "GenSigFuncType" SG_ 960 ZAS_Kl_15 6;
BA_ "GenSigSwitchedByIgnition" SG_ 960 ZAS_Kl_15 0;
BA_ "GenSigSendType" SG_ 960 ZAS_Kl_50_Startanforderung 3;
BA_ "GenSigSwitchedByIgnition" SG_ 960 ZAS_Kl_50_Startanforderung 0;
BA_ "GenSigSendType" SG_ 960 ZAS_Kl_Infotainment 3;
BA_ "GenSigSwitchedByIgnition" SG_ 960 ZAS_Kl_Infotainment 0;
BA_ "GenSigSendType" SG_ 960 ZAS_Kl_S 3;
BA_ "GenSigSwitchedByIgnition" SG_ 960 ZAS_Kl_S 0;
BA_ "GenSigSendType" SG_ 960 ZAS_Kl_X 3;
BA_ "GenSigSwitchedByIgnition" SG_ 960 ZAS_Kl_X 0;
BA_ "GenSigSendType" SG_ 2463978753 Klemmen_Status_02_BZ 0;
BA_ "GenSigFuncType" SG_ 2463978753 Klemmen_Status_02_BZ 1;
BA_ "GenSigSwitchedByIgnition" SG_ 2463978753 Klemmen_Status_02_BZ 0;
BA_ "GenSigSendType" SG_ 2463978753 Klemmen_Status_02_CRC 0;
BA_ "GenSigFuncType" SG_ 2463978753 Klemmen_Status_02_CRC 2;
BA_ "GenSigSwitchedByIgnition" SG_ 2463978753 Klemmen_Status_02_CRC 0;
BA_ "GenSigSendType" SG_ 2463978753 KST_ComfortReadyStatus 4;
BA_ "GenSigSwitchedByIgnition" SG_ 2463978753 KST_ComfortReadyStatus 0;
BA_ "GenSigSendType" SG_ 2463978753 KST_Freigabe_Zustand 4;
BA_ "GenSigSwitchedByIgnition" SG_ 2463978753 KST_Freigabe_Zustand 0;
BA_ "GenSigSendType" SG_ 2463978753 KST_Sonderzustand_Anforderung 4;
BA_ "GenSigSwitchedByIgnition" SG_ 2463978753 KST_Sonderzustand_Anforderung 0;
BA_ "Fehlerwert" SG_ 2463978753 KST_Sonderzustand_Anforderung 31;
BA_ "GenSigSendType" SG_ 2463978753 KST_Sonderzustand_Status 4;
BA_ "GenSigSwitchedByIgnition" SG_ 2463978753 KST_Sonderzustand_Status 0;
BA_ "Fehlerwert" SG_ 2463978753 KST_Sonderzustand_Status 3;
BA_ "GenSigSendType" SG_ 2463978753 KST_WFS_Fahrfreigabe_Anforderung 4;
BA_ "GenSigSwitchedByIgnition" SG_ 2463978753 KST_WFS_Fahrfreigabe_Anforderung 0;
BA_ "GenSigSendType" SG_ 1646 KL_Anf_AussenspiegelHzg 3;
BA_ "GenSigSwitchedByIgnition" SG_ 1646 KL_Anf_AussenspiegelHzg 0;
BA_ "GenSigSendType" SG_ 1646 KL_BCmE_Livetip_Freigabe 3;
BA_ "GenSigSwitchedByIgnition" SG_ 1646 KL_BCmE_Livetip_Freigabe 0;
BA_ "GenSigSendType" SG_ 1646 KL_ErwVK_Anf 3;
BA_ "GenSigSwitchedByIgnition" SG_ 1646 KL_ErwVK_Anf 0;
BA_ "GenSigSendType" SG_ 1646 KL_FSH_Automatikbetrieb 3;
BA_ "GenSigSwitchedByIgnition" SG_ 1646 KL_FSH_Automatikbetrieb 0;
BA_ "GenSigSendType" SG_ 1646 KL_Geblaese_Fond_Status 0;
BA_ "GenSigStartValue" SG_ 1646 KL_Geblaese_Fond_Status 14;
BA_ "GenSigSwitchedByIgnition" SG_ 1646 KL_Geblaese_Fond_Status 0;
BA_ "Fehlerwert" SG_ 1646 KL_Geblaese_Fond_Status 15;
BA_ "GenSigSendType" SG_ 1646 KL_Geblaese_Status 0;
BA_ "GenSigStartValue" SG_ 1646 KL_Geblaese_Status 14;
BA_ "GenSigSwitchedByIgnition" SG_ 1646 KL_Geblaese_Status 0;
BA_ "Fehlerwert" SG_ 1646 KL_Geblaese_Status 15;
BA_ "GenSigSendType" SG_ 1646 KL_Heizkreisventilstellung 0;
BA_ "GenSigSwitchedByIgnition" SG_ 1646 KL_Heizkreisventilstellung 0;
BA_ "Fehlerwert" SG_ 1646 KL_Heizkreisventilstellung 3;
BA_ "GenSigSendType" SG_ 1646 KL_I_Geblaese_Fond 3;
BA_ "GenSigSwitchedByIgnition" SG_ 1646 KL_I_Geblaese_Fond 0;
BA_ "Fehlerwert" SG_ 1646 KL_I_Geblaese_Fond 255;
BA_ "GenSigSendType" SG_ 1646 KL_Innen_Temp 0;
BA_ "GenSigStartValue" SG_ 1646 KL_Innen_Temp 254;
BA_ "GenSigSwitchedByIgnition" SG_ 1646 KL_Innen_Temp 0;
BA_ "Fehlerwert" SG_ 1646 KL_Innen_Temp 255;
BA_ "GenSigSendType" SG_ 1646 KL_Kompressorkupplung 3;
BA_ "GenSigSwitchedByIgnition" SG_ 1646 KL_Kompressorkupplung 0;
BA_ "GenSigSendType" SG_ 1646 KL_Magnetventil 3;
BA_ "GenSigSwitchedByIgnition" SG_ 1646 KL_Magnetventil 0;
BA_ "GenSigSendType" SG_ 1646 KL_Restwaerme_aktiv 3;
BA_ "GenSigSwitchedByIgnition" SG_ 1646 KL_Restwaerme_aktiv 0;
BA_ "GenSigSendType" SG_ 1646 KL_SH_Soll_hl 3;
BA_ "GenSigSwitchedByIgnition" SG_ 1646 KL_SH_Soll_hl 0;
BA_ "GenSigSendType" SG_ 1646 KL_SH_Soll_hr 3;
BA_ "GenSigSwitchedByIgnition" SG_ 1646 KL_SH_Soll_hr 0;
BA_ "GenSigSendType" SG_ 1646 KL_SIH_LEH_Verteilung_VL 3;
BA_ "GenSigSwitchedByIgnition" SG_ 1646 KL_SIH_LEH_Verteilung_VL 0;
BA_ "GenSigSendType" SG_ 1646 KL_SIH_LEH_Verteilung_VR 3;
BA_ "GenSigSwitchedByIgnition" SG_ 1646 KL_SIH_LEH_Verteilung_VR 0;
BA_ "GenSigSendType" SG_ 1646 KL_SIH_LEL_Verteilung_VL 3;
BA_ "GenSigSwitchedByIgnition" SG_ 1646 KL_SIH_LEL_Verteilung_VL 0;
BA_ "GenSigSendType" SG_ 1646 KL_SIH_LEL_Verteilung_VR 3;
BA_ "GenSigSwitchedByIgnition" SG_ 1646 KL_SIH_LEL_Verteilung_VR 0;
BA_ "GenSigSendType" SG_ 1646 KL_Solarluefter_aktiv 3;
BA_ "GenSigSwitchedByIgnition" SG_ 1646 KL_Solarluefter_aktiv 0;
BA_ "GenSigSendType" SG_ 1646 KL_STH_aktiv 3;
BA_ "GenSigSwitchedByIgnition" SG_ 1646 KL_STH_aktiv 0;
BA_ "GenSigSendType" SG_ 1646 KL_STH_Ansteuerung 3;
BA_ "GenSigSwitchedByIgnition" SG_ 1646 KL_STH_Ansteuerung 0;
BA_ "GenSigSendType" SG_ 1646 KL_STH_Betriebsdauer 3;
BA_ "GenSigSwitchedByIgnition" SG_ 1646 KL_STH_Betriebsdauer 0;
BA_ "GenSigSendType" SG_ 1646 KL_STL_aktiv 3;
BA_ "GenSigSwitchedByIgnition" SG_ 1646 KL_STL_aktiv 0;
BA_ "GenSigSendType" SG_ 1646 KL_Umluft_Taste 3;
BA_ "GenSigSwitchedByIgnition" SG_ 1646 KL_Umluft_Taste 0;
BA_ "GenSigSendType" SG_ 1646 KL_WaPu 3;
BA_ "GenSigSwitchedByIgnition" SG_ 1646 KL_WaPu 0;
BA_ "GenSigSendType" SG_ 1649 KL_Betriebsmodus_FH 3;
BA_ "GenSigSwitchedByIgnition" SG_ 1649 KL_Betriebsmodus_FH 0;
BA_ "GenSigSendType" SG_ 1649 KL_ErwVK_Beifahrerzone 3;
BA_ "GenSigSwitchedByIgnition" SG_ 1649 KL_ErwVK_Beifahrerzone 0;
BA_ "GenSigSendType" SG_ 1649 KL_ErwVK_Fahrerzone 3;
BA_ "GenSigSwitchedByIgnition" SG_ 1649 KL_ErwVK_Fahrerzone 0;
BA_ "GenSigSendType" SG_ 1649 KL_ErwVK_Heckzone2_links 3;
BA_ "GenSigSwitchedByIgnition" SG_ 1649 KL_ErwVK_Heckzone2_links 0;
BA_ "GenSigSendType" SG_ 1649 KL_ErwVK_Heckzone2_rechts 3;
BA_ "GenSigSwitchedByIgnition" SG_ 1649 KL_ErwVK_Heckzone2_rechts 0;
BA_ "GenSigSendType" SG_ 1649 KL_ErwVK_Heckzone_links 3;
BA_ "GenSigSwitchedByIgnition" SG_ 1649 KL_ErwVK_Heckzone_links 0;
BA_ "GenSigSendType" SG_ 1649 Kl_ErwVK_Heckzone_rechts 3;
BA_ "GenSigSwitchedByIgnition" SG_ 1649 Kl_ErwVK_Heckzone_rechts 0;
BA_ "GenSigSendType" SG_ 1649 KL_ErwVK_Scheibenheizung 3;
BA_ "GenSigSwitchedByIgnition" SG_ 1649 KL_ErwVK_Scheibenheizung 0;
BA_ "GenSigSendType" SG_ 1649 KL_ErwVK_Status 3;
BA_ "GenSigSwitchedByIgnition" SG_ 1649 KL_ErwVK_Status 0;
BA_ "GenSigSendType" SG_ 1649 KL_Hinweis_Kuehlmodus 3;
BA_ "GenSigSwitchedByIgnition" SG_ 1649 KL_Hinweis_Kuehlmodus 0;
BA_ "GenSigSendType" SG_ 1649 KL_Meldung_Status 3;
BA_ "GenSigSwitchedByIgnition" SG_ 1649 KL_Meldung_Status 0;
BA_ "GenSigSendType" SG_ 1649 KL_STH_Betriebsdauer_lang 3;
BA_ "GenSigSwitchedByIgnition" SG_ 1649 KL_STH_Betriebsdauer_lang 0;
BA_ "GenSigSendType" SG_ 1649 KL_Stopp_Wiederstart_Anz_01 3;
BA_ "GenSigSwitchedByIgnition" SG_ 1649 KL_Stopp_Wiederstart_Anz_01 0;
BA_ "GenSigSendType" SG_ 1649 KL_Stopp_Wiederstart_Anz_02 3;
BA_ "GenSigSwitchedByIgnition" SG_ 1649 KL_Stopp_Wiederstart_Anz_02 0;
BA_ "GenSigSendType" SG_ 1649 KL_Stopp_Wiederstart_Anz_03 3;
BA_ "GenSigSwitchedByIgnition" SG_ 1649 KL_Stopp_Wiederstart_Anz_03 0;
BA_ "GenSigSendType" SG_ 1649 KL_Stopp_Wiederstart_Anz_04 3;
BA_ "GenSigSwitchedByIgnition" SG_ 1649 KL_Stopp_Wiederstart_Anz_04 0;
BA_ "GenSigSendType" SG_ 1649 KL_Stopp_Wiederstart_Anz_05 3;
BA_ "GenSigSwitchedByIgnition" SG_ 1649 KL_Stopp_Wiederstart_Anz_05 0;
BA_ "GenSigSendType" SG_ 1649 KL_Stopp_Wiederstart_Anz_06 3;
BA_ "GenSigSwitchedByIgnition" SG_ 1649 KL_Stopp_Wiederstart_Anz_06 0;
BA_ "GenSigSendType" SG_ 1649 KL_Stopp_Wiederstart_Anz_07 3;
BA_ "GenSigSwitchedByIgnition" SG_ 1649 KL_Stopp_Wiederstart_Anz_07 0;
BA_ "GenSigSendType" SG_ 1649 KL_Stopp_Wiederstart_Anz_08 3;
BA_ "GenSigSwitchedByIgnition" SG_ 1649 KL_Stopp_Wiederstart_Anz_08 0;
BA_ "GenSigSendType" SG_ 1649 KL_Stopp_Wiederstart_Anz_09 3;
BA_ "GenSigSwitchedByIgnition" SG_ 1649 KL_Stopp_Wiederstart_Anz_09 0;
BA_ "GenSigSendType" SG_ 1649 KL_Stopp_Wiederstart_Anz_Std1 3;
BA_ "GenSigSwitchedByIgnition" SG_ 1649 KL_Stopp_Wiederstart_Anz_Std1 0;
BA_ "GenSigSendType" SG_ 1649 KL_Stopp_Wiederstart_Anz_Std2 3;
BA_ "GenSigSwitchedByIgnition" SG_ 1649 KL_Stopp_Wiederstart_Anz_Std2 0;
BA_ "GenSigSendType" SG_ 1649 KL_ZZ_Betriebsmodus 3;
BA_ "GenSigSwitchedByIgnition" SG_ 1649 KL_ZZ_Betriebsmodus 0;
BA_ "GenSigSendType" SG_ 1649 KL_ZZ_Minute 3;
BA_ "GenSigSwitchedByIgnition" SG_ 1649 KL_ZZ_Minute 0;
BA_ "GenSigSendType" SG_ 1649 KL_ZZ_Monat 3;
BA_ "GenSigSwitchedByIgnition" SG_ 1649 KL_ZZ_Monat 0;
BA_ "GenSigSendType" SG_ 1649 KL_ZZ_Status_Timer 3;
BA_ "GenSigSwitchedByIgnition" SG_ 1649 KL_ZZ_Status_Timer 0;
BA_ "GenSigSendType" SG_ 1649 KL_ZZ_Stunde 3;
BA_ "GenSigSwitchedByIgnition" SG_ 1649 KL_ZZ_Stunde 0;
BA_ "GenSigSendType" SG_ 1649 KL_ZZ_Tag 3;
BA_ "GenSigSwitchedByIgnition" SG_ 1649 KL_ZZ_Tag 0;
BA_ "GenSigSendType" SG_ 949 KL_AC_Schalter 0;
BA_ "GenSigSwitchedByIgnition" SG_ 949 KL_AC_Schalter 0;
BA_ "GenSigSendType" SG_ 949 KL_AirCleaner_aktiv 0;
BA_ "GenSigSwitchedByIgnition" SG_ 949 KL_AirCleaner_aktiv 0;
BA_ "GenSigSendType" SG_ 949 KL_Anf_KL 0;
BA_ "GenSigSwitchedByIgnition" SG_ 949 KL_Anf_KL 0;
BA_ "Fehlerwert" SG_ 949 KL_Anf_KL 255;
BA_ "GenSigSendType" SG_ 949 KL_Anf_KV 0;
BA_ "GenSigStartValue" SG_ 949 KL_Anf_KV 126;
BA_ "GenSigSwitchedByIgnition" SG_ 949 KL_Anf_KV 0;
BA_ "GenSigSendType" SG_ 949 KL_Ausstattung_Klima 0;
BA_ "GenSigSwitchedByIgnition" SG_ 949 KL_Ausstattung_Klima 0;
BA_ "GenSigSendType" SG_ 949 KL_Charisma_FahrPr 0;
BA_ "GenSigSwitchedByIgnition" SG_ 949 KL_Charisma_FahrPr 0;
BA_ "GenSigSendType" SG_ 949 KL_Charisma_Status 0;
BA_ "GenSigSwitchedByIgnition" SG_ 949 KL_Charisma_Status 0;
BA_ "GenSigSendType" SG_ 949 KL_Drehz_Anh 0;
BA_ "GenSigSwitchedByIgnition" SG_ 949 KL_Drehz_Anh 0;
BA_ "GenSigSendType" SG_ 949 KL_el_Zuheizer_Stufe 0;
BA_ "GenSigSwitchedByIgnition" SG_ 949 KL_el_Zuheizer_Stufe 0;
BA_ "GenSigSendType" SG_ 949 KL_Freilauf_Info 0;
BA_ "GenSigSwitchedByIgnition" SG_ 949 KL_Freilauf_Info 0;
BA_ "GenSigSendType" SG_ 949 KL_Komp_Moment_alt 0;
BA_ "GenSigFuncType" SG_ 949 KL_Komp_Moment_alt 5;
BA_ "GenSigSwitchedByIgnition" SG_ 949 KL_Komp_Moment_alt 0;
BA_ "GenSigSendType" SG_ 949 KL_Kompressorkupplung_linear 0;
BA_ "GenSigStartValue" SG_ 949 KL_Kompressorkupplung_linear 254;
BA_ "GenSigSwitchedByIgnition" SG_ 949 KL_Kompressorkupplung_linear 0;
BA_ "GenSigSendType" SG_ 949 KL_Last_Kompr 0;
BA_ "GenSigSwitchedByIgnition" SG_ 949 KL_Last_Kompr 0;
BA_ "Fehlerwert" SG_ 949 KL_Last_Kompr 255;
BA_ "GenSigSendType" SG_ 949 KL_nachtr_Stopp_Anf 0;
BA_ "GenSigSwitchedByIgnition" SG_ 949 KL_nachtr_Stopp_Anf 0;
BA_ "GenSigSendType" SG_ 949 KL_Spannungs_Anf 0;
BA_ "GenSigSwitchedByIgnition" SG_ 949 KL_Spannungs_Anf 0;
BA_ "GenSigSendType" SG_ 949 KL_StartStopp_Info 0;
BA_ "GenSigSwitchedByIgnition" SG_ 949 KL_StartStopp_Info 0;
BA_ "GenSigSendType" SG_ 949 KL_T_Charge 0;
BA_ "GenSigSwitchedByIgnition" SG_ 949 KL_T_Charge 0;
BA_ "GenSigSendType" SG_ 949 KL_Thermomanagement 0;
BA_ "GenSigSwitchedByIgnition" SG_ 949 KL_Thermomanagement 0;
BA_ "GenSigSendType" SG_ 949 KL_Variante_Standheizung 0;
BA_ "GenSigSwitchedByIgnition" SG_ 949 KL_Variante_Standheizung 0;
BA_ "GenSigSendType" SG_ 949 KL_Vorwarn_Komp_ein 0;
BA_ "GenSigSwitchedByIgnition" SG_ 949 KL_Vorwarn_Komp_ein 0;
BA_ "GenSigSendType" SG_ 949 KL_Vorwarn_Zuheizer_ein 0;
BA_ "GenSigSwitchedByIgnition" SG_ 949 KL_Vorwarn_Zuheizer_ein 0;
BA_ "GenSigSendType" SG_ 949 KL_Zustand 0;
BA_ "GenSigSwitchedByIgnition" SG_ 949 KL_Zustand 0;
BA_REL_ "GenSigTimeoutTime" BU_SG_REL_ BMS_NV_12V SG_ 960 ZAS_Kl_15 1000;
BA_REL_ "GenSigTimeoutTime" BU_SG_REL_ Gateway_Max SG_ 2589283690 HVLE_Temperatur 5000;
BA_REL_ "GenSigTimeoutTime" BU_SG_REL_ Gateway_Max SG_ 2463978775 HVLX_Isond_maxAcEigenstromL1 500;
BA_REL_ "GenSigTimeoutTime" BU_SG_REL_ Gateway_Max SG_ 2463978775 HVLX_Isond_maxAcEigenstromL2 500;
BA_REL_ "GenSigTimeoutTime" BU_SG_REL_ Gateway_Max SG_ 2463978775 HVLX_Isond_maxAcEigenstromL3 500;
BA_REL_ "GenSigTimeoutTime" BU_SG_REL_ Gateway_Max SG_ 2463978775 HVLX_Isond_maxAcAbgabestromL1 500;
BA_REL_ "GenSigTimeoutTime" BU_SG_REL_ Gateway_Max SG_ 2463978775 HVLX_Isond_maxAcAbgabestromL2 500;
BA_REL_ "GenSigTimeoutTime" BU_SG_REL_ Gateway_Max SG_ 2463978775 HVLX_Isond_maxAcAbgabestromL3 500;
BA_REL_ "GenSigTimeoutTime" BU_SG_REL_ Gateway_Max SG_ 2463978775 HVLX_Isond_MaxStromACLsPlc 500;
BA_REL_ "GenSigTimeoutTime" BU_SG_REL_ Gateway_Max SG_ 2463978775 HVLX_Isond_maxStromLadesaeule 500;
BA_REL_ "GenSigTimeoutTime" BU_SG_REL_ Gateway_Max SG_ 2463978775 HVLX_Isond_minStromLadesaeule 500;
BA_REL_ "GenSigTimeoutTime" BU_SG_REL_ Gateway_Max SG_ 2463978775 HVLX_Isond_maxSpannungLadesaeule 500;
BA_REL_ "GenSigTimeoutTime" BU_SG_REL_ Gateway_Max SG_ 2463978775 HVLX_Isond_minSpannungLadesaeule 500;
BA_REL_ "GenSigTimeoutTime" BU_SG_REL_ Gateway_Max SG_ 2463978775 HVLX_Isond_IstSpannungLadesaeule 500;
BA_REL_ "GenSigTimeoutTime" BU_SG_REL_ Gateway_Max SG_ 2463978775 HVLX_Isond_IstStromLadesaeule 500;
BA_REL_ "GenSigTimeoutTime" BU_SG_REL_ Gateway_Max SG_ 2463978775 HVLX_Isond_StromrippelPeakLs 500;
BA_REL_ "GenSigTimeoutTime" BU_SG_REL_ Gateway_Max SG_ 2463978775 HVLX_Isond_IstSpannungACLsPlc 500;
BA_REL_ "GenSigTimeoutTime" BU_SG_REL_ Gateway_Max SG_ 2463978775 HVLX_Isond_maxLeistungLadesaeule 500;
BA_REL_ "GenSigTimeoutTime" BU_SG_REL_ Gateway_Max SG_ 2463978775 HVLX_Isond_maxStromErreicht 500;
BA_REL_ "GenSigTimeoutTime" BU_SG_REL_ Gateway_Max SG_ 2463978775 HVLX_Isond_maxSpannungErreicht 500;
BA_REL_ "GenSigTimeoutTime" BU_SG_REL_ Gateway_Max SG_ 2463978775 HVLX_Isond_maxLeistungErreicht 500;
BA_REL_ "GenSigTimeoutTime" BU_SG_REL_ Gateway_Max SG_ 2463978775 HVLX_Isond_NormLsPlc 500;
BA_REL_ "GenSigTimeoutTime" BU_SG_REL_ Gateway_Max SG_ 2463978775 HVLX_Isond_TLS_PnC_Status 500;
BA_REL_ "GenSigTimeoutTime" BU_SG_REL_ Gateway_Max SG_ 2463978775 HVLX_Isond_ResponseCodeLsPlc 500;
BA_REL_ "GenSigTimeoutTime" BU_SG_REL_ Gateway_Max SG_ 2463978775 HVLX_Isond_IsoStatusLadesaeule 500;
BA_REL_ "GenSigTimeoutTime" BU_SG_REL_ Gateway_Max SG_ 2463978775 HVLX_Isond_PlcKommFehler 500;
BA_REL_ "GenSigTimeoutTime" BU_SG_REL_ Gateway_Max SG_ 2463978775 HVLX_Isond_LadeartAC1PCorePlc 500;
BA_REL_ "GenSigTimeoutTime" BU_SG_REL_ Gateway_Max SG_ 2463978775 HVLX_Isond_LadeartAC3PCorePlc 500;
BA_REL_ "GenSigTimeoutTime" BU_SG_REL_ Gateway_Max SG_ 2463978775 HVLX_Isond_LadeartDCComboCorePlc 500;
BA_REL_ "GenSigTimeoutTime" BU_SG_REL_ Gateway_Max SG_ 2463978775 HVLX_Isond_LadeartDCCorePlc 500;
BA_REL_ "GenSigTimeoutTime" BU_SG_REL_ Gateway_Max SG_ 2463978775 HVLX_Isond_LadeartDCExtendedPlc 500;
BA_REL_ "GenSigTimeoutTime" BU_SG_REL_ Gateway_Max SG_ 2463978775 HVLX_Isond_LadeartDCUniquePlc 500;
BA_REL_ "GenSigTimeoutTime" BU_SG_REL_ Gateway_Max SG_ 2463978775 HVLX_Isond_ZahlungsmethodeLs 500;
BA_REL_ "GenSigTimeoutTime" BU_SG_REL_ Gateway_Max SG_ 2463978775 HVLX_Isond_StatusRcdACLsPlc 500;
BA_REL_ "GenSigTimeoutTime" BU_SG_REL_ Gateway_Max SG_ 2463978775 HVLX_Isond_ZahlererfassungAnfHlc 500;
BA_REL_ "GenSigTimeoutTime" BU_SG_REL_ Gateway_Max SG_ 2463978775 HVLX_Isond_PLC_Message_Status 500;
BA_REL_ "GenSigTimeoutTime" BU_SG_REL_ Gateway_Max SG_ 2463978775 HVLX_Isond_PnCZertifkatErhaltHlc 500;
BA_REL_ "GenSigTimeoutTime" BU_SG_REL_ Gateway_Max SG_ 2463978775 HVLX_Isond_LadeplanErhaltenHlc 500;
BA_REL_ "GenSigTimeoutTime" BU_SG_REL_ Gateway_Max SG_ 2463978775 HVLX_Isond_SASTupelErhaltenHlc 500;
BA_REL_ "GenSigTimeoutTime" BU_SG_REL_ Gateway_Max SG_ 2463978775 HVLX_Isond_StatusLadesaeule 500;
BA_REL_ "GenSigTimeoutTime" BU_SG_REL_ Gateway_Max SG_ 2463978775 HVLX_Isond_EigenstromLadenStatus 500;
BA_REL_ "GenSigTimeoutTime" BU_SG_REL_ Gateway_Max SG_ 2463978775 HVLX_Isond_EVSEProcessing_Status 500;
BA_REL_ "GenSigTimeoutTime" BU_SG_REL_ Gateway_Max SG_ 2463978775 HVLX_Isond_VASBedAnzStatus_LsPlc 500;
BA_REL_ "GenSigTimeoutTime" BU_SG_REL_ Gateway_Max SG_ 2463978775 HVLX_Isond_VASErwLFStatus_LsPlc 500;
BA_REL_ "GenSigTimeoutTime" BU_SG_REL_ Gateway_Max SG_ 2463978775 HVLX_LSPLC_01_Sendestatus 500;
BA_REL_ "GenSigTimeoutTime" BU_SG_REL_ Gateway_Max SG_ 2463978775 HVLX_PlcFehlerstatus 500;
BA_REL_ "GenSigTimeoutTime" BU_SG_REL_ Gateway_Max SG_ 2463978775 HVLX_PlcGefundeneLadesaeule 500;
BA_REL_ "GenSigTimeoutTime" BU_SG_REL_ Gateway_Max SG_ 2463978775 HVLX_PlcLinkStatus 500;
BA_REL_ "GenSigTimeoutTime" BU_SG_REL_ Gateway_Max SG_ 2463978775 HVLX_Isond_LsNotification_Plc 500;
BA_REL_ "GenSigTimeoutTime" BU_SG_REL_ Gateway_Max SG_ 2463978775 HVLX_Isond_TlsZertifkatErhaltHlc 500;
BA_REL_ "GenSigTimeoutTime" BU_SG_REL_ Gateway_Max SG_ 2463978775 HVLX_Isond_VasResponse 500;
BA_REL_ "GenSigTimeoutTime" BU_SG_REL_ Gateway_Max SG_ 1646 KL_STH_Betriebsdauer 5000;
BA_REL_ "GenSigTimeoutTime" BU_SG_REL_ Gateway_Max SG_ 1646 KL_SH_Soll_hl 5000;
BA_REL_ "GenSigTimeoutTime" BU_SG_REL_ Gateway_Max SG_ 1646 KL_SH_Soll_hr 5000;
BA_REL_ "GenSigTimeoutTime" BU_SG_REL_ Gateway_Max SG_ 1646 KL_ErwVK_Anf 5000;
BA_REL_ "GenSigTimeoutTime" BU_SG_REL_ Gateway_Max SG_ 1646 KL_I_Geblaese_Fond 5000;
BA_REL_ "GenSigTimeoutTime" BU_SG_REL_ Gateway_Max SG_ 1649 KL_ErwVK_Scheibenheizung 5000;
BA_REL_ "GenSigTimeoutTime" BU_SG_REL_ Gateway_Max SG_ 1649 KL_ErwVK_Heckzone2_links 5000;
BA_REL_ "GenSigTimeoutTime" BU_SG_REL_ Gateway_Max SG_ 1649 KL_ErwVK_Heckzone2_rechts 5000;
BA_REL_ "GenSigTimeoutTime" BU_SG_REL_ Gateway_Max SG_ 1649 KL_ErwVK_Status 5000;
BA_REL_ "GenSigTimeoutTime" BU_SG_REL_ Gateway_Max SG_ 1649 KL_ErwVK_Beifahrerzone 5000;
BA_REL_ "GenSigTimeoutTime" BU_SG_REL_ Gateway_Max SG_ 1649 KL_ErwVK_Fahrerzone 5000;
BA_REL_ "GenSigTimeoutTime" BU_SG_REL_ Gateway_Max SG_ 1649 KL_ErwVK_Heckzone_links 5000;
BA_REL_ "GenSigTimeoutTime" BU_SG_REL_ Gateway_Max SG_ 1649 Kl_ErwVK_Heckzone_rechts 5000;
BA_REL_ "GenSigTimeoutTime" BU_SG_REL_ Gateway_Max SG_ 949 KL_AC_Schalter 1000;
BA_REL_ "GenSigTimeoutTime" BU_SG_REL_ Gateway_Max SG_ 949 KL_Zustand 1000;
BA_REL_ "GenSigTimeoutTime" BU_SG_REL_ Gateway_Max SG_ 949 KL_Spannungs_Anf 1000;
BA_REL_ "GenSigTimeoutTime" BU_SG_REL_ Gateway_Max SG_ 949 KL_StartStopp_Info 1000;
BA_REL_ "GenSigTimeoutTime" BU_SG_REL_ Gateway_Max SG_ 949 KL_Anf_KL 1000;
BA_REL_ "GenSigTimeoutTime" BU_SG_REL_ Gateway_Max SG_ 949 KL_el_Zuheizer_Stufe 1000;
BA_REL_ "GenSigTimeoutTime" BU_SG_REL_ Gateway_Max SG_ 949 KL_Ausstattung_Klima 1000;
BA_REL_ "GenSigTimeoutTime" BU_SG_REL_ Gateway_Max SG_ 949 KL_Variante_Standheizung 1000;
BA_REL_ "GenSigTimeoutTime" BU_SG_REL_ Gateway_Max SG_ 949 KL_AirCleaner_aktiv 1000;
BA_REL_ "GenSigTimeoutTime" BU_SG_REL_ Klima SG_ 792 Kamera_FSH_aktiv 800;
BA_REL_ "GenSigTimeoutTime" BU_SG_REL_ Klima SG_ 2463978753 KST_Sonderzustand_Status 5000;
BA_REL_ "GenSigTimeoutTime" BU_SG_REL_ Klima SG_ 2463978753 KST_Sonderzustand_Anforderung 5000;
BA_REL_ "GenSigTimeoutTime" BU_SG_REL_ Klima SG_ 960 ZAS_Kl_S 1000;
BA_REL_ "GenSigTimeoutTime" BU_SG_REL_ Klima SG_ 960 ZAS_Kl_15 1000;
BA_REL_ "GenSigTimeoutTime" BU_SG_REL_ Klima SG_ 960 BCM_Remotestart_Betrieb 1000;
BA_REL_ "GenSigTimeoutTime" BU_SG_REL_ Klima SG_ 960 KST_Fahrerhinweis_1 1000;
BA_REL_ "GenSigTimeoutTime" BU_SG_REL_ Klima SG_ 960 KST_Fahrerhinweis_2 1000;
BA_REL_ "GenSigTimeoutTime" BU_SG_REL_ Klima SG_ 960 KST_Fahrerhinweis_5 1000;
BA_REL_ "GenSigTimeoutTime" BU_SG_REL_ Klima SG_ 960 KST_Fahrerhinweis_6 1000;
VAL_ 2463978703 HVLM_GBT_01_Sendestatus 0 "langsamer_Zyklus" 1 "schneller_Zyklus" ;
VAL_ 2463978703 HVLM_GBT_Status_Control 0 "nicht_zuruecksetzen" 1 "zuruecksetzen" ;
VAL_ 2463978703 HVLM_GBT_SendeAnf_BCL 0 "nicht_senden" 1 "senden" ;
VAL_ 2463978703 HVLM_GBT_SendeAnf_BCP 0 "nicht_senden" 1 "senden" ;
VAL_ 2463978703 HVLM_GBT_SendeAnf_BCS 0 "nicht_senden" 1 "senden" ;
VAL_ 2463978703 HVLM_GBT_SendeAnf_BEM 0 "nicht_senden" 1 "senden" ;
VAL_ 2463978703 HVLM_GBT_SendeAnf_BHM 0 "nicht_senden" 1 "senden" ;
VAL_ 2463978703 HVLM_GBT_SendeAnf_BRM 0 "nicht_senden" 1 "senden" ;
VAL_ 2463978703 HVLM_GBT_SendeAnf_BRO 0 "nicht_senden" 1 "senden" ;
VAL_ 2463978703 HVLM_GBT_SendeAnf_BSD 0 "nicht_senden" 1 "senden" ;
VAL_ 2463978703 HVLM_GBT_SendeAnf_BSM 0 "nicht_senden" 1 "senden" ;
VAL_ 2463978703 HVLM_GBT_SendeAnf_BST 0 "nicht_senden" 1 "senden" ;
VAL_ 2463978703 HVLM_GBT_HvBatt_MaxLadespannung 16382 "Init" 16383 "Fehler" ;
VAL_ 2463978703 HVLM_GBT_BEM_Timeout_CCS 0 "normal" 1 "Timeout_CCS_erkannt" 2 "unplausibel" ;
VAL_ 2463978703 HVLM_GBT_BEM_Timeout_CML 0 "normal" 1 "Timeout_CML_erkannt" 2 "unplausibel" ;
VAL_ 2463978703 HVLM_GBT_BEM_Timeout_CRMnReady 0 "normal" 1 "Timeout_CRM_nicht_bereit_erkannt" 2 "unplausibel" ;
VAL_ 2463978703 HVLM_GBT_BEM_Timeout_CRMReady 0 "normal" 1 "Timeout_CRM_LS_bereit_erkannt" 2 "unplausibel" ;
VAL_ 2463978703 HVLM_GBT_BEM_Timeout_CRO 0 "normal" 1 "Timeout_CRO_erkannt" 2 "unplausibel" ;
VAL_ 2463978703 HVLM_GBT_BEM_Timeout_CSD 0 "normal" 1 "Timeout_CSD_erkannt" 2 "unplausibel" ;
VAL_ 2463978703 HVLM_GBT_BEM_Timeout_CST 0 "normal" 1 "Timeout_CST_erkannt" 2 "unplausibel" ;
VAL_ 2463978703 HVLM_GBT_BCL_Sollspannung 16382 "Init" 16383 "Fehler" ;
VAL_ 2463978703 HVLM_GBT_BCL_Ladeverfahren 0 "Init" 1 "Laden_mit_konstanter_Spannung" 2 "Laden_mit_konstantem_Strom" 3 "Fehler" ;
VAL_ 2463978703 HVLM_GBT_BCL_Sollstrom 16382 "Init" 16383 "Fehler" ;
VAL_ 2463978703 HVLM_GBT_BCP_StartSOC 1022 "Init" 1023 "Fehler" ;
VAL_ 2463978703 HVLM_GBT_BCP_Ist_Spannung_HvBatt 16382 "Init" 16383 "Fehler" ;
VAL_ 2463978703 HVLM_GBT_BCP_MaxLadestrom_Fzg 16382 "Init" 16383 "Fehler" ;
VAL_ 2463978703 HVLM_GBT_BCP_MaxZellladespannung 4094 "Init" 4095 "Fehler" ;
VAL_ 2463978703 HVLM_GBT_BCP_MaxTemperatur 254 "Init" 255 "Fehler" ;
VAL_ 2463978703 HVLM_GBT_BCP_Nennenergiegehalt 16382 "Init" 16383 "Fehler" ;
VAL_ 2463978703 HVLM_GBT_BCS_Ist_Restladezeit 1022 "Init" 1023 "Fehler" ;
VAL_ 2463978703 HVLM_GBT_BCS_Ist_Ladespannung 16382 "Init" 16383 "Fehler" ;
VAL_ 2463978703 HVLM_GBT_BCS_Ist_Ladestrom 16382 "Init" 16383 "Fehler" ;
VAL_ 2463978703 HVLM_GBT_BCS_IstSOC 126 "Init" 127 "Fehler" ;
VAL_ 2463978703 HVLM_GBT_BCS_GruppenNr_Uzellmax 30 "Init" 31 "Fehler" ;
VAL_ 2463978703 HVLM_GBT_BCS_Ist_MaxZellspannung 4094 "Init" 4095 "Fehler" ;
VAL_ 2463978703 HVLM_GBT_BRM_Nennkapazitaet 4094 "init" 4095 "Fehler" ;
VAL_ 2463978703 HVLM_GBT_BRM_Batterietyp 0 "Init" 1 "Blei" 2 "NiMh" 3 "Li_Ionen_Fe_Phosphat" 4 "Li_Ionen_MnO" 5 "Li_Ionen_Cobalt" 6 "Temary_composite" 7 "Li_Ionen_Polymer" 8 "Li_Ionen_Titanate" 255 "sonstige" ;
VAL_ 2463978703 HVLM_GBT_BRM_Nennspannung_HvBatt 16382 "Init" 16383 "Fehler" ;
VAL_ 2463978703 HVLM_GBT_BRO_FzgBereitschaft 0 "Fahrzeug_nicht_bereit" 170 "Fahrzeug_bereit" 255 "Fehler" ;
VAL_ 2463978703 HVLM_GBT_BSD_EndSOC 126 "Init" 127 "Fehler" ;
VAL_ 2463978703 HVLM_GBT_BSM_FzgLadeerlaubnis 0 "Laden_verboten" 1 "Laden_erlaubt" ;
VAL_ 2463978703 HVLM_GBT_BSD_MaxTemperatur 254 "Init" 255 "Fehler" ;
VAL_ 2463978703 HVLM_GBT_BSD_MinTemperatur 254 "Init" 255 "Fehler" ;
VAL_ 2463978703 HVLM_GBT_BSD_MaxZellspannung 4094 "Init" 4095 "Fehler" ;
VAL_ 2463978703 HVLM_GBT_BSD_MinZellspannung 4094 "Init" 4095 "Fehler" ;
VAL_ 2463978703 HVLM_GBT_BSM_Ist_MaxTemperatur 254 "Init" 255 "Fehler" ;
VAL_ 2463978703 HVLM_GBT_BSM_Ist_MinTemperatur 254 "Init" 255 "Fehler" ;
VAL_ 2463978703 HVLM_GBT_BSM_Status_Iso 0 "normal" 1 "abnormal" 2 "unplausibel" ;
VAL_ 2463978703 HVLM_GBT_BSM_Status_SOC 0 "normal" 1 "SOC_zu_hoch" 2 "SOC_zu_niedrig" ;
VAL_ 2463978703 HVLM_GBT_BSM_Status_Stecker 0 "normal" 1 "abnormal" 2 "unplausibel" ;
VAL_ 2463978703 HVLM_GBT_BSM_Status_Strom 0 "normal" 1 "Stromueberschreitung" 2 "unplausibel" ;
VAL_ 2463978703 HVLM_GBT_BSM_Status_Temperatur 0 "normal" 1 "Uebertemperatur" 2 "unplausibel" ;
VAL_ 2463978703 HVLM_GBT_BSM_Status_Zellspannung 0 "normal" 1 "Zellspannung_zu_hoch" 2 "Zellspannung_zu_niedrig" ;
VAL_ 2463978703 HVLM_GBT_BST_Ladeende_Fehler_I 0 "Strom_normal" 1 "Ladestrom_stimmt_nicht_ueberein" 2 "unplausibel" ;
VAL_ 2463978703 HVLM_GBT_BST_Ladeende_Fehler_U 0 "normale_Spannung" 1 "abnormale_Spannung" 2 "unplausibel" ;
VAL_ 2463978703 HVLM_GBT_BST_Ladeende_Fehler1 0 "normal" 1 "Isolationsfehler" 2 "unplausibel" ;
VAL_ 2463978703 HVLM_GBT_BST_Ladeende_Fehler2 0 "normal" 1 "Uebertemperatur" 2 "unplausibel" ;
VAL_ 2463978703 HVLM_GBT_BST_Ladeende_Fehler3 0 "normal" 1 "Uebertemperatur" 2 "unplausibel" ;
VAL_ 2463978703 HVLM_GBT_BST_Ladeende_Fehler4 0 "normal" 1 "Fehler_Ladestecker" 2 "unplausibel" ;
VAL_ 2463978703 HVLM_GBT_BST_Ladeende_Fehler5 0 "normal" 1 "Ueberemperatur_einer_Baugruppe" 2 "unplausibel" ;
VAL_ 2463978703 HVLM_GBT_BST_Ladeende_Fehler6 0 "normal" 1 "HV_Schuetze_Fehler" 2 "unplausibel" ;
VAL_ 2463978703 HVLM_GBT_BST_Ladeende_Fehler7 0 "normal" 1 "Spannungsfehler_CC2" 2 "unplausibel" ;
VAL_ 2463978703 HVLM_GBT_BST_Ladeende_Fehler8 0 "normal" 1 "andere_Fehler" 2 "unplausibel" ;
VAL_ 2463978703 HVLM_GBT_BST_Ladeende1_Fahrzeug 0 "ZielSOC_nicht_erreicht" 1 "ZielSOC_erreicht" 2 "unplausibel" ;
VAL_ 2463978703 HVLM_GBT_BST_Ladeende2_Fahrzeug 0 "Zielspannnung_nicht_erreicht" 1 "Zielspannung_erreicht" 2 "unplausibel" ;
VAL_ 2463978703 HVLM_GBT_BST_Ladeende3_Fahrzeug 0 "Zielzellspannung_nicht_ereicht" 1 "Zielzellspannung_erreicht" 2 "unplausibel" ;
VAL_ 2463978703 HVLM_GBT_BST_Ladeende4_Fahrzeug 0 "normal" 1 "CST_Nachricht_erhalten" 2 "unplausibel" ;
VAL_ 2463978707 HVLM_PlcModemAktivieren 0 "PLC_Modem_nicht_aktivieren" 1 "PLC_Modem_aktivieren" ;
VAL_ 2463978707 HVLM_ZahlungsmethodeFzgPlc 0 "Vertrag" 1 "externe_Bezahlung" ;
VAL_ 2463978707 HVLM_maxLadestromFzgPlc 8190 "Init" 8191 "Fehler" ;
VAL_ 2463978707 HVLM_TLS_PnC_Authenfizierung 0 "Init" 1 "TLS_nicht_verwenden" 2 "TLS_ohne_PnC_verwenden" 3 "PnC_privat_verwenden" 4 "PnC_privat_oeffentlich_verwenden" ;
VAL_ 2463978707 HVLM_SollstromFzgPlc_2 16382 "Init" 16383 "Fehler" ;
VAL_ 2463978707 HVLM_PlcKommLadedose 0 "Anf_IsoKomm_LdA" 1 "Anf_IsoKomm_LdB" 2 "Init" ;
VAL_ 2463978707 HVLM_ZielladespannungFzgPlc 16382 "Init" 16383 "Fehler" ;
VAL_ 2463978707 HVLM_PlcAnforderung 0 "PLC_nicht_aktivieren" 1 "PLC_aktivieren" 2 "PLC_pausieren" 3 "Init" ;
VAL_ 2463978707 HVLM_LadezustandHvBatFzgPlc 126 "Init" 127 "Fehler" ;
VAL_ 2463978707 HVLM_LadebereitFzgPlc 0 "nicht_ladebereit" 1 "ladebereit" ;
VAL_ 2463978707 HVLM_maxLadespannungFzgPlc 16382 "Init" 16383 "Fehler" ;
VAL_ 2463978707 HVLM_LadeartAnfFzgPlc 0 "AC_single_phase_core" 1 "AC_three_phase_core" 2 "DC_core" 3 "DC_extended" 4 "DC_combo_core" 5 "DC_unique" 6 "keine_Anforderung" 7 "Init" ;
VAL_ 2463978707 HVLM_MsgTriggerFzgPlc 0 "keine_Anforderung" 1 "TCPIPConnection_Anforderung" 2 "SDP_Anforderung" 3 "SupportedAppProtocol" 4 "SessionSetup" 5 "ServiceDiscovery" 6 "ServicePaymentServiceSelectionRe" 7 "ContractAuthentication" 8 "ChargeParameterDiscovery" 9 "CableCheck" 10 "PreCharge" 11 "PowerDelivery" 12 "CurrentDemand" 13 "WeldingDetection" 14 "SessionStop" 15 "StopCommunicationSession" 16 "FinePositioningSetup" 17 "FinePositioning" 18 "Pairing" 19 "Authorization" 20 "AlignmentCheck" 21 "PowerDemand" 22 "AuthorizationSetup" 23 "DC_ChargeLoop" 51 "ServiceDetailsAnforderung" 53 "ServiceSelection" 54 "IdentificationDetails" 61 "Certificate_Update" 62 "Certificate_Installation" 63 "Payment_Details" 121 "ChargingStatus" 122 "Metering_Receipt" ;
VAL_ 2463978707 HVLM_FehlerFzgPlc 0 "NO_ERROR" 1 "FAILED_RESSTemperatureInhibit" 2 "FAILED_PEVShiftPosition" 3 "FAILED_ChargerConnectorLockFault" 4 "FAILED_PEVRESSMalfunction" 5 "FAILED_ChargingCurrentdifferenti" 6 "FAILED_ChargingVoltageOutOfRange" 7 "Reserved_A" 8 "Reserved_B" 9 "Reserved_C" 10 "FAILED_ChargingSystemIncompatibi" 11 "NoData" 14 "Init" 15 "Fehler" ;
VAL_ 2463978707 HVLM_ReadyToChargeState 0 "keine_Anforderung" 1 "Ladevorgang_Stoppen" 2 "Ladevorgang_Starten" 3 "Ladevorgang_Neuaushandeln" ;
VAL_ 2463978707 HVLM_LadenAbgeschlPlc 0 "kein_Status" 1 "nicht_erreicht" 2 "Wunschladezustand_erreicht" ;
VAL_ 2463978707 HVLM_LadeSessionPlc 0 "Start" 1 "Fortsetzen" 2 "Beenden" 3 "Pausieren" ;
VAL_ 2463978707 HVLM_minLadestromFzgPlc 1022 "Init" 1023 "Fehler" ;
VAL_ 2463978707 HVLM_NormFzgPlc 0 "ISO15118_2016" 1 "DIN70121_2014" 2 "ISO15118_2016_v2" 3 "ISO15118_20_v1" 7 "keine_Anforderung" ;
VAL_ 2463978707 HVLM_AnforderungPLTabellen 0 "Keine_Anforderung_PLTabellen" 1 "Anforderung_PLTabellen" ;
VAL_ 2463978707 HVLM_maxLadestromFzgPlc_2 16382 "Init" 16383 "Fehler" ;
VAL_ 2589283690 LAD_OBD_Lampe_Anf 1 "MIL_Request" ;
VAL_ 2589283690 IPB_ThermAuslastungsgrad 101 "Notkuehlung" 254 "Init" 255 "Fehler" ;
VAL_ 2589283690 TNV_Temperatur 254 "Init" 255 "Fehler" ;
VAL_ 2589283690 IPB_Wasser_TEMP_EIN 254 "Init" 255 "Fehler" ;
VAL_ 2589283690 IPB_Wasser_TEMP_AUS 254 "Init" 255 "Fehler" ;
VAL_ 2589283690 HVLE_Temperatur 254 "Init" 255 "Fehler" ;
VAL_ 2589283690 HVLE_ThermAuslastungsgrad 101 "Notkuehlung" 254 "InitWert" 255 "Fehler" ;
VAL_ 2589283690 HVLE_eTM_max_Vorlauftemperatur 254 "Init" 255 "Fehler" ;
VAL_ 2589283690 OBDProtocol_Ladegeraet 0 "OBDonUDS" 1 "OBDclassic" 16 "NoOBD" 254 "Init" 255 "Fehler" ;
VAL_ 2463978775 HVLX_Isond_maxAcEigenstromL1 1021 "keine_Angabe" 1022 "Init" 1023 "Fehler" ;
VAL_ 2463978775 HVLX_Isond_maxAcEigenstromL2 1021 "keine_Angabe" 1022 "Init" 1023 "Fehler" ;
VAL_ 2463978775 HVLX_Isond_maxAcEigenstromL3 1021 "keine_Angabe" 1022 "Init" 1023 "Fehler" ;
VAL_ 2463978775 HVLX_Isond_maxAcAbgabestromL1 1021 "keine_Angabe" 1022 "Init" 1023 "Fehler" ;
VAL_ 2463978775 HVLX_Isond_maxAcAbgabestromL2 1021 "keine_Angabe" 1022 "Init" 1023 "Fehler" ;
VAL_ 2463978775 HVLX_Isond_maxAcAbgabestromL3 1021 "keine_Angabe" 1022 "Init" 1023 "Fehler" ;
VAL_ 2463978775 HVLX_Isond_MaxStromACLsPlc 1021 "keine_Angabe" 1022 "Init" 1023 "Fehler" ;
VAL_ 2463978775 HVLX_Isond_maxStromLadesaeule 16381 "keine_Angabe" 16382 "Init" 16383 "Fehler" ;
VAL_ 2463978775 HVLX_Isond_minStromLadesaeule 16381 "keine_Angabe" 16382 "Init" 16383 "Fehler" ;
VAL_ 2463978775 HVLX_Isond_maxSpannungLadesaeule 16381 "keine_Angabe" 16382 "Init" 16383 "Fehler" ;
VAL_ 2463978775 HVLX_Isond_minSpannungLadesaeule 16381 "keine_Angabe" 16382 "Init" 16383 "Fehler" ;
VAL_ 2463978775 HVLX_Isond_IstSpannungLadesaeule 16381 "keine_Angabe" 16382 "Init" 16383 "Fehler" ;
VAL_ 2463978775 HVLX_Isond_IstStromLadesaeule 16381 "keine_Angabe" 16382 "Init" 16383 "Fehler" ;
VAL_ 2463978775 HVLX_Isond_StromrippelPeakLs 4093 "keine_Angabe" 4094 "Init" 4095 "Fehler" ;
VAL_ 2463978775 HVLX_Isond_IstSpannungACLsPlc 509 "keine_Angabe" 510 "Init" 511 "Fehler" ;
VAL_ 2463978775 HVLX_Isond_maxLeistungLadesaeule 131069 "keine_Angabe" 131070 "Init" 131071 "Fehler" ;
VAL_ 2463978775 HVLX_Isond_maxStromErreicht 0 "Stromlimit_nicht_erreicht" 1 "Stromlimit_erreicht" 2 "Reserviert" 3 "Init" ;
VAL_ 2463978775 HVLX_Isond_maxSpannungErreicht 0 "Spannungslimit_nicht_erreicht" 1 "Spannungslimit_erreicht" 2 "Reserviert" 3 "Init" ;
VAL_ 2463978775 HVLX_Isond_maxLeistungErreicht 0 "Leistungslimit_nicht_erreicht" 1 "Leistungslimit_erreicht" 2 "Reserviert" 3 "Init" ;
VAL_ 2463978775 HVLX_Isond_NormLsPlc 0 "keine_Angabe" 1 "DIN70121_2014" 2 "ISO15118_2016" 3 "ISO15118_v2" 4 "ISO15118_20_v1" 7 "Fehler" ;
VAL_ 2463978775 HVLX_Isond_TLS_PnC_Status 0 "TLS_nicht_verwendet" 1 "TLS_ok_PrivateMode" 2 "TLS_ok_PublicMode" 3 "TLS_Failed_nicht_unterstuetzt" 4 "TLS_Failed_SECCCertChain_Unbek" 5 "TLS_Failed_SECCCertChain_Unbek" 6 "TLS_Failed_PERoot_Unbek" 7 "Reserved" ;
VAL_ 2463978775 HVLX_Isond_ResponseCodeLsPlc 0 "kein_Response_Code" 1 "OK" 2 "OK_CertificateExpiresSoon" 3 "OK_NewSessionEstablished" 4 "OK_OldSessionJoined" 5 "FAILED" 6 "FAILED_SequenceError" 7 "FAILED_SignatureError" 8 "FAILED_UnknownSession" 9 "FAILED_ServiceIDInvalid" 10 "FAILED_PaymentSelectionInvalid" 11 "FAILED_ServiceSelectionInvalid" 12 "FAILED_CertificateExpired" 13 "FAILED_CertificateRevoked" 14 "FAILED_NoCertificateAvailable" 15 "FAILED_CertChainError" 16 "FAILED_ContractCanceled" 17 "FAILED_ChallengeInvalid" 18 "FAILED_WrongEnergyTransferMode" 19 "FAILED_WrongChargeParameter" 20 "FAILED_ChargingProfileInvalid" 21 "FAILED_TariffSelectionInvalid" 22 "FAILED_PowerDeliveryNotApplied" 23 "FAILED_MeteringSignatureNotValid" 24 "FAILED_NoChargeServiceSelected" 25 "FAILED_ContactorError" 26 "FAILED_CertificateNotAllowAtEVSE" 27 "OK_GADerating" 28 "FAILED_IdentificationSelectionInvalid" 29 "FAILED_CertificateNotYetValid" 30 "FAILED_CertValidationError" 31 "FAILED_CertVerificationError" 32 "FAILED_AlignmentError" 33 "FAILED_ACDError" 34 "FAILED_AssociationError" 35 "FAILED_EVSEChargeAbort" 36 "FAILED_NoSupportedAppProtocol" 37 "FAILED_ContractNotAccepted" 38 "FAILED_MOUnknown" 39 "FAILED_OEM_Prov_CertificateRevoke" 40 "FAILED_OEM_SubCA1_CertificateRevoked" 41 "FAILED_OEM_SubCA2_CertificateRevoked" 42 "FAILED_OEM_RootCA_CertificateRevoked" 43 "FAILED_MO_Prov_CertificateRevoked" 44 "FAILED_MO_SubCA1_CertificateRevoked" 45 "FAILED_MO_SubCA2_CertificateRevoked" 46 "FAILED_MO_RootCA_CertificateRevoked" 47 "FAILED_CPS_Prov_CertificateRevoked" 48 "FAILED_CPS_SubCA1_CertificateRevoked" 49 "FAILED_CPS_SubCA2_CertificateRevoked" 50 "FAILED_CPS_RootCA_CertificateRevoked" 51 "FAILED_NoEnergyTransferServiceSe" 52 "FAILED_EVPowerProfileInvalid" 53 "OK_PowerToleranceConfirmed" 54 "Failed_PowerToleranceNotConfirme" 55 "Warning_PowerToleranceNotConfirm" 56 "Warning_EVPowerProfileViolation" 57 "Failed_EVPowerProfileViolation" 58 "FAILED_NoServiceRenegotiationSup" 59 "WARNING_StandbyNotAllowed" 60 "FAILED_GAChargeStop" 61 "FAILED_EVProfileViolation" 62 "Init" 63 "Fehler" ;
VAL_ 2463978775 HVLX_Isond_IsoStatusLadesaeule 0 "invalid" 1 "safe" 2 "warning" 3 "fault" ;
VAL_ 2463978775 HVLX_Isond_PlcKommFehler 0 "kein_Fehler" 1 "PLC_Association_nicht_moeglich" 2 "SDP_Fehler" 3 "TCP_IP_Fehler" 4 "V2G_Fehler" 5 "Timeout Request Response" 6 "Reserviert" 7 "Init" ;
VAL_ 2463978775 HVLX_ISOND_LOPStatus 0 "false" 1 "true" ;
VAL_ 2463978775 HVLX_ISOND_FODStatus 0 "false" 1 "true" ;
VAL_ 2463978775 HVLX_Isond_LadeartAC1PCorePlc 0 "nicht_Vorhanden" 1 "Vorhanden" ;
VAL_ 2463978775 HVLX_Isond_LadeartAC3PCorePlc 0 "nicht_Vorhanden" 1 "Vorhanden" ;
VAL_ 2463978775 HVLX_Isond_LadeartDCComboCorePlc 0 "nicht_Vorhanden" 1 "Vorhanden" ;
VAL_ 2463978775 HVLX_Isond_LadeartDCCorePlc 0 "nicht_Vorhanden" 1 "Vorhanden" ;
VAL_ 2463978775 HVLX_Isond_LadeartDCExtendedPlc 0 "nicht_Vorhanden" 1 "Vorhanden" ;
VAL_ 2463978775 HVLX_Isond_LadeartDCUniquePlc 0 "nicht_Vorhanden" 1 "Vorhanden" ;
VAL_ 2463978775 HVLX_Isond_ZahlungsmethodeLs 0 "Vertrag" 1 "externe_Bezahlung" 2 "Vertrag_und_externe_Bezahlung" 3 "Init" ;
VAL_ 2463978775 HVLX_Isond_StatusRcdACLsPlc 0 "keine_Angabe" 1 "kein_Fehler" 2 "Fehler_RCD" ;
VAL_ 2463978775 HVLX_Isond_ZahlererfassungAnfHlc 0 "keine_Anforderung" 1 "Anforderung" ;
VAL_ 2463978775 HVLX_Isond_PLC_Message_Status 0 "keine_Information" 1 "TCPIPConnection_OK" 2 "TCPIPConnection_fehlgeschlagen" 3 "SDP_OK" 4 "SDP_fehlgeschlagen" 5 "SupportedAppProtocol_OK" 6 "SupportedAppProtocol_Fehler" 7 "SessionSetupRes_OK" 8 "SessionSetupRes_fehlgeschlagen" 9 "ServiceDiscoveryRes_OK" 10 "ServiceDiscoveryRes_Fehler" 11 "ServicePaymanetSelectionRes_OK" 12 "ServicePaymanSelectionRes_Fehler" 13 "ContractAuthenticationRes_OK" 14 "ContractAuthenticationRes_Fehler" 15 "ChargeParameterDiscoveryRes_OK" 16 "ChargeParametDiscoveryRes_Fehler" 17 "CableCheckRes_OK" 18 "CableCheckRes_Fehler" 19 "PreChargeRes_OK" 20 "PreChargeRes_Fehler" 21 "PowerDeliveryRes_Ok" 22 "PowerDeliveryRes_Fehler" 23 "CurrentDemandRes_OK" 24 "CurrentDemandRes_fehlgeschlagen" 25 "WeldingDetectionRes_OK" 26 "WeldingDetectionRes_fehlgeschl" 27 "SessionStopRes_OK" 28 "SessionStopRes_fehlgeschlagen" 29 "StopCommunicationSession_OK" 30 "ServiceSelectionRes_OK" 31 "ServiceSelectionRes_fehlgesclagen" 32 "AuthorizationRes_OK" 33 "AuthoorizationRes_fehlgeschlagen" 50 "FinePositioningSetupRes_OK" 51 "FinePositioningSetupRes_Fehler" 52 "FinePositioningRes_OK" 53 "FinePositioningRes_fehlgeschlagen" 54 "PairingRes_OK" 55 "PairingRes_fehlgeschlagen" 56 "AlignmentCheckRes_OK" 57 "AlignmentCheckRes_fehlgeschlagen" 58 "PowerDemandRes_Ok" 59 "PowerDemandRes_fehlgeschlagen" 60 "AuthorizationSetupRes_OK" 61 "AuthorizationSetupRes_fehlgeschl" 62 "DC_ChargeLoopRes_OK" 63 "DC_ChargeLoopRes_fehlgeschlagen" 101 "ServiceDetailsRes_OK" 102 "ServiceDetailsRes_fehlgeschlagen" 105 "IdentificationDetailRes_OK" 106 "IdentificationDetailRes_fehlgeschlagen" 121 "CertificateUpdateRes_OK" 122 "CertificateUpdateRes_fehlgeschl" 123 "CertificateInstalRes_OK" 124 "CertificateInstalRes_fehlgeschl" 125 "PaymentDetailsRes_OK" 126 "PaymentDetailsRes_fehlgeschlagen" 241 "ChargingStatusRes_OK" 242 "ChargingStatusRes_fehlgeschlagen" 243 "MeteringReceiptRes_OK" 244 "MeteringReceiptRes_fehlgeschlage" ;
VAL_ 2463978775 HVLX_Isond_IstEnergiemengeLsPlc 8189 "keine_Angabe" 8190 "Init" 8191 "Fehler" ;
VAL_ 2463978775 HVLX_Isond_PnCZertifkatErhaltHlc 0 "Nicht_Vorhanden" 1 "Vorhanden" 3 "Fehler" ;
VAL_ 2463978775 HVLX_Isond_LadeplanErhaltenHlc 0 "nicht_Vorhanden" 1 "Vorhanden" 3 "Fehler" ;
VAL_ 2463978775 HVLX_Isond_SASTupelErhaltenHlc 0 "nicht_Vorhanden" 1 "Vorhanden" 2 "keine_Unterstuetzung_Ladesauele" 3 "Fehler" ;
VAL_ 2463978775 HVLX_Isond_StatusLadesaeule 0 "EVSE_NotReady" 1 "EVSE_Ready" 2 "EVSE_Shutdown" 3 "EVSE_UtilityInterruptEvent" 4 "EVSE_IsolationMonitoringActive" 5 "EVSE_EmergencyShutdown" 6 "EVSE_Malfunction" 7 "Reserviert_8" 8 "Reserved_9" 9 "Reserved_A" 10 "Reserved_B" 11 "Reserved_C" 12 "Reserviert" 13 "Reserviert" 14 "Init" 15 "Fehler" ;
VAL_ 2463978775 HVLX_Isond_EigenstromLadenStatus 0 "keine_Angabe" 1 "kein_Eigenstromdienst_verfuegbar" 2 "kein_Eigenstrom_verfuegbar" 3 "Eigenstrom_verfuegbar" ;
VAL_ 2463978775 HVLX_Isond_EVSEProcessing_Status 0 "keine_Angabe" 1 "Finished" 2 "Ongoing" 3 "OngoingWaitingForCustomerInterac" 4 "Processing" ;
VAL_ 2463978775 HVLX_Isond_VASBedAnzStatus_LsPlc 0 "nicht_verfuegbar" 1 "verfuegbar" ;
VAL_ 2463978775 HVLX_Isond_VASErwLFStatus_LsPlc 0 "nicht_verfuegbar" 1 "verfuegbar" ;
VAL_ 2463978775 HVLX_LSPLC_01_Sendestatus 0 "Senden_im_langsamen_Zyklus" 1 "Senden_im_schnellen_Zyklus" ;
VAL_ 2463978775 HVLX_PlcFehlerstatus 0 "kein_Fehler" 1 "Fehler_PLC_Modul" 2 "keine_PLC_Ladesaeule_gefunden" 3 "PLC_DatenLink_Fehler" 4 "PLC_Kommunikationsabbruch" 5 "Signaldaempfung_zu_hoch" 6 "Fehler_Ladesaeulenvalidierung" 7 "Init" ;
VAL_ 2463978775 HVLX_PlcLinkStatus 0 "keine_Verbindung_zur_Ladesaeule" 1 "SLAC_aktiv_suche_Ladesaeule" 2 "SLAC_aktiv_validiere_Ladesaeule" 3 "SLAC_aktiv_Einrichtung_Netzwerk" 4 "Aktive_Verbindung_zur_Ladesaeule" 5 "Pruefe_PLC_Link" 6 "Init" 7 "Fehler" ;
VAL_ 2463978775 HVLX_Isond_LsNotification_Plc 0 "keine_Angabe" 1 "Ladevorgang_stoppen" 2 "Neuverhandlung" 3 "Pause" 4 "MeteringReceipt" 5 "ServiceRenegotiation" 6 "Terminate" ;
VAL_ 2463978775 HVLX_ISOND_GALeistungNetz 4093 "keine_Angabe" 4094 "Init" 4095 "Fehler" ;
VAL_ 2463978775 HVLX_ISOND_GAFrequenz 16381 "keine_Angabe" 16382 "Init" 16383 "Fehler" ;
VAL_ 2463978775 HVLX_ISOND_GADcLeistung 4093 "keine_Angabe" 4094 "Init" 4095 "Fehler" ;
VAL_ 2463978775 HVLX_ISOND_GASpulenstrom 1021 "keine_Angabe" 1022 "Init" 1023 "Fehler" ;
VAL_ 2463978775 HVLX_ISOND_LeistungsanfEV 4093 "keine_Angabe" 4094 "Init" 4095 "Fehler" ;
VAL_ 2463978775 HVLX_ISOND_EVSEResponseMaxDelay 65534 "Init" 65535 "Fehler" ;
VAL_ 2463978775 HVLX_Isond_WPT_VehiclePosStatus 0 "VehiclePosNichtOk" 1 "VehiclePosOk" ;
VAL_ 2463978775 HVLX_Isond_WPT_DevicePosStatus 0 "DevicePosNichtOk" 1 "DevicePosOk" ;
VAL_ 2463978775 HVLX_Isond_LadeartWpt 0 "Nicht_vorhanden" 1 "Vorhanden" ;
VAL_ 2463978775 HVLX_ISOND_PncServiceDetailStat 0 "nicht_verfuegbar" 1 "Installation_verfuegbar" 2 "Update_verfuegbar" 3 "Installation_Update_verfuegbar" ;
VAL_ 2463978775 HVLX_ISOND_PncServiceDiscovStat 0 "nicht_vorhanden" 1 "vorhanden" 3 "Fehler" ;
VAL_ 2463978775 HVLX_ISOND_PncZertifikateTrans 0 "nicht_uebertragen" 1 "uebertragen" 3 "Fehler" ;
VAL_ 2463978775 HVLX_maxEntladeLeistungLS 131070 "InitWert" ;
VAL_ 2463978775 HVLX_minEntladeStromLadesaeule 16382 "Init" 16383 "Fehler" ;
VAL_ 2463978775 HVLX_maxEntladeStromLadesaeule 16382 "Init" 16383 "Fehler" ;
VAL_ 2463978775 HVLX_GeneratorMode 0 "nicht_bekannt_init" 1 "GridFollowing" 2 "GridForming" ;
VAL_ 2463978775 HVLX_LadeartDCBptPlc 0 "unbekannt_init" 1 "DC_BPT_nicht_vorhanden" 2 "DC_BPT_vorhanden" ;
VAL_ 2463978775 HVLX_Isond_TlsZertifkatErhaltHlc 0 "Nicht_Vorhanden" 1 "Vorhanden" 3 "Fehler" ;
VAL_ 2463978775 HVLX_Isond_VasResponse 0 "Init" 1 "IP_address_correctly_received" 2 "VAS_connection_success" 3 "Gen_EV_parameters_success" 4 "Add_EV_charge_parameters_success" 5 "VAS_EVSE_charge_param_received" 6 "PowerDelivery_start_acknowledged" 7 "PowerDelivery_stop_acknowledged" 8 "PowerDelivery_renegotiate_acknow" 9 "Actual_current_limits_received" 10 "Prep_to_close_HTTP_connec_acknow" 11 "HTTP_connection_success_closed" 12 "Reserve" 13 "Reserve" 14 "Reserve" 15 "Reserve" 16 "Reserve" 17 "IP_address_not_correctly_receive" 18 "VAS_connection_setup_failed" 19 "Gen_EV_parameters_failed" 20 "Add_EV_charge_parameters_failed" 21 "VAS_EVSE_charge_param_not_receiv" 22 "Err_process_PowerDelivery_start" 23 "Err_process_PowerDelivery_stop" 24 "Err_process_PowerDelivery_renego" 25 "Actual_current_limits_not_receiv" 26 "Prep_to_close_HTTP_connec_failed" 27 "HTTP_closing_connection_failed" 28 "Reserve" 29 "Reserve" 30 "Temporary_VAS_error_OCC_failure" 31 "Permanent_VAS_error_OCC_failure" ;
VAL_ 792 Kamera_Systemzustand 0 "Kamera_operativ" 1 "Kamera_Initialisierung" 2 "Kamera_schaltet_ab" 3 "Kamera_Fehler" ;
VAL_ 792 Kamera_FDD_Eigenblend_Guete 14 "Init" 15 "Fehler" ;
VAL_ 792 Kamera_FDD_Eigenblend 0 "Keine_Eigenblendung_erkannt" 1 "Eigenblendung_erkannt" ;
VAL_ 792 Kamera_FDD_Strassenbeleuchung 0 "keine_Strassenbeleuchtung" 1 "Strassenbeleuchtung" 2 "Strassenleuchte" 3 "nicht_verfuegbar" ;
VAL_ 792 Kamera_FDD_Funktionsstatus 0 "FDD_ein_aktiv" 1 "FDD_ein_passiv" 2 "FDD_ein_Einschraenkung_Sicht" 3 "FDD_ein_Fehler_HW_SW" 4 "FDD_aus" 6 "Init" ;
VAL_ 792 Kamera_FDD_Anz_Strassenleuchten 15 "Init" ;
VAL_ 792 Kamera_FDD_Verkehrsrichtung 0 "rechtsverkehr" 1 "linksverkehr" 2 "Init" 3 "nicht verfuegbar" ;
VAL_ 792 Kamera_Helligkeit 1022 "Init" 1023 "Fehler" ;
VAL_ 792 VZE_Status_EDR 0 "Commanded_Off" 1 "On_but_Not_ControllingOrWarning" 2 "Actively_Warning" 3 "Actively_Controlling" 4 "Driver_Override" 5 "Faulted" ;
VAL_ 792 Kamera_FSH_aktiv 0 "Kamera_Frontscheibenheizung_nicht_aktiviert" 1 "Kamera_Frontscheibenheizung_aktiviert" ;
VAL_ 960 RSt_Fahrerhinweise 0 "Init" 1 "Fahreruebernahme_Hinweis_ZAT_Automat_ohne_Gong" 2 "Fahreruebernahme_Hinweis_ZAT_Automat_mit_Gong" 3 "Fahreruebernahme_Hinweis_ZAT_Handschalter_ohne_Gong" 4 "Fahreruebernahme_Hinweis_ZAT_Handschalter_mit_Gong" 5 "Fahreruebernahme_Hinweis_ZAS_Automat_ohne_Gong" 6 "Fahreruebernahme_Hinweis_ZAS_Automat_mit_Gong" 7 "Fahreruebernahme_Hinweis_ZAS_Handschalter_ohne_Gong" 8 "Fahreruebernahme_Hinweis_ZAS_Handschalter_mit_Gong" 9 "RemoteStart_aktiv_ohne_Gong" 10 "RemoteStart_aktiv_mit_Gong" 11 "void" 12 "void" 13 "void" 14 "void" 15 "void" ;
VAL_ 960 ZAS_Kl_S 0 "aus" 1 "S_Kontakt_ein" ;
VAL_ 960 ZAS_Kl_15 0 "aus" 1 "ein" ;
VAL_ 960 ZAS_Kl_X 0 "aus" 1 "ein" ;
VAL_ 960 ZAS_Kl_50_Startanforderung 0 "aus" 1 "KL50_ein_Startwunsch_Fahrer" ;
VAL_ 960 BCM_Remotestart_Betrieb 0 "kein_RS_Betrieb" 1 "RS_Betrieb" ;
VAL_ 960 ZAS_Kl_Infotainment 0 "inaktiv" 1 "aktiv" ;
VAL_ 960 BCM_Remotestart_KL15_Anf 0 "inaktiv" 1 "aktiv" ;
VAL_ 960 BCM_Remotestart_MO_Start 0 "nicht_angefordert" 1 "angefordert" ;
VAL_ 960 KST_Warn_P1_ZST_def 0 "nicht_defekt" 1 "defekt" ;
VAL_ 960 KST_Warn_P2_ZST_def 0 "nicht_defekt" 1 "defekt" ;
VAL_ 960 KST_Fahrerhinweis_1 0 "inaktiv" 1 "aktiv" ;
VAL_ 960 KST_Fahrerhinweis_2 0 "inaktiv" 1 "aktiv" ;
VAL_ 960 BCM_Ausparken_Betrieb 0 "kein_Betrieb" 1 "Ausparkvorgang_aktiv" ;
VAL_ 960 KST_Fahrerhinweis_4 0 "inaktiv" 1 "aktiv" ;
VAL_ 960 KST_Fahrerhinweis_5 0 "inaktiv" 1 "aktiv" ;
VAL_ 960 KST_Fahrerhinweis_6 0 "inaktiv" 1 "aktiv" ;
VAL_ 2463978753 KST_WFS_Fahrfreigabe_Anforderung 0 "Keine" 1 "Uneingeschraenkt" 2 "Eingeschraenkt" ;
VAL_ 2463978753 KST_Sonderzustand_Status 0 "Init" 1 "Uebergang_neue_Anforderung" 2 "Aktiv" 3 "Fehler" ;
VAL_ 2463978753 KST_Sonderzustand_Anforderung 0 "Init" 1 "RemoteStart" 2 "RemoteParkAssist" 3 "IntelligentParkAssist" 4 "TrainiertesParken" 5 "OnlineRemoteUpdate" 6 "Einfrierschutz" 7 "Klemme15ViaDiagnose" 8 "RueckwandklappenSicherungPDC" 9 "ParkHausPilot" 10 "AnhaengerAnkuppelAssistent" 11 "MotorWeiterlaufSchaltung" 31 "Fehler" ;
VAL_ 2463978753 KST_ComfortReadyStatus 0 "aus" 1 "ComfortReadyStatus_ein" ;
VAL_ 2463978753 KST_Freigabe_Zustand 0 "Init" 1 "Kl50_freigegeben" 2 "Kl50_gesperrt" ;
VAL_ 1646 KL_STL_aktiv 0 "Standlueftung_nicht_aktiv" 1 "Standlueftung_aktiv" ;
VAL_ 1646 KL_STH_aktiv 0 "Standheizung_nicht_aktiv" 1 "Standheizung_aktiv" ;
VAL_ 1646 KL_Solarluefter_aktiv 0 "Solarluefter_nicht_aktiv" 1 "Solarluefter_aktiv__auto" ;
VAL_ 1646 KL_Umluft_Taste 0 "Taste_nicht_gedrueckt" 1 "Taste_gedrueckt" ;
VAL_ 1646 KL_Geblaese_Fond_Status 0 "Geblaese_aus" 1 "Geblaesestufe_10" 2 "Geblaesestufe_20" 3 "Geblaesestufe_30" 4 "Geblaesestufe_40" 5 "Geblaesestufe_50" 6 "Geblaesestufe_60" 7 "Geblaesestufe_70" 8 "Geblaesestufe_80" 9 "Geblaesestufe_90" 10 "Geblaesestufe_100" 14 "Init" 15 "Fehler" ;
VAL_ 1646 KL_STH_Ansteuerung 0 "Aus" 1 "Ein" 2 "Ein_mit_Motorvorwaermung" 3 "Heizleistung_reduziert" ;
VAL_ 1646 KL_Magnetventil 0 "Aus" 1 "Ein" ;
VAL_ 1646 KL_WaPu 0 "Wasserpumpe_aus" 1 "Wasserpumpe_aktiv" ;
VAL_ 1646 KL_Geblaese_Status 0 "Geblaese_aus" 1 "Geblaesestufe_10" 2 "Geblaesestufe_20" 3 "Geblaesestufe_30" 4 "Geblaesestufe_40" 5 "Geblaesestufe_50" 6 "Geblaesestufe_60" 7 "Geblaesestufe_70" 8 "Geblaesestufe_80" 9 "Geblaesestufe_90" 10 "Geblaesestufe_100" 14 "Init" 15 "Fehler" ;
VAL_ 1646 KL_Restwaerme_aktiv 0 "inaktiv" 1 "aktiv" ;
VAL_ 1646 KL_Kompressorkupplung 0 "oeffnen" 1 "schliessen" ;
VAL_ 1646 KL_BCmE_Livetip_Freigabe 0 "Anzeige_Livetip_nicht_zulaessig" 1 "Anzeige_Livetip_zulaessig" ;
VAL_ 1646 KL_ErwVK_Anf 0 "nicht_angefordert" 1 "angefordert" ;
VAL_ 1646 KL_Innen_Temp 253 "nicht_verbaut" 254 "nicht_verfuegbar" 255 "Fehler" ;
VAL_ 1646 KL_I_Geblaese_Fond 255 "Fehler" ;
VAL_ 1646 KL_Anf_AussenspiegelHzg 0 "nicht_angefordert" 1 "angefordert" ;
VAL_ 1646 KL_Heizkreisventilstellung 0 "Init" 1 "Ventilstellung_gem_Anforderung" 2 "Ventilstellung_abweichend_Anf" 3 "Fehler" ;
VAL_ 1646 KL_FSH_Automatikbetrieb 0 "aus" 1 "angefordert_durch_Regelung" ;
VAL_ 1646 KL_SIH_LEH_Verteilung_VL 0 "gleichmaessige_Verteilung" 1 "Sitz_Prio_Hoch" 2 "Sitz_Prio_Mittel" 3 "Sitz_Prio_Niedrig" 4 "Lehne_Prio_Niedrig" 5 "Lehne_Prio_Mittel" 6 "Lehne_Prio_Hoch" ;
VAL_ 1646 KL_SIH_LEL_Verteilung_VL 0 "gleichmaessige_Verteilung" 1 "Sitz_Prio_Hoch" 2 "Sitz_Prio_Mittel" 3 "Sitz_Prio_Niedrig" 4 "Lehne_Prio_Niedrig" 5 "Lehne_Prio_Mittel" 6 "Lehne_Prio_Hoch" ;
VAL_ 1646 KL_SIH_LEH_Verteilung_VR 0 "gleichmaessige_Verteilung" 1 "Sitz_Prio_Hoch" 2 "Sitz_Prio_Mittel" 3 "Sitz_Prio_Niedrig" 4 "Lehne_Prio_Niedrig" 5 "Lehne_Prio_Mittel" 6 "Lehne_Prio_Hoch" ;
VAL_ 1646 KL_SIH_LEL_Verteilung_VR 0 "gleichmaessige_Verteilung" 1 "Sitz_Prio_Hoch" 2 "Sitz_Prio_Mittel" 3 "Sitz_Prio_Niedrig" 4 "Lehne_Prio_Niedrig" 5 "Lehne_Prio_Mittel" 6 "Lehne_Prio_Hoch" ;
VAL_ 1649 KL_ZZ_Status_Timer 0 "Timer_n_aktiv_bzw_loeschen" 1 "Timer_aktiv_bzw_aktivieren" ;
VAL_ 1649 KL_ZZ_Monat 0 "Init" ;
VAL_ 1649 KL_ErwVK_Scheibenheizung 0 "nicht_aktiv" 1 "Scheibenheizung_aktiv" ;
VAL_ 1649 KL_ErwVK_Heckzone2_links 0 "nicht_angefordert" 1 "Heckzone2_rechts_angefordert" ;
VAL_ 1649 KL_ErwVK_Heckzone2_rechts 0 "nicht_angefordert" 1 "Heckzone2_rechts_angefordert" ;
VAL_ 1649 KL_ZZ_Betriebsmodus 0 "Do_not_Care" 1 "ECO" 2 "Standard" 3 "Standard_plus" 4 "Comfort" ;
VAL_ 1649 KL_ZZ_Tag 0 "Init" ;
VAL_ 1649 KL_Betriebsmodus_FH 0 "undefined__init" 1 "Klemme15" 2 "Standheizung" 3 "Restwaerme" 4 "Nachlauf" 5 "Standlueften" 6 "Betriebsart_X" 7 "Betriebsart_Y" ;
VAL_ 1649 KL_Stopp_Wiederstart_Anz_01 0 "keine_Anzeige" 1 "Geblaese" ;
VAL_ 1649 KL_Stopp_Wiederstart_Anz_02 0 "keine_Anzeige" 1 "Differenz_Soll_Ausblas_zu_Ist_Ausblastemperatur" ;
VAL_ 1649 KL_Stopp_Wiederstart_Anz_03 0 "keine_Anzeige" 1 "Beschlagsgefahr" ;
VAL_ 1649 KL_Stopp_Wiederstart_Anz_04 0 "keine_Anzeige" 1 "Differenz_Soll_Innentemperatur_zu_Ist_Innenraumtemperatur" ;
VAL_ 1649 KL_Stopp_Wiederstart_Anz_05 0 "keine_Anzeige" 1 "Komfortfeuchte" ;
VAL_ 1649 KL_Stopp_Wiederstart_Anz_06 0 "keine_Anzeige" 1 "Aussentemperatur" ;
VAL_ 1649 KL_Stopp_Wiederstart_Anz_07 0 "keine_Anzeige" 1 "Defrost" ;
VAL_ 1649 KL_Stopp_Wiederstart_Anz_08 0 "keine_Anzeige" 1 "High_Low" ;
VAL_ 1649 KL_Stopp_Wiederstart_Anz_09 0 "keine_Anzeige" 1 "Frontscheibenheizung" ;
VAL_ 1649 KL_Stopp_Wiederstart_Anz_Std1 0 "keine_Anzeige" 1 "maxA/C" ;
VAL_ 1649 KL_Stopp_Wiederstart_Anz_Std2 0 "keine_Anzeige" 1 "Sitzlueftung" ;
VAL_ 1649 KL_Meldung_Status 0 "keine_notification" 1 "Klima_eingeschraenkt" 2 "Klima_Warnung" 3 "Service_Klima" 4 "Fahrzeug_Lueften_Gelb" 5 "Fahrzeug_Lueften_Rot" 6 "Fahrzeug_Lueften_3" 7 "Klima_Abwurf" 8 "reserve_1" 9 "reserve_2" ;
VAL_ 1649 KL_ErwVK_Status 0 "nicht_angefordert" 1 "Fahrerzone_aktiv" 2 "Beifahrerzone_aktiv" 3 "Heckzone_links_aktiv" 4 "Heckzone_recht_aktiv" 5 "Scheibenheizung_aktiv" ;
VAL_ 1649 KL_Hinweis_Kuehlmodus 0 "aus" 1 "Stufe1" 2 "Stufe2" 3 "Stufe3" ;
VAL_ 1649 KL_ErwVK_Beifahrerzone 0 "nicht_aktiv" 1 "Beifahrerzone_aktiv" ;
VAL_ 1649 KL_ErwVK_Fahrerzone 0 "nicht_aktiv" 1 "Fahrerzone_aktiv" ;
VAL_ 1649 KL_ErwVK_Heckzone_links 0 "nicht_aktiv" 1 "Heckzone_links_aktiv" ;
VAL_ 1649 Kl_ErwVK_Heckzone_rechts 0 "nicht_aktiv" 1 "Heckzone_rechts_aktiv" ;
VAL_ 949 KL_Drehz_Anh 0 "keine_Anhebung" 1 "Drehzahlanhebung_vom_Motor_angefordert" ;
VAL_ 949 KL_Vorwarn_Komp_ein 0 "Init" 1 "Vorwarnung_Kompressor_ein" ;
VAL_ 949 KL_AC_Schalter 0 "aus" 1 "ein" ;
VAL_ 949 KL_Komp_Moment_alt 1 "veraltet_bzw_Ermittlung_des_Moments_nicht_moeglich__zB_keine_Drehzahl_kein_Kaeltemitteldruck" ;
VAL_ 949 KL_Vorwarn_Zuheizer_ein 0 "keine_Vorwarnung" 1 "Vorwarnung_Zuheizer_ein" ;
VAL_ 949 KL_Zustand 0 "Aus" 1 "Ein" ;
VAL_ 949 KL_Kompressorkupplung_linear 253 "volle_Ansteuerung" 254 "Init__nicht_bedient" ;
VAL_ 949 KL_Charisma_FahrPr 0 "keine_Funktion" 1 "Programm_1" 2 "Programm_2" 3 "Programm_3" 4 "Programm_4" 5 "Programm_5" 6 "Programm_6" 7 "Programm_7" 8 "Programm_8" 9 "Programm_9" 10 "Programm_10" 11 "Programm_11" 12 "Programm_12" 13 "Programm_13" 14 "Programm_14" 15 "Programm_15" ;
VAL_ 949 KL_Charisma_Status 0 "Init" 1 "verfuegbar" 2 "nicht_verfuegbar" 3 "asynchron_durch_Fahrerwunsch" ;
VAL_ 949 KL_nachtr_Stopp_Anf 0 "nicht_angefordert" 1 "angefordert" ;
VAL_ 949 KL_T_Charge 0 "Taster_nicht_betaetigt" 1 "Taster_betaetigt" ;
VAL_ 949 KL_Last_Kompr 255 "Fehler" ;
VAL_ 949 KL_Spannungs_Anf 0 "keine_Anforderung" 1 "Anforderung_Stufe_1" 2 "Anforderung_Stufe_2" 3 "Anforderung_Stufe_3" ;
VAL_ 949 KL_Thermomanagement 0 "keine_Freigabe_TMM__max_Heizbedarf" 1 "kleine_Freigabe_TMM" 2 "mittlere_Freigabe_TMM" 3 "volle_Freigabe_TMM__kein_Heizbedarf" ;
VAL_ 949 KL_StartStopp_Info 0 "Motorlauf_nicht_notwendig_(Stoppfreigabe)" 1 "Motoranlauf_nicht_zwingend_notwendig_(Stoppverbot,keine_Startanforderung)" 2 "Motoranlauf_zwingend_notwendig_(Startanforderung)" 3 "Systemfehler" ;
VAL_ 949 KL_Freilauf_Info 0 "Freilauf_freigegeben" 1 "Uebergang_in_Freilauf_unzulaessig" 2 "Freilauf_nicht_freigegeben_Abbruch" 3 "Freilauf_Anforderung" ;
VAL_ 949 KL_Anf_KL 255 "Fehler" ;
VAL_ 949 KL_el_Zuheizer_Stufe 0 "Aus" 1 "Stufe_1" 2 "Stufe_2" 3 "Stufe_3" ;
VAL_ 949 KL_Ausstattung_Klima 0 "Heizung_elektrisch" 1 "Klimamanuell_elektrisch" 2 "Climatic__1_Zone" 3 "Climatronic__1_Zone" 4 "Climatronic__2_Zonen" 5 "Climatronic__3_Zonen" 6 "Climatronic__4_Zonen" 7 "reserviert" ;
VAL_ 949 KL_Variante_Standheizung 0 "Wasserstandheizung_60_min_Laufzeit" 1 "Luftstandheizung_120_min_Laufzeit" 2 "Wasserstandheizung_120_min_Laufzeit" 3 "Wasser_und_Luftstandheizung_120_min_Laufzeit" ;
VAL_ 949 KL_AirCleaner_aktiv 0 "AirCleaner_nicht_aktiv" 1 "AirCleaner_aktiv" ;
VAL_ 949 KL_Anf_KV 126 "Init" ;
